VERSION ""

NS_ :

BS_:

BU_: VMM IMR BCS GSM EMS EPB SRS TEL ICM ACU VCU WCM TSCM Tester Test SCMRR SCMRL SCM SBM RCP PSDR PSDL PLGM PAS LCU IHU IBCM IAL HVSPRR HVSPRL HVSMR HVSM HVACF HUD GWM FRDCM FLDCM FCP FAPA ETC Diagnostic Messages AVAS AMP

BO_ 1015 ACU_HVSM_2_B: 8 IHU
 SG_ ACU_RRSeatOperationReq : 63|4@0+ (1,0) [0|15] "-"  SCMRL
 SG_ ACU_RRSeatOperationReqVD : 53|1@0+ (1,0) [0|1] "-"  SCMRL
 SG_ ACU_RLSeatOperationReqVD : 52|1@0+ (1,0) [0|1] "-"  SCMRL
 SG_ ACU_RLSeatOperationReq : 51|4@0+ (1,0) [0|15] "-"  SCMRL
 SG_ ACU_HVSMR_RRSeatHeatVentModeSt : 47|2@0+ (1,0) [0|3] "-"  HVSMR,SCMRL,HVSM
 SG_ ACU_HVSMR_RRSeatVentLevelReq : 45|3@0+ (1,0) [0|7] "-"  HVSMR,SCMRL,HVSM
 SG_ ACU_HVSMR_RRSeatHeatLevelReq : 42|3@0+ (1,0) [0|7] ""  HVSMR,SCMRL,HVSM
 SG_ ACU_HVSMR_RLSeatHeatVentModeSt : 39|2@0+ (1,0) [0|3] "-"  HVSMR,SCMRL,HVSM
 SG_ ACU_HVSMR_RLSeatVentLevelReq : 37|3@0+ (1,0) [0|7] "-"  HVSMR,SCMRL,HVSM
 SG_ ACU_HVSMR_RLSeatHeatLevelReq : 34|3@0+ (1,0) [0|7] ""  HVSMR,SCMRL,HVSM
 SG_ ACU_ORVMOperationReqVD : 31|1@0+ (1,0) [0|1] ""  FLDCM,FRDCM
 SG_ ACU_SeatSteeringWheelOpratReqVD : 30|1@0+ (1,0) [0|1] ""  SCM
 SG_ ACU_SVM_Button : 29|1@0+ (1,0) [0|1] ""  FAPA,GWM
 SG_ ACU_APA_Button : 28|1@0+ (1,0) [0|1] ""  FAPA,GWM
 SG_ ACU_ORVMOperationReq : 23|4@0+ (1,0) [0|15] "-"  FLDCM,FRDCM
 SG_ ACU_SeatSteeringWheelOpratReq : 19|4@0+ (1,0) [0|15] "-"  SCM
 SG_ ACU_HVSM_FRSeatHeatVentModeSt : 15|2@0+ (1,0) [0|3] "-"  SCM,HVSM
 SG_ ACU_HVSM_FRSeatVentLevelReq : 13|3@0+ (1,0) [0|7] "-"  SCM,HVSM
 SG_ ACU_HVSM_FRSeatHeatLevelReq : 10|3@0+ (1,0) [0|7] ""  HVSM
 SG_ ACU_HVSM_FLSeatHeatVentModeSt : 7|2@0+ (1,0) [0|3] "-"  SCM,HVSM
 SG_ ACU_HVSM_FLSeatVentLevelReq : 5|3@0+ (1,0) [0|7] "-"  SCM,HVSM
 SG_ ACU_HVSM_FLSeatHeatLevelReq : 2|3@0+ (1,0) [0|7] ""  SCM,HVSM

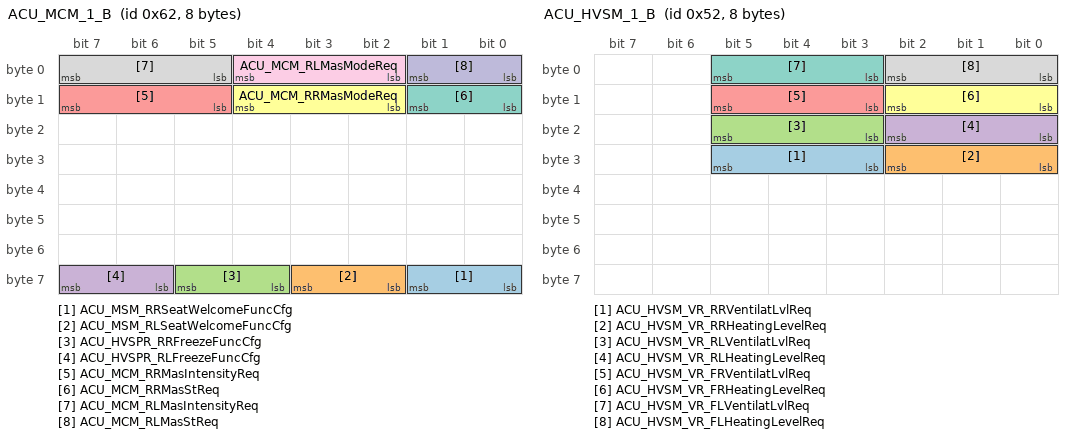
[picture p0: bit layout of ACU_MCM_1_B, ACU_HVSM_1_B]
BO_ 98 ACU_MCM_1_B: 8 IHU
 SG_ ACU_MSM_RRSeatWelcomeFuncCfg : 57|2@0+ (1,0) [0|3] ""  SCMRR
 SG_ ACU_MSM_RLSeatWelcomeFuncCfg : 59|2@0+ (1,0) [0|3] ""  SCMRL
 SG_ ACU_HVSPR_RRFreezeFuncCfg : 61|2@0+ (1,0) [0|3] ""  HVSPRR
 SG_ ACU_HVSPR_RLFreezeFuncCfg : 63|2@0+ (1,0) [0|3] ""  HVSPRL
 SG_ ACU_MCM_RRMasIntensityReq : 15|3@0+ (1,0) [0|7] "" Vector__XXX
 SG_ ACU_MCM_RRMasModeReq : 12|3@0+ (1,0) [0|7] "" Vector__XXX
 SG_ ACU_MCM_RRMasStReq : 9|2@0+ (1,0) [0|3] "" Vector__XXX
 SG_ ACU_MCM_RLMasIntensityReq : 7|3@0+ (1,0) [0|7] "" Vector__XXX
 SG_ ACU_MCM_RLMasModeReq : 4|3@0+ (1,0) [0|7] "" Vector__XXX
 SG_ ACU_MCM_RLMasStReq : 1|2@0+ (1,0) [0|3] "" Vector__XXX

BO_ 82 ACU_HVSM_1_B: 8 IHU
 SG_ ACU_HVSM_VR_RRVentilatLvlReq : 29|3@0+ (1,0) [0|7] "-"  HVSMR,SCMRL
 SG_ ACU_HVSM_VR_RRHeatingLevelReq : 26|3@0+ (1,0) [0|7] "-"  HVSMR,SCMRL
 SG_ ACU_HVSM_VR_RLVentilatLvlReq : 21|3@0+ (1,0) [0|7] "-"  HVSMR,SCMRL
 SG_ ACU_HVSM_VR_RLHeatingLevelReq : 18|3@0+ (1,0) [0|7] "-"  HVSMR,SCMRL
 SG_ ACU_HVSM_VR_FRVentilatLvlReq : 13|3@0+ (1,0) [0|7] "-"  SCM,HVSM
 SG_ ACU_HVSM_VR_FRHeatingLevelReq : 10|3@0+ (1,0) [0|7] "-"  SCM,HVSM
 SG_ ACU_HVSM_VR_FLVentilatLvlReq : 5|3@0+ (1,0) [0|7] "-"  SCM,HVSM
 SG_ ACU_HVSM_VR_FLHeatingLevelReq : 2|3@0+ (1,0) [0|7] "-"  SCM,HVSM

BO_ 836 ACU_PCS_1_B: 8 IHU
 SG_ PCS_MMIAPAFuncSelect : 63|2@0+ (1,0) [0|3] "" Vector__XXX
 SG_ PCS_MMIAPAConfirmButton : 61|2@0+ (1,0) [0|3] "" Vector__XXX
 SG_ PCS_PASButtonPress : 59|1@0+ (1,0) [0|1] ""  PAS
 SG_ PCS_ER_QuitReq : 58|1@0+ (1,0) [0|1] "" Vector__XXX
 SG_ PCS_ER_EnterConfirm : 57|1@0+ (1,0) [0|1] "" Vector__XXX
 SG_ PCS_ACU_DisplayReq : 56|1@0+ (1,0) [0|1] "" Vector__XXX
 SG_ PCS_SoundReminderSt : 55|1@0+ (1,0) [0|1] "" Vector__XXX
 SG_ PCS_BCM_ButtonLamp : 54|1@0+ (1,0) [0|1] ""  IBCM
 SG_ PCS_ReturnSt : 53|1@0+ (1,0) [0|1] "" Vector__XXX
 SG_ PCS_RightBlindSpotViewSt : 52|1@0+ (1,0) [0|1] "" Vector__XXX
 SG_ PCS_LeftBlindSpotViewSt : 51|1@0+ (1,0) [0|1] "" Vector__XXX
 SG_ PCS_RVMButtonGroup : 50|3@0+ (1,0) [0|7] "" Vector__XXX
 SG_ PCS_APASlotActiveSt : 47|3@0+ (1,0) [0|7] "" Vector__XXX
 SG_ PCS_APATurnLampReq : 44|2@0+ (1,0) [0|3] "" Vector__XXX
 SG_ PCS_APA_BackParkButton : 42|1@0+ (1,0) [0|1] "" Vector__XXX
 SG_ PCS_OperationSt : 41|2@0+ (1,0) [0|3] "" Vector__XXX
 SG_ PCS_3DEnalbe : 39|1@0+ (1,0) [0|1] "" Vector__XXX
 SG_ PCS_MODEnalbe : 38|1@0+ (1,0) [0|1] "" Vector__XXX
 SG_ PCS_PGSEnable : 37|1@0+ (1,0) [0|1] "" Vector__XXX
 SG_ PCS_SteerIconInd : 36|3@0+ (1,0) [0|7] "" Vector__XXX
 SG_ PCS_SteerWheelTurnDirInd : 33|2@0+ (1,0) [0|3] "" Vector__XXX
 SG_ PCS_GuidOverlaySt : 31|2@0+ (1,0) [0|3] "" Vector__XXX
 SG_ PCS_DriveDirInd : 29|2@0+ (1,0) [0|3] "" Vector__XXX
 SG_ PCS_VoiceReq : 27|4@0+ (1,0) [0|15] "" Vector__XXX
 SG_ PCS_SingleViewInd : 23|4@0+ (1,0) [0|15] ""  PAS
 SG_ PCS_HMIIndex : 19|4@0+ (1,0) [0|15] ""  PAS
 SG_ PCS_EventRecordSt : 15|1@0+ (1,0) [0|1] "" Vector__XXX
 SG_ PCS_CalibrateSt : 14|3@0+ (1,0) [0|7] "" Vector__XXX
 SG_ PCS_SystemType : 11|2@0+ (1,0) [0|3] "" Vector__XXX
 SG_ PCS_OverlayOpFail : 9|1@0+ (1,0) [0|1] "" Vector__XXX
 SG_ PCS_PGSOpFail : 8|1@0+ (1,0) [0|1] "" Vector__XXX
 SG_ PCS_FrontRightCameraFail : 7|1@0+ (1,0) [0|1] "" Vector__XXX
 SG_ PCS_FrontLeftCameraFail : 6|1@0+ (1,0) [0|1] "" Vector__XXX
 SG_ PCS_RearCameraFail : 5|1@0+ (1,0) [0|1] "" Vector__XXX
 SG_ PCS_RightCameraFail : 4|1@0+ (1,0) [0|1] "" Vector__XXX
 SG_ PCS_LeftCameraFail : 3|1@0+ (1,0) [0|1] "" Vector__XXX
 SG_ PCS_FrontCameraFail : 2|1@0+ (1,0) [0|1] "" Vector__XXX
 SG_ notsued1 : 1|1@0+ (1,0) [0|0] "" Vector__XXX
 SG_ PCS_SystemSt : 0|1@0+ (1,0) [0|1] "" Vector__XXX

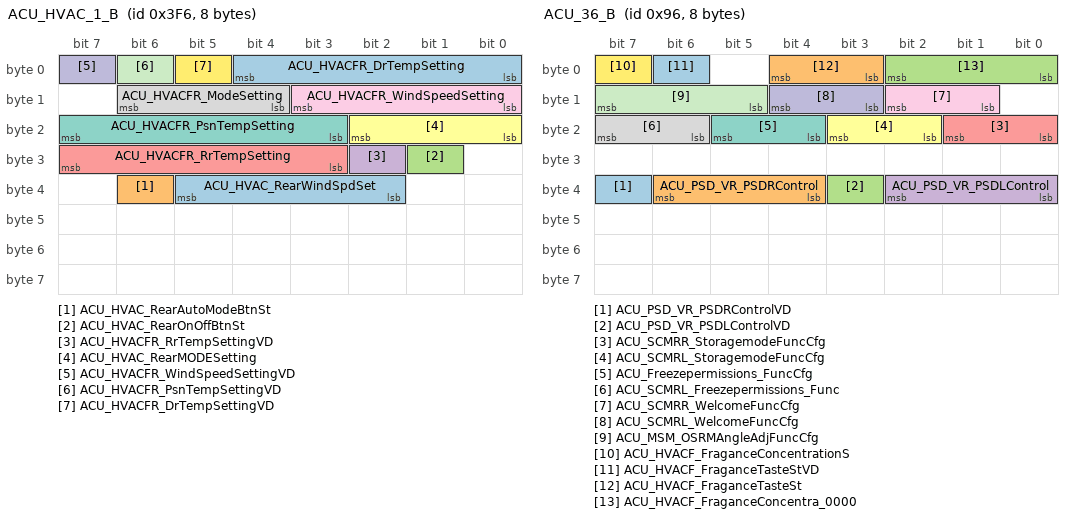
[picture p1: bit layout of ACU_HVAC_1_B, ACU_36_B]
BO_ 1014 ACU_HVAC_1_B: 8 IHU
 SG_ ACU_HVAC_RearWindSpdSet : 37|4@0+ (1,0) [0|15] ""  HVACF,GWM
 SG_ ACU_HVAC_RearAutoModeBtnSt : 38|1@0+ (1,0) [0|1] ""  HVACF,GWM
 SG_ ACU_HVAC_RearOnOffBtnSt : 25|1@0+ (1,0) [0|1] ""  HVACF,GWM
 SG_ ACU_HVACFR_RrTempSettingVD : 26|1@0+ (1,0) [0|1] ""  HVACF
 SG_ ACU_HVACFR_RrTempSetting : 31|5@0+ (0.5,18) [18|32] ""  HVACF,GWM
 SG_ ACU_HVAC_RearMODESetting : 18|3@0+ (1,0) [0|7] ""  HVACF,GWM
 SG_ ACU_HVACFR_PsnTempSetting : 23|5@0+ (0.5,18) [18|32] ""  HVACF,GWM
 SG_ ACU_HVACFR_ModeSetting : 14|3@0+ (1,0) [0|7] ""  HVACF,GWM
 SG_ ACU_HVACFR_WindSpeedSetting : 11|4@0+ (1,0) [0|7] ""  HVACF,GWM
 SG_ ACU_HVACFR_WindSpeedSettingVD : 7|1@0+ (1,0) [0|1] ""  HVACF
 SG_ ACU_HVACFR_PsnTempSettingVD : 6|1@0+ (1,0) [0|1] ""  HVACF
 SG_ ACU_HVACFR_DrTempSettingVD : 5|1@0+ (1,0) [0|1] ""  HVACF
 SG_ ACU_HVACFR_DrTempSetting : 4|5@0+ (0.5,18) [18|32] ""  HVACF,GWM

BO_ 150 ACU_36_B: 8 IHU
 SG_ ACU_PSD_VR_PSDRControlVD : 39|1@0+ (1,0) [0|1] ""  PSDR
 SG_ ACU_PSD_VR_PSDRControl : 38|3@0+ (1,0) [0|7] ""  PSDR
 SG_ ACU_PSD_VR_PSDLControlVD : 35|1@0+ (1,0) [0|1] ""  PSDL
 SG_ ACU_PSD_VR_PSDLControl : 34|3@0+ (1,0) [0|7] ""  PSDL
 SG_ ACU_SCMRR_StoragemodeFuncCfg : 17|2@0+ (1,0) [0|3] ""  SCMRR
 SG_ ACU_SCMRL_StoragemodeFuncCfg : 19|2@0+ (1,0) [0|3] ""  SCMRL
 SG_ ACU_Freezepermissions_FuncCfg : 21|2@0+ (1,0) [0|3] ""  SCMRR
 SG_ ACU_SCMRL_Freezepermissions_Func : 23|2@0+ (1,0) [0|3] ""  SCMRL
 SG_ ACU_SCMRR_WelcomeFuncCfg : 10|2@0+ (1,0) [0|3] ""  SCMRR
 SG_ ACU_SCMRL_WelcomeFuncCfg : 12|2@0+ (1,0) [0|3] ""  SCMRL
 SG_ ACU_MSM_OSRMAngleAdjFuncCfg : 15|3@0+ (1,0) [0|7] ""  FLDCM
 SG_ ACU_HVACF_FraganceConcentrationS : 7|1@0+ (1,0) [0|1] ""  HVACF
 SG_ ACU_HVACF_FraganceTasteStVD : 6|1@0+ (1,0) [0|1] ""  HVACF
 SG_ ACU_HVACF_FraganceTasteSt : 4|2@0+ (1,0) [0|3] ""  HVACF
 SG_ ACU_HVACF_FraganceConcentra_0000 : 2|3@0+ (1,0) [0|7] ""  HVACF

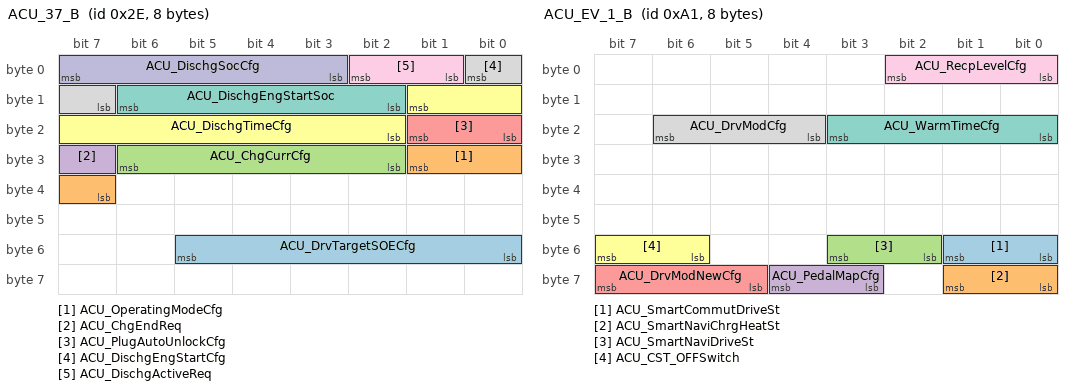
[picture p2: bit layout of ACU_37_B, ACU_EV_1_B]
BO_ 46 ACU_37_B: 8 IHU
 SG_ ACU_DrvTargetSOECfg : 53|6@0+ (1,0) [0|63] "kwh"  GWM
 SG_ ACU_OperatingModeCfg : 25|3@0+ (1,0) [0|7] ""  GWM
 SG_ ACU_ChgCurrCfg : 30|5@0+ (2,0) [0|32] "A"  GWM
 SG_ ACU_ChgEndReq : 31|1@0+ (1,0) [0|1] ""  GWM
 SG_ ACU_PlugAutoUnlockCfg : 17|2@0+ (1,0) [0|3] ""  GWM
 SG_ ACU_DischgTimeCfg : 9|8@0+ (5,0) [0|720] "min"  GWM
 SG_ ACU_DischgEngStartSoc : 14|5@0+ (5,0) [0|100] "%"  GWM
 SG_ ACU_DischgEngStartCfg : 0|2@0+ (1,0) [0|3] ""  GWM
 SG_ ACU_DischgActiveReq : 2|2@0+ (1,0) [0|3] ""  GWM
 SG_ ACU_DischgSocCfg : 7|5@0+ (5,0) [0|100] "%"  GWM

BO_ 161 ACU_EV_1_B: 8 IHU
 SG_ ACU_SmartCommutDriveSt : 49|2@0+ (1,0) [0|3] ""  GWM,VCU
 SG_ ACU_SmartNaviChrgHeatSt : 57|2@0+ (1,0) [0|3] ""  GWM,VCU
 SG_ ACU_SmartNaviDriveSt : 51|2@0+ (1,0) [0|3] ""  GWM
 SG_ ACU_PedalMapCfg : 60|2@0+ (1,0) [0|3] ""  BCS,GWM
 SG_ ACU_DrvModNewCfg : 63|3@0+ (1,0) [0|7] ""  GWM
 SG_ ACU_CST_OFFSwitch : 55|2@0+ (1,0) [0|3] ""  GWM
 SG_ ACU_WarmTimeCfg : 19|4@0+ (1,0) [0|15] ""  GWM
 SG_ ACU_DrvModCfg : 22|3@0+ (1,0) [0|7] ""  GWM
 SG_ ACU_RecpLevelCfg : 2|3@0+ (1,0) [0|7] "-"  GWM

BO_ 141 ACU_35_B: 8 IHU
 SG_ ACU_IMRCtrlReq : 47|2@0+ (1,0) [0|3] "" Vector__XXX
 SG_ ACU_WelLightmodleselect : 43|4@0+ (1,0) [0|15] "" Vector__XXX
 SG_ ACU_AutoHoldLightFunCfg : 45|2@0+ (1,0) [0|3] "" Vector__XXX
 SG_ ACU_HVACF_SmartSet : 31|2@0+ (1,0) [0|3] "" Vector__XXX
 SG_ ACU_ESACfg : 35|2@0+ (1,0) [0|3] ""  GWM
 SG_ ACU_HWAWDSwitchReq : 37|2@0+ (1,0) [0|3] ""  GWM
 SG_ ACU_FVDSwitchReq : 39|2@0+ (1,0) [0|3] ""  GWM
 SG_ ACU_TCH_VR_CuphdrHeatColAutMdSt : 29|2@0+ (1,0) [0|3] ""  IBCM
 SG_ ACU_TCH_VR_CupholderHeatCoolMdSt : 27|2@0+ (1,0) [0|3] ""  IBCM
 SG_ ACU_TCH_CupholdrHeatCoolAutoMdSt : 25|2@0+ (1,0) [0|3] ""  IBCM
 SG_ ACU_TCH_CupholderHeatCoolModeSt : 23|2@0+ (1,0) [0|3] ""  IBCM
 SG_ ACU_TCH_VR_CupholdrHeatCoolMdVD : 21|1@0+ (1,0) [0|1] ""  IBCM
 SG_ ACU_TCH_CupholderHeatCoolModeVD : 20|1@0+ (1,0) [0|1] ""  IBCM
 SG_ ACU_PSD_ModeSt : 19|2@0+ (1,0) [0|3] ""  PSDR,PSDL
 SG_ ACU_PSDR_SpdSet : 17|2@0+ (1,0) [0|3] ""  PSDR
 SG_ ACU_PSDL_SpdSet : 15|2@0+ (1,0) [0|3] ""  PSDL
 SG_ ACU_HVACF_EvapratorSelfCleanCfg : 13|2@0+ (1,0) [0|3] ""  HVACF
 SG_ ACU_HVACFUnlockVentilationCfg : 11|2@0+ (1,0) [0|3] ""  HVACF
 SG_ ACU_CancelMaintenanceCfg : 9|2@0+ (1,0) [0|3] "" Vector__XXX
 SG_ ACU_MaintenanceResetCfg : 6|2@0+ (1,0) [0|3] "" Vector__XXX
 SG_ ACU_MaintenanceCycleCfg : 4|3@0+ (1,0) [0|7] "" Vector__XXX
 SG_ ACU_SteeringHeatingReq : 1|2@0+ (1,0) [0|3] ""  GWM

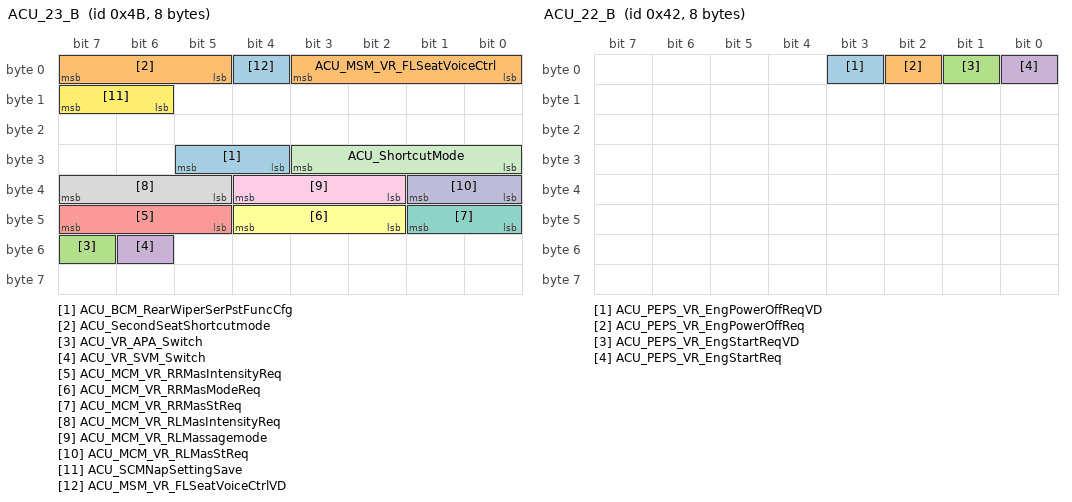
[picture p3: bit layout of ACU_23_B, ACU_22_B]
BO_ 75 ACU_23_B: 8 IHU
 SG_ ACU_BCM_RearWiperSerPstFuncCfg : 29|2@0+ (1,0) [0|3] ""  FLDCM,FRDCM,HVACF,HVSM,HVSPRL,HVSPRR,IAL,IBCM,SCM,SCMRL,SCMRR
 SG_ ACU_SecondSeatShortcutmode : 7|3@0+ (1,0) [0|7] "" Vector__XXX
 SG_ ACU_VR_APA_Switch : 55|1@0+ (1,0) [0|1] ""  FAPA,GWM
 SG_ ACU_VR_SVM_Switch : 54|1@0+ (1,0) [0|1] ""  FAPA,GWM
 SG_ ACU_MCM_VR_RRMasIntensityReq : 47|3@0+ (1,0) [0|7] ""  HVSPRR,IBCM
 SG_ ACU_MCM_VR_RRMasModeReq : 44|3@0+ (1,0) [0|7] ""  SCMRR,SCMRL
 SG_ ACU_MCM_VR_RRMasStReq : 41|2@0+ (1,0) [0|3] ""  IBCM
 SG_ ACU_MCM_VR_RLMasIntensityReq : 39|3@0+ (1,0) [0|7] ""  HVSPRL,IBCM
 SG_ ACU_MCM_VR_RLMassagemode : 36|3@0+ (1,0) [0|7] ""  IBCM
 SG_ ACU_MCM_VR_RLMasStReq : 33|2@0+ (1,0) [0|3] ""  IBCM
 SG_ ACU_ShortcutMode : 27|4@0+ (1,0) [0|15] "-"  HVSPRR,HVSPRL,SCMRR,SCMRL,FLDCM,FRDCM,SCM,IBCM,HVACF,IAL,HVSM
 SG_ ACU_SCMNapSettingSave : 15|2@0+ (1,0) [0|3] ""  FLDCM,FRDCM
 SG_ ACU_MSM_VR_FLSeatVoiceCtrlVD : 4|1@0+ (1,0) [0|1] ""  FLDCM
 SG_ ACU_MSM_VR_FLSeatVoiceCtrl : 3|4@0+ (1,0) [0|15] ""  FLDCM

BO_ 66 ACU_22_B: 8 IHU
 SG_ ACU_PEPS_VR_EngPowerOffReqVD : 3|1@0+ (1,0) [0|1] ""  IBCM
 SG_ ACU_PEPS_VR_EngPowerOffReq : 2|1@0+ (1,0) [0|1] ""  IBCM
 SG_ ACU_PEPS_VR_EngStartReqVD : 1|1@0+ (1,0) [0|1] ""  IBCM
 SG_ ACU_PEPS_VR_EngStartReq : 0|1@0+ (1,0) [0|1] ""  IBCM

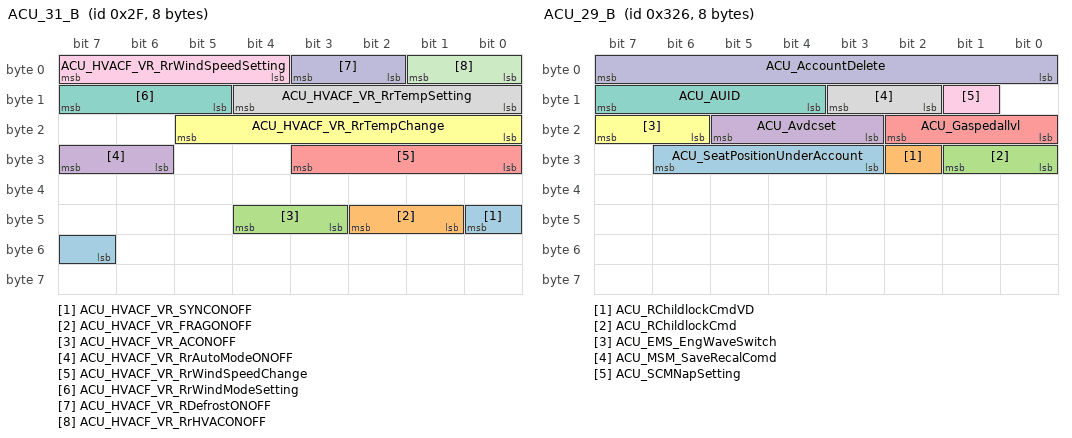
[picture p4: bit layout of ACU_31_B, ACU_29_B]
BO_ 47 ACU_31_B: 8 IHU
 SG_ ACU_HVACF_VR_SYNCONOFF : 40|2@0+ (1,0) [0|3] ""  HVACF,GWM
 SG_ ACU_HVACF_VR_FRAGONOFF : 42|2@0+ (1,0) [0|3] ""  HVACF
 SG_ ACU_HVACF_VR_ACONOFF : 44|2@0+ (1,0) [0|3] ""  HVACF,GWM
 SG_ ACU_HVACF_VR_RrAutoModeONOFF : 31|2@0+ (1,0) [0|3] ""  HVACF,GWM
 SG_ ACU_HVACF_VR_RrWindSpeedChange : 27|4@0+ (1,-6) [-6|6] ""  HVACF,GWM
 SG_ ACU_HVACF_VR_RrTempChange : 21|6@0+ (0.5,-14) [-14|17.5] "°C"  HVACF,GWM
 SG_ ACU_HVACF_VR_RrWindModeSetting : 15|3@0+ (1,0) [0|7] ""  HVACF,GWM
 SG_ ACU_HVACF_VR_RrTempSetting : 12|5@0+ (0.5,18) [18|32] "°C"  HVACF,GWM
 SG_ ACU_HVACF_VR_RrWindSpeedSetting : 7|4@0+ (1,0) [0|15] "-"  HVACF,GWM
 SG_ ACU_HVACF_VR_RDefrostONOFF : 3|2@0+ (1,0) [0|3] "-"  HVACF,GWM
 SG_ ACU_HVACF_VR_RrHVACONOFF : 1|2@0+ (1,0) [0|3] "-"  HVACF,GWM

BO_ 806 ACU_29_B: 8 IHU
 SG_ ACU_SeatPositionUnderAccount : 30|4@0+ (1,0) [0|15] ""  FLDCM,FRDCM,SCM
 SG_ ACU_RChildlockCmdVD : 26|1@0+ (1,0) [0|0] "" Vector__XXX
 SG_ ACU_RChildlockCmd : 25|2@0+ (1,0) [0|0] "" Vector__XXX
 SG_ ACU_Avdcset : 21|3@0+ (1,0) [0|5] ""  GWM
 SG_ ACU_Gaspedallvl : 18|3@0+ (1,0) [0|5] ""  GWM
 SG_ ACU_EMS_EngWaveSwitch : 23|2@0+ (1,0) [0|3] ""  GWM
 SG_ ACU_AUID : 15|4@0+ (1,0) [0|15] ""  FLDCM,FRDCM,GWM
 SG_ ACU_MSM_SaveRecalComd : 11|2@0+ (1,0) [0|3] ""  FLDCM,FRDCM,GWM
 SG_ ACU_SCMNapSetting : 9|1@0+ (1,0) [0|1] ""  FLDCM,FRDCM,GWM
 SG_ ACU_AccountDelete : 7|8@0+ (1,0) [0|255] ""  FLDCM,FRDCM,GWM

BO_ 603 ACU_25_B: 8 IHU
 SG_ ACU_25_B_Checksum : 63|8@0+ (1,0) [0|255] "-" Vector__XXX
 SG_ ACU_25_B_MsgCounter : 51|4@0+ (1,0) [0|15] "-" Vector__XXX
 SG_ ACU_BCM_VR_RightLaneChangeReqVD : 47|1@0+ (1,0) [0|1] "-" Vector__XXX
 SG_ ACU_BCM_VR_LeftLaneChangeReqVD : 46|1@0+ (1,0) [0|1] "-" Vector__XXX
 SG_ ACU_BCM_VR_RightTurnLampReqVD : 45|1@0+ (1,0) [0|1] "-" Vector__XXX
 SG_ ACU_BCM_VR_LeftTurnLampReqVD : 44|1@0+ (1,0) [0|1] "-" Vector__XXX
 SG_ ACU_BCM_VR_RightLaneChangeReq : 43|2@0+ (1,0) [0|3] "-" Vector__XXX
 SG_ ACU_BCM_VR_LeftLaneChangeReq : 41|2@0+ (1,0) [0|3] "-" Vector__XXX
 SG_ ACU_BCM_VR_TankcoverReqVD : 39|1@0+ (1,0) [0|1] "-" Vector__XXX
 SG_ ACU_BCM_VR_RearWasherReqVD : 38|1@0+ (1,0) [0|1] "-" Vector__XXX
 SG_ ACU_BCM_VR_FrontWasherReqVD : 37|1@0+ (1,0) [0|1] "-" Vector__XXX
 SG_ ACU_BCM_VR_RearWiperReqVD : 36|1@0+ (1,0) [0|1] "-" Vector__XXX
 SG_ ACU_BCM_VR_TankcoverReq : 35|2@0+ (1,0) [0|3] "-" Vector__XXX
 SG_ ACU_BCM_VR_RearWasherReq : 33|2@0+ (1,0) [0|3] "-" Vector__XXX
 SG_ ACU_BCM_VR_FrontWasherReq : 31|2@0+ (1,0) [0|3] "-" Vector__XXX
 SG_ ACU_BCM_VR_RearWiperReq : 29|2@0+ (1,0) [0|3] "-" Vector__XXX
 SG_ ACU_BCM_VR_FrontWiperReq : 27|2@0+ (1,0) [0|3] "-" Vector__XXX
 SG_ ACU_BCM_VR_RoomLampReq : 25|2@0+ (1,0) [0|3] "-" Vector__XXX
 SG_ ACU_BCM_VR_FrontWiperReqVD : 23|1@0+ (1,0) [0|1] "-" Vector__XXX
 SG_ ACU_BCM_VR_RoomLampReqVD : 22|1@0+ (1,0) [0|1] "-" Vector__XXX
 SG_ ACU_BCM_VR_RearFogLampReqVD : 21|1@0+ (1,0) [0|1] "-" Vector__XXX
 SG_ ACU_BCM_VR_FrontFogLampReqVD : 20|1@0+ (1,0) [0|1] "-" Vector__XXX
 SG_ ACU_BCM_VR_HighBeamReqVD : 19|1@0+ (1,0) [0|1] "-" Vector__XXX
 SG_ ACU_BCM_VR_LowBeamReqVD : 18|1@0+ (1,0) [0|1] "-" Vector__XXX
 SG_ ACU_BCM_VR_ParkingLampReqVD : 17|1@0+ (1,0) [0|1] "-" Vector__XXX
 SG_ ACU_BCM_VR_AmbientLightReqReqVD : 16|1@0+ (1,0) [0|1] "-" Vector__XXX
 SG_ ACU_BCM_VR_RearFogLampReq : 15|2@0+ (1,0) [0|3] "-" Vector__XXX
 SG_ ACU_BCM_VR_FrontFogLampReq : 13|2@0+ (1,0) [0|3] "-" Vector__XXX
 SG_ ACU_BCM_VR_HighBeamReq : 11|2@0+ (1,0) [0|3] "-" Vector__XXX
 SG_ ACU_BCM_VR_LowBeamReq : 9|2@0+ (1,0) [0|3] "-" Vector__XXX
 SG_ ACU_BCM_VR_RightTurnLampReq : 7|2@0+ (1,0) [0|3] "-" Vector__XXX
 SG_ ACU_BCM_VR_LeftTurnLampReq : 5|2@0+ (1,0) [0|3] "" Vector__XXX
 SG_ ACU_BCM_VR_ParkingLampReq : 3|2@0+ (1,0) [0|3] "" Vector__XXX
 SG_ ACU_BCM_VR_AmbientLightReqReq : 1|2@0+ (1,0) [0|3] "" Vector__XXX

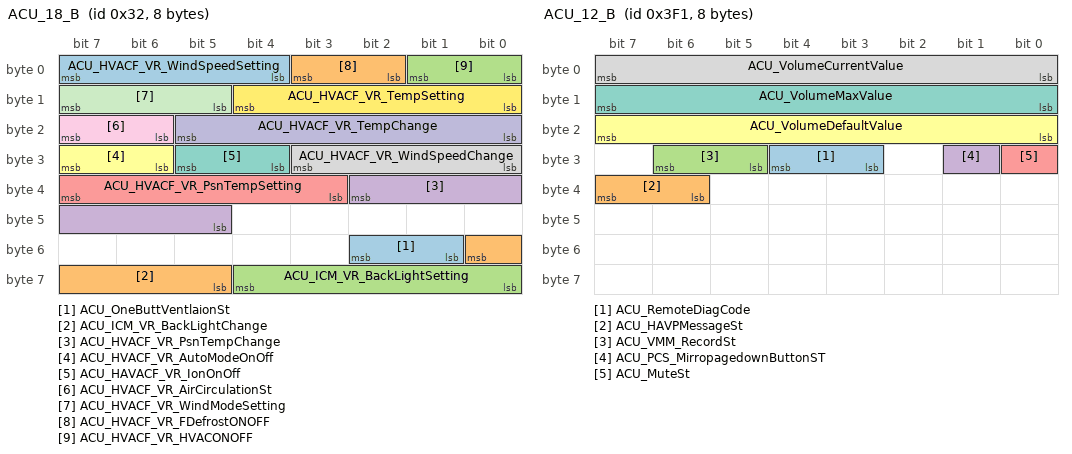
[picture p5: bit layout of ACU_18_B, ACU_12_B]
BO_ 50 ACU_18_B: 8 IHU
 SG_ ACU_OneButtVentlaionSt : 50|2@0+ (1,0) [0|3] "" Vector__XXX
 SG_ ACU_ICM_VR_BackLightChange : 48|4@0+ (1,-7) [-7|7] ""  GWM
 SG_ ACU_ICM_VR_BackLightSetting : 60|5@0+ (1,0) [0|63] ""  GWM
 SG_ ACU_HVACF_VR_PsnTempChange : 34|6@0+ (0.5,-14) [-14|14] "°C"  HVACF,GWM
 SG_ ACU_HVACF_VR_PsnTempSetting : 39|5@0+ (0.5,18) [18|31] "°C"  HVACF,GWM
 SG_ ACU_HVACF_VR_AutoModeOnOff : 31|2@0+ (1,0) [0|3] ""  HVACF,GWM
 SG_ ACU_HAVACF_VR_IonOnOff : 29|2@0+ (1,0) [0|3] ""  HVACF,GWM
 SG_ ACU_HVACF_VR_WindSpeedChange : 27|4@0+ (1,-6) [-6|9] ""  HVACF,GWM
 SG_ ACU_HVACF_VR_AirCirculationSt : 23|2@0+ (1,0) [0|3] ""  HVACF,GWM
 SG_ ACU_HVACF_VR_TempChange : 21|6@0+ (0.5,-14) [-14|17.5] "°C"  HVACF,GWM
 SG_ ACU_HVACF_VR_WindModeSetting : 15|3@0+ (1,0) [0|7] ""  HVACF,GWM
 SG_ ACU_HVACF_VR_TempSetting : 12|5@0+ (0.5,18) [18|33.5] "°C"  HVACF,GWM
 SG_ ACU_HVACF_VR_WindSpeedSetting : 7|4@0+ (1,0) [0|15] "-"  HVACF,GWM
 SG_ ACU_HVACF_VR_FDefrostONOFF : 3|2@0+ (1,0) [0|3] "-"  HVACF,GWM
 SG_ ACU_HVACF_VR_HVACONOFF : 1|2@0+ (1,0) [0|3] "-"  HVACF,GWM

BO_ 55 ACU_17_B: 8 IHU
 SG_ ACU_HeadlightDelayCfgSt : 61|2@0+ (1,0) [0|3] ""  IBCM
 SG_ ACU_IAL_ColorModeCfg : 59|4@0+ (1,0) [0|15] "" Vector__XXX
 SG_ ACU_HVACFUnlockVentilationCfg : 63|2@0+ (1,0) [0|3] ""  HVACF
 SG_ ACU_HVACF_EvapratorSelfCleanCfg : 49|2@0+ (1,0) [0|3] ""  HVACF
 SG_ ACU_ETC_BLEenableCfg : 55|2@0+ (1,0) [0|3] ""  ETC,GWM
 SG_ ACU_ETC_ICMDisplayCfg : 53|2@0+ (1,0) [0|3] ""  ETC,GWM
 SG_ ACU_ETC_SysCfg : 51|2@0+ (1,0) [0|3] ""  ETC,GWM
 SG_ ACU_IAL_HVACSeasonsKeyActive : 30|1@0+ (1,0) [0|1] "-"  GWM
 SG_ ACU_IAL_ColourChooseCfg : 29|2@0+ (1,0) [0|3] "-"  GWM
 SG_ ACU_MSM_OSRMAngleSave : 27|2@0+ (1,0) [0|1] "-"  FLDCM,FRDCM,GWM
 SG_ ACU_MSM_OSRMAngleAdjFuncCfg : 45|3@0+ (1,0) [0|7] "-"  FLDCM,GWM
 SG_ ACU_IAL_MusicModeCfg : 23|2@0+ (1,0) [0|3] "-"  GWM
 SG_ ACU_IAL_DriverModeCfg : 21|2@0+ (1,0) [0|3] "-"  GWM
 SG_ ACU_HVACF_PM25CleanReqFb : 19|2@0+ (1,0) [0|3] "-"  HVACF,GWM
 SG_ ACU_HVACF_PM25CleanReqCfg : 17|2@0+ (1,0) [0|3] "-"  HVACF,GWM
 SG_ ACU_HVACF_FanspeedCfg : 15|2@0+ (1,0) [0|3] "-"  HVACF,GWM
 SG_ ACU_IAL_ColorCfg : 13|6@0+ (1,0) [0|63] "-"  GWM
 SG_ ACU_IAL_BrightnessCfg : 7|6@0+ (1,0) [0|63] "-"  GWM
 SG_ ACU_IAL_FunctionCfg : 1|2@0+ (1,0) [0|3] "-"  GWM

BO_ 978 ACU_16_B: 8 IHU
 SG_ ACU_HVACF_FraganceConcentratStVD : 37|1@0+ (1,0) [0|0] "" Vector__XXX
 SG_ ACU_HVACF_FraganceTasteStVD : 36|1@0+ (1,0) [0|1] "" Vector__XXX
 SG_ ACU_HVACRr_FanDecBtnSt : 35|1@0+ (1,0) [0|0] "" Vector__XXX
 SG_ ACU_HVACRr_FanIncBtnSt : 34|1@0+ (1,0) [0|0] "" Vector__XXX
 SG_ ACU_HVACF_RearBtnStVD : 63|1@0+ (1,0) [0|1] "-"  HVACF
 SG_ ACU_HVACF_RearBtnSt : 62|1@0+ (1,0) [0|1] "-"  HVACF,GWM
 SG_ ACU_HVACF_FrsAirBtnStVD : 61|1@0+ (1,0) [0|1] "-"  HVACF
 SG_ ACU_HVACF_FrsAirBtnSt : 60|1@0+ (1,0) [0|1] "-"  HVACF,GWM
 SG_ ACU_HVACF_InnerCirBtnStVD : 59|1@0+ (1,0) [0|1] "-"  HVACF
 SG_ ACU_HVACF_InnerCirBtnSt : 58|1@0+ (1,0) [0|1] "-"  HVACF,GWM
 SG_ ACU_HVACF_TripleZoneBtnStVD : 57|1@0+ (1,0) [0|1] "-"  HVACF
 SG_ ACU_HVACF_TripleZoneBtnSt : 56|1@0+ (1,0) [0|1] "-"  HVACF,GWM
 SG_ ACU_HVACF_FRTempDecBtnStVD : 55|1@0+ (1,0) [0|1] "-"  HVACF
 SG_ ACU_HVACF_FRTempDecBtnSt : 54|1@0+ (1,0) [0|1] "-"  HVACF,GWM
 SG_ ACU_HVACF_FRTempIncBtnStVD : 53|1@0+ (1,0) [0|1] "-"  HVACF
 SG_ ACU_HVACF_FRTempIncBtnSt : 52|1@0+ (1,0) [0|1] "-"  HVACF,GWM
 SG_ ACU_HVACF_FLTempDecBtnStVD : 51|1@0+ (1,0) [0|1] "-"  HVACF
 SG_ ACU_HVACF_FLTempDecBtnSt : 50|1@0+ (1,0) [0|1] "-"  HVACF,GWM
 SG_ ACU_HVACF_FLTempIncBtnStVD : 49|1@0+ (1,0) [0|1] "-"  HVACF
 SG_ ACU_HVACF_FLTempIncBtnSt : 48|1@0+ (1,0) [0|1] "-"  HVACF,GWM
 SG_ ACU_HVACF_FraganceTasteSt : 33|2@0+ (1,0) [0|1] ""  HVACF,GWM
 SG_ ACU_HVACF_FraganceConcentratSt : 30|3@0+ (1,0) [0|1] ""  HVACF,GWM
 SG_ ACU_HVACR_TempDecBtnStVD : 27|1@0+ (1,0) [0|1] "-"  HVACF
 SG_ ACU_HVACR_TempDecBtnSt : 26|1@0+ (1,0) [0|1] "-"  HVACF,GWM
 SG_ ACU_HVACR_TempIncBtnStVD : 25|1@0+ (1,0) [0|1] "-"  HVACF
 SG_ ACU_HVACR_TempIncBtnSt : 24|1@0+ (1,0) [0|1] "-"  HVACF,GWM
 SG_ ACU_HVACF_ACMaxBtnStVD : 23|1@0+ (1,0) [0|1] "-"  HVACF
 SG_ ACU_HVACF_ACMaxBtnSt : 22|1@0+ (1,0) [0|1] "-"  HVACF,GWM
 SG_ ACU_HVACF_ACBtnStVD : 21|1@0+ (1,0) [0|1] "-"  HVACF
 SG_ ACU_HVACF_ACBtnSt : 20|1@0+ (1,0) [0|1] "-"  HVACF,GWM
 SG_ ACU_HVACF_CirBtnStVD : 19|1@0+ (1,0) [0|1] "-"  HVACF
 SG_ ACU_HVACF_CirBtnSt : 18|1@0+ (1,0) [0|1] "-"  HVACF,GWM
 SG_ ACU_HVACFR_FanDecBtnStVD : 17|1@0+ (1,0) [0|1] "-"  HVACF
 SG_ ACU_HVACFR_FanDecBtnSt : 16|1@0+ (1,0) [0|1] "-"  HVACF,GWM
 SG_ ACU_HVACFR_FanIncBtnStVD : 15|1@0+ (1,0) [0|1] "-"  HVACF
 SG_ ACU_HVACFR_FanIncBtnSt : 14|1@0+ (1,0) [0|1] "-"  HVACF,GWM
 SG_ ACU_HVACF_IonBtnStVD : 13|1@0+ (1,0) [0|1] "-"  HVACF
 SG_ ACU_HVACF_IonBtnSt : 12|1@0+ (1,0) [0|1] "-"  HVACF,GWM
 SG_ ACU_HVACF_DualBtnSyncStVD : 11|1@0+ (1,0) [0|1] "-"  HVACF
 SG_ ACU_HVACF_DualSyncBtnSt : 10|1@0+ (1,0) [0|1] "-"  HVACF,GWM
 SG_ ACU_HVACF_RDefrostBtnStVD : 9|1@0+ (1,0) [0|1] "-"  HVACF
 SG_ ACU_HVACF_RDefrostBtnSt : 8|1@0+ (1,0) [0|1] "-"  HVACF,GWM
 SG_ ACU_HVACF_FDefrostBtnStVD : 7|1@0+ (1,0) [0|1] "-"  HVACF
 SG_ ACU_HVACF_FDefrostBtnSt : 6|1@0+ (1,0) [0|1] "-"  HVACF,GWM
 SG_ ACU_HVACFR_ModeBtnStVD : 5|1@0+ (1,0) [0|1] "-"  HVACF
 SG_ ACU_HVACFR_ModeBtnSt : 4|1@0+ (1,0) [0|1] "-"  HVACF,GWM
 SG_ ACU_HVACFR_AutoModeBtnStVD : 3|1@0+ (1,0) [0|1] "-"  HVACF
 SG_ ACU_HVACFR_AutoModeBtnSt : 2|1@0+ (1,0) [0|1] "-"  HVACF,GWM
 SG_ ACU_HVACFR_OffBtnStVD : 1|1@0+ (1,0) [0|1] ""  HVACF
 SG_ ACU_HVACFR_OffBtnSt : 0|1@0+ (1,0) [0|1] ""  HVACF,GWM

BO_ 1009 ACU_12_B: 8 IHU
 SG_ ACU_RemoteDiagCode : 28|2@0+ (1,0) [0|3] "" Vector__XXX
 SG_ ACU_HAVPMessageSt : 39|2@0+ (1,0) [0|3] "" Vector__XXX
 SG_ ACU_VMM_RecordSt : 30|2@0+ (1,0) [0|3] ""  FAPA
 SG_ ACU_PCS_MirropagedownButtonST : 25|1@0+ (1,0) [0|1] ""  FAPA
 SG_ ACU_MuteSt : 24|1@0+ (1,0) [0|1] ""  GWM
 SG_ ACU_VolumeDefaultValue : 23|8@0+ (1,0) [0|255] ""  GWM
 SG_ ACU_VolumeMaxValue : 15|8@0+ (1,0) [0|255] ""  GWM
 SG_ ACU_VolumeCurrentValue : 7|8@0+ (1,0) [0|255] ""  GWM

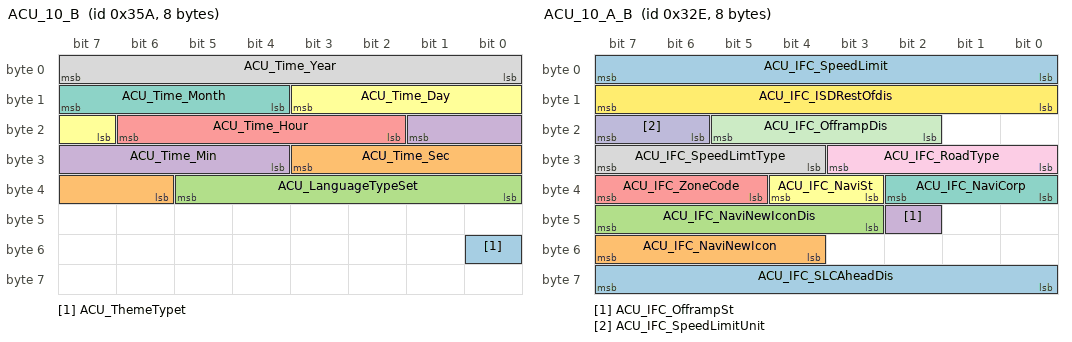
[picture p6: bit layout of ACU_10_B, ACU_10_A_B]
BO_ 858 ACU_10_B: 8 IHU
 SG_ ACU_ThemeTypet : 48|1@0+ (1,0) [0|1] ""  FAPA
 SG_ ACU_Time_Sec : 27|6@0+ (1,0) [0|59] "s"  LCU,FLDCM,FRDCM,IBCM,HVACF,SBM,PAS,FAPA,GWM
 SG_ ACU_LanguageTypeSet : 37|6@0+ (1,0) [0|63] ""  FAPA,GWM
 SG_ ACU_Time_Min : 17|6@0+ (1,0) [0|59] "min"  LCU,FLDCM,FRDCM,IBCM,HVACF,SBM,PAS,FAPA,GWM
 SG_ ACU_Time_Hour : 22|5@0+ (1,0) [0|23] "h"  LCU,FLDCM,FRDCM,IBCM,HVACF,SBM,PAS,FAPA,GWM
 SG_ ACU_Time_Day : 11|5@0+ (1,0) [1|31] "d"  LCU,FLDCM,FRDCM,IBCM,HVACF,SBM,PAS,FAPA,GWM
 SG_ ACU_Time_Month : 15|4@0+ (1,0) [1|12] "m"  LCU,FLDCM,FRDCM,IBCM,HVACF,SBM,PAS,FAPA,GWM
 SG_ ACU_Time_Year : 7|8@0+ (1,2000) [2000|2255] "y"  LCU,FLDCM,FRDCM,IBCM,HVACF,SBM,PAS,FAPA,GWM

BO_ 129 ACU_5_B: 8 IHU
 SG_ ACU_LightShowFunCmd : 33|2@0+ (1,0) [0|3] ""  LCU,GWM
 SG_ ACU_LightShowModeSel : 51|4@0+ (1,0) [0|15] ""  LCU,GWM
 SG_ ACU_LightShowTimeFlag : 63|8@0+ (1,0) [0|255] "s"  LCU,GWM
 SG_ ACU_GSM_DrvmodeMemCfg : 47|2@0+ (1,0) [0|3] ""  GWM
 SG_ ACU_XPowerModCfg : 45|4@0+ (1,0) [0|15] ""  GWM
 SG_ ACU_CDCStyleCfg : 39|3@0+ (1,0) [0|7] ""  GWM
 SG_ ACU_PAS_ButtonPress : 35|1@0+ (1,0) [0|1] ""  PAS,FAPA,GWM
 SG_ ACU_DriveMode : 31|4@0+ (1,0) [0|15] ""  GWM
 SG_ ACU_HDCFuncSwCfg : 27|2@0+ (1,0) [0|3] ""  GWM
 SG_ ACU_ESPFuncSwCfg : 25|2@0+ (1,0) [0|3] ""  GWM
 SG_ ACU_ADB_FunCfg : 23|2@0+ (1,0) [0|3] ""  LCU,GWM
 SG_ ACU_AEBOff : 21|2@0+ (1,0) [0|3] ""  GWM
 SG_ ACU_FCWOff : 19|2@0+ (1,0) [0|3] ""  GWM
 SG_ ACU_FCWWarnDistanceCfg : 17|2@0+ (1,0) [0|3] ""  GWM
 SG_ ACU_FCW_SeatbeltPretensionWarnCf : 15|2@0+ (1,0) [0|3] ""  GWM
 SG_ ACU_FCW_SeatVibrationWarnCfg : 13|2@0+ (1,0) [0|3] ""  GWM
 SG_ ACU_FCW_AcousticWarnCfg : 11|2@0+ (1,0) [0|3] ""  GWM
 SG_ ACU_ACC_StyleCfg : 9|2@0+ (1,0) [0|3] ""  GWM
 SG_ ACU_EPB_AutoModeCfg : 3|2@0+ (1,0) [0|3] ""  GWM
 SG_ ACU_EPS_StyleCfg : 1|2@0+ (1,0) [0|3] ""  GWM

BO_ 62 ACU_4_B: 8 IHU
 SG_ ACU_BCM_RLSAutoSRWinCloseCfgSt : 63|2@0+ (1,0) [0|3] ""  IBCM
 SG_ ACU_BCM_AutoSRWinCloseCfgSt : 61|2@0+ (1,0) [0|3] ""  IBCM
 SG_ ACU_BCM_HeadlightDelayCfgSt : 59|2@0+ (1,0) [0|3] ""  IBCM
 SG_ ACU_AVAS_SwitchCfgReq : 57|2@0+ (1,0) [0|3] "" Vector__XXX
 SG_ ACU_BCM_BCVehUnlockReq : 55|2@0+ (1,0) [0|3] ""  IBCM
 SG_ ACU_BCM_BCVehLockReq : 53|2@0+ (1,0) [0|3] ""  IBCM
 SG_ ACU_BCM_BCAutoDomeLightCtrl : 51|2@0+ (1,0) [0|3] ""  IBCM
 SG_ ACU_ICM_TripReset : 49|1@0+ (1,0) [0|1] "" Vector__XXX
 SG_ ACU_RearSeatBeltWarnCfg : 46|1@0+ (1,0) [0|1] "" Vector__XXX
 SG_ ACU_FuelEcoDistUnitDispSt : 45|2@0+ (1,0) [0|3] "" Vector__XXX
 SG_ ACU_PrUnitDispCfg : 43|2@0+ (1,0) [0|3] "" Vector__XXX
 SG_ ACU_TempUnitDispCfg : 41|2@0+ (1,0) [0|3] "" Vector__XXX
 SG_ ACU_PEPS_IdInVeWarningCfg : 39|2@0+ (1,0) [0|3] ""  IBCM
 SG_ ACU_MultiIDManageReq : 35|4@0+ (1,0) [0|15] "-"  SCM,IBCM,IAL,SBM
 SG_ ACU_BCM_AutoWiperCfg : 27|2@0+ (1,0) [0|3] ""  IBCM
 SG_ ACU_BCM_IALFuncCfg : 25|2@0+ (1,0) [0|3] ""  IBCM
 SG_ ACU_BCMHornCfg : 23|2@0+ (1,0) [0|3] ""  IBCM
 SG_ ACU_BCM_DTRLFuncCfg : 21|2@0+ (1,0) [0|3] ""  IBCM
 SG_ ACU_BCM_RGearEnableRearWipeCfg : 19|2@0+ (1,0) [0|3] ""  IBCM
 SG_ ACU_BCM_FrontWiperSerPstFuncCfg : 17|2@0+ (1,0) [0|3] ""  IBCM
 SG_ ACU_BCM_FrontWiperSerPstReq : 15|1@0+ (1,0) [0|1] ""  IBCM
 SG_ ACU_BCM_AutoLightSnsCfg : 14|3@0+ (1,0) [0|7] ""  IBCM
 SG_ ACU_BCM_FollowMeHomeCfg : 11|2@0+ (1,0) [0|3] ""  IBCM
 SG_ ACU_BCMAutoUnlockCfg : 9|2@0+ (1,0) [0|3] ""  IBCM
 SG_ ACU_BCMSpdAutoLockCfg : 7|2@0+ (1,0) [0|3] ""  IBCM
 SG_ ACU_BCMRemoteUnlockCfg : 5|2@0+ (1,0) [0|3] ""  IBCM
 SG_ ACU_BCM_FogLampTurnCfg : 3|2@0+ (1,0) [0|3] ""  IBCM
 SG_ ACU_BCM_RemoteCtrlFDMRMCfg : 1|2@0+ (1,0) [0|3] ""  IBCM

BO_ 61 ACU_2_B: 8 IHU
 SG_ ACU_PEPS_KickSnsCfg : 63|2@0+ (1,0) [0|3] ""  GWM
 SG_ ACU_PEPS_MaxTeleEngTimerCfg : 61|6@0+ (1,0) [0|30] "min"  GWM
 SG_ ACU_PEPS_OffCfg : 55|2@0+ (1,0) [0|3] ""  GWM
 SG_ ACU_PEPS_MaxTeleIGNOnTimerCfg : 53|6@0+ (1,0) [0|30] "min"  GWM
 SG_ ACU_PEPSAPUCfg : 47|2@0+ (1,0) [0|3] ""  IBCM,SBM,GWM
 SG_ ACU_PEPSWALCfg : 45|2@0+ (1,0) [0|3] ""  IBCM,SBM,GWM
 SG_ ACU_ICM_LanguageCfg : 43|2@0+ (1,0) [0|3] ""  GWM
 SG_ ACU_ICM_TimeModeCfg : 41|2@0+ (1,0) [0|3] ""  GWM
 SG_ ACU_ICM_WarnSoundVolCfg : 38|2@0+ (1,0) [0|3] ""  GWM
 SG_ ACU_ICM_SpdWarnCfg : 36|5@0+ (10,0) [0|200] "km/h"  GWM
 SG_ ACU_HVACF_AutoDefCfg : 30|3@0+ (1,0) [0|7] ""  HVACF,GWM
 SG_ ACU_HVACF_AQSCfg : 27|2@0+ (1,0) [0|3] ""  HVACF,GWM
 SG_ ACU_PEPSSATOCfg : 25|2@0+ (1,0) [0|3] ""  IBCM,SBM,GWM
 SG_ ACU_PEPS_WELCfg : 23|2@0+ (1,0) [0|3] ""  IBCM,SBM,GWM
 SG_ ACU_BCMOSRMAutoFoldCfg : 21|2@0+ (1,0) [0|3] ""  IBCM,GWM
 SG_ ACU_MSM_KeyRecognitionCfg : 19|2@0+ (1,0) [0|3] ""  FLDCM,GWM
 SG_ ACU_MSMWelcomeFuncCfg : 17|2@0+ (1,0) [0|3] ""  SCM,GWM
 SG_ ACU_RRHVSMAutoModeCfg : 15|2@0+ (1,0) [0|3] ""  HVSMR,SCMRL,GWM
 SG_ ACU_RLHVSMAutoModeCfg : 13|2@0+ (1,0) [0|3] ""  HVSMR,SCMRL,GWM
 SG_ ACU_FRHVSMAutoModeCfg : 11|2@0+ (1,0) [0|3] ""  SCM,HVSM,GWM
 SG_ ACU_FLHVSMAutoModeCfg : 9|2@0+ (1,0) [0|3] ""  SCM,HVSM,GWM
 SG_ ACU_HVACF_IonModeCfg : 7|2@0+ (1,0) [0|3] ""  HVACF,GWM
 SG_ ACU_HVACF_ComfortCfg : 5|2@0+ (1,0) [0|3] ""  HVACF,GWM
 SG_ ACU_HVACFAirCirCfg : 3|2@0+ (1,0) [0|3] ""  HVACF,GWM
 SG_ ACU_HVACF_ACCfg : 1|2@0+ (1,0) [0|3] ""  HVACF,GWM

BO_ 821 ACU_1_B: 8 IHU
 SG_ ACU_HUD_OffSt : 63|2@0+ (1,0) [0|3] ""  HUD,GWM
 SG_ ACU_TELBcallReq : 61|2@0+ (1,0) [0|3] "-"  GWM
 SG_ ACU_HUDADASCruiseDisReq : 59|2@0+ (1,0) [0|3] ""  HUD,GWM
 SG_ ACU_HUD_NAV : 57|2@0+ (1,0) [0|2] ""  HUD,GWM
 SG_ ACU_HUDADASTSRDisReq : 49|2@0+ (1,0) [0|3] ""  HUD,GWM
 SG_ ACU_HUD_BrightnessSt : 32|5@0+ (1,0) [0|31] ""  HUD,GWM
 SG_ ACU_SVMViewPosReq : 43|4@0+ (1,0) [0|15] ""  SBM,GWM
 SG_ ACU_ModeChangeInf : 39|1@0+ (1,0) [0|1] ""  GWM
 SG_ ACU_HUD_HeightSt : 37|5@0+ (1,0) [0|31] ""  HUD,GWM
 SG_ ACU_HUD_AngleSt : 30|5@0+ (1,0) [0|31] ""  HUD,SBM,GWM
 SG_ ACU_TeleModeActSt : 25|2@0+ (1,0) [0|3] ""  SBM,GWM
 SG_ ACU_CallMuteModeAct : 23|1@0+ (1,0) [0|1] ""  SBM,GWM
 SG_ ACU_SetupConfig : 22|2@0+ (1,0) [0|3] ""  GWM
 SG_ ACU_MusicSt : 20|1@0+ (1,0) [0|1] ""  IBCM
 SG_ ACU_KeyREWSt : 19|2@0+ (1,0) [0|3] ""  SBM,GWM
 SG_ ACU_KeyFFWSt : 17|2@0+ (1,0) [0|3] ""  SBM,GWM
 SG_ ACU_Key6St : 15|2@0+ (1,0) [0|3] ""  SBM,GWM
 SG_ ACU_Key5St : 13|2@0+ (1,0) [0|3] ""  SBM,GWM
 SG_ ACU_CallAnswerMode : 11|1@0+ (1,0) [0|1] ""  SBM,GWM
 SG_ ACU_PhoneCallReq : 10|3@0+ (1,0) [0|7] ""  SBM,GWM
 SG_ ACU_Key4St : 7|2@0+ (1,0) [0|3] ""  SBM,GWM
 SG_ ACU_Key3St : 5|2@0+ (1,0) [0|3] ""  SBM,GWM
 SG_ ACU_Key2St : 3|2@0+ (1,0) [0|3] ""  SBM,GWM
 SG_ ACU_Key1St : 1|2@0+ (1,0) [0|3] ""  SBM,GWM

BO_ 814 ACU_10_A_B: 8 IHU
 SG_ ACU_IFC_SLCAheadDis : 63|8@0+ (5,0) [0|1250] "m"  GWM
 SG_ ACU_IFC_NaviNewIcon : 55|4@0+ (1,0) [0|15] "-"  GWM
 SG_ ACU_IFC_NaviNewIconDis : 47|5@0+ (0.1,0) [0|2] "km"  GWM
 SG_ ACU_IFC_OfframpSt : 42|1@0+ (1,0) [0|1] "-"  GWM
 SG_ ACU_IFC_ZoneCode : 39|3@0+ (1,0) [0|7] "-"  GWM
 SG_ ACU_IFC_NaviSt : 36|2@0+ (1,0) [0|3] "-"  GWM
 SG_ ACU_IFC_NaviCorp : 34|3@0+ (1,0) [0|7] "-"  GWM
 SG_ ACU_IFC_SpeedLimtType : 31|4@0+ (1,0) [0|15] "-"  GWM
 SG_ ACU_IFC_RoadType : 27|4@0+ (1,0) [0|15] "-"  GWM
 SG_ ACU_IFC_SpeedLimitUnit : 23|2@0+ (1,0) [0|3] "-"  GWM
 SG_ ACU_IFC_OfframpDis : 21|4@0+ (100,0) [0|1400] "m"  GWM
 SG_ ACU_IFC_ISDRestOfdis : 15|8@0+ (1,0) [0|70] "km"  GWM
 SG_ ACU_IFC_SpeedLimit : 7|8@0+ (1,0) [0|255] "km/h"  GWM

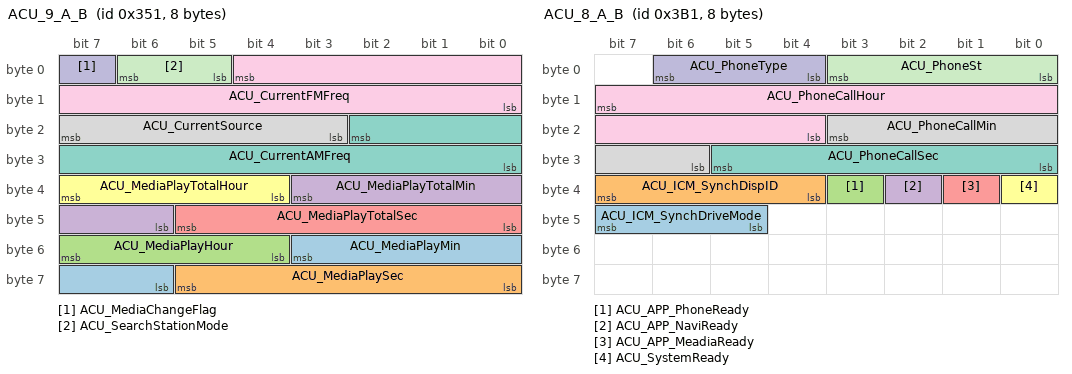
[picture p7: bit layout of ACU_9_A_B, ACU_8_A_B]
BO_ 849 ACU_9_A_B: 8 IHU
 SG_ ACU_MediaPlayMin : 51|6@0+ (1,0) [0|59] "min"  GWM
 SG_ ACU_MediaPlaySec : 61|6@0+ (1,0) [0|59] "s"  GWM
 SG_ ACU_MediaPlayHour : 55|4@0+ (1,0) [0|4095] "h"  GWM
 SG_ ACU_MediaPlayTotalMin : 35|6@0+ (1,0) [0|59] "min"  GWM
 SG_ ACU_MediaPlayTotalSec : 45|6@0+ (1,0) [0|59] "s"  GWM
 SG_ ACU_MediaPlayTotalHour : 39|4@0+ (1,0) [0|4095] "h"  GWM
 SG_ ACU_CurrentAMFreq : 18|11@0+ (1,144) [144|1710] "KHz"  GWM
 SG_ ACU_CurrentSource : 23|5@0+ (1,0) [0|31] ""  GWM
 SG_ ACU_CurrentFMFreq : 4|13@0+ (0.01,65) [65|108] "MHz"  GWM
 SG_ ACU_MediaChangeFlag : 7|1@0+ (1,0) [0|3] ""  GWM
 SG_ ACU_SearchStationMode : 6|2@0+ (1,0) [0|3] ""  GWM

BO_ 945 ACU_8_A_B: 8 IHU
 SG_ ACU_ICM_SynchDriveMode : 47|3@0+ (1,0) [0|7] ""  GWM
 SG_ ACU_ICM_SynchDispID : 39|4@0+ (1,0) [0|15] ""  GWM
 SG_ ACU_APP_PhoneReady : 35|1@0+ (1,0) [0|1] ""  GWM
 SG_ ACU_APP_NaviReady : 34|1@0+ (1,0) [0|1] ""  GWM
 SG_ ACU_APP_MeadiaReady : 33|1@0+ (1,0) [0|1] ""  GWM
 SG_ ACU_SystemReady : 32|1@0+ (1,0) [0|1] ""  GWM
 SG_ ACU_PhoneCallSec : 29|6@0+ (1,0) [0|59] "s"  GWM
 SG_ ACU_PhoneCallMin : 19|6@0+ (1,0) [0|59] "min"  GWM
 SG_ ACU_PhoneCallHour : 15|12@0+ (1,0) [0|4095] "h"  GWM
 SG_ ACU_PhoneType : 6|3@0+ (1,0) [0|7] ""  GWM
 SG_ ACU_PhoneSt : 3|4@0+ (1,0) [0|15] ""  GWM

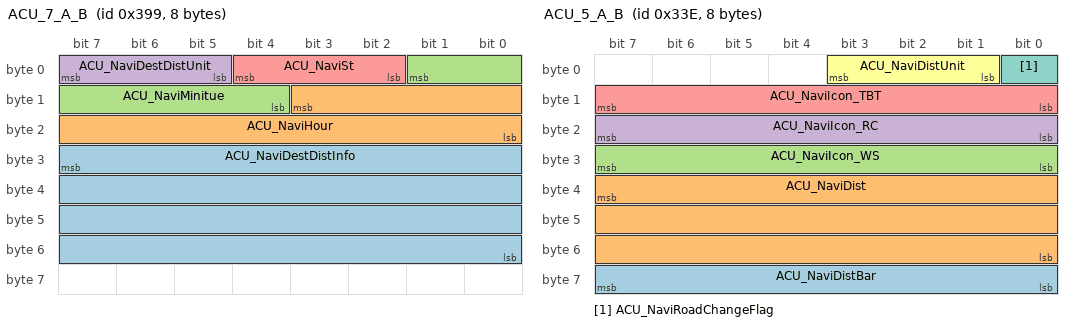
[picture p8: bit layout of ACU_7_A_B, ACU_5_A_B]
BO_ 921 ACU_7_A_B: 8 IHU
 SG_ ACU_NaviDestDistInfo : 31|32@0+ (1,0) [0|4294967295] "m" Vector__XXX
 SG_ ACU_NaviHour : 11|12@0+ (1,0) [0|4095] "h" Vector__XXX
 SG_ ACU_NaviMinitue : 1|6@0+ (1,0) [0|59] "min" Vector__XXX
 SG_ ACU_NaviDestDistUnit : 7|3@0+ (1,0) [0|3] "" Vector__XXX
 SG_ ACU_NaviSt : 4|3@0+ (1,0) [0|7] "" Vector__XXX

BO_ 911 ACU_6_A_B: 8 IHU
 SG_ ACU_CharacterTransData : 23|48@0+ (1,0) [0|281474976710660] "" Vector__XXX
 SG_ ACU_CharacterTransPCI : 7|16@0+ (1,0) [0|255] "" Vector__XXX

BO_ 830 ACU_5_A_B: 8 IHU
 SG_ ACU_NaviDistBar : 63|8@0+ (1,0) [0|100] "%"  GWM
 SG_ ACU_NaviDist : 39|24@0+ (1,0) [0|16777215] "m"  GWM
 SG_ ACU_NaviIcon_WS : 31|8@0+ (1,0) [0|255] ""  GWM
 SG_ ACU_NaviIcon_RC : 23|8@0+ (1,0) [0|255] ""  GWM
 SG_ ACU_NaviIcon_TBT : 15|8@0+ (1,0) [0|255] ""  GWM
 SG_ ACU_NaviDistUnit : 3|3@0+ (1,0) [0|7] ""  GWM
 SG_ ACU_NaviRoadChangeFlag : 0|1@0+ (1,0) [0|1] ""  GWM

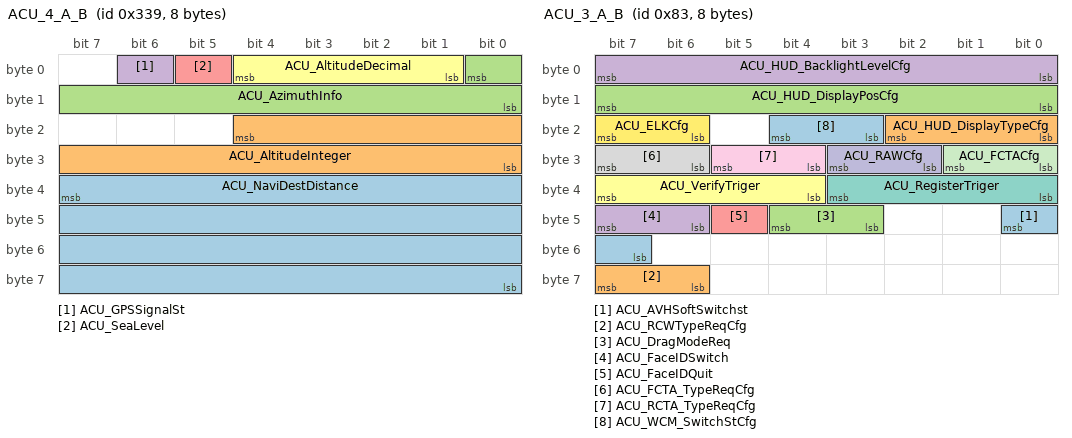
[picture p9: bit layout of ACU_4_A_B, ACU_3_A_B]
BO_ 825 ACU_4_A_B: 8 IHU
 SG_ ACU_NaviDestDistance : 39|32@0+ (1,0) [0|4294967295] ""  GWM
 SG_ ACU_AltitudeInteger : 20|13@0+ (1,0) [0|8000] ""  GWM
 SG_ ACU_AzimuthInfo : 0|9@0+ (1,0) [0|359] "°"  GWM
 SG_ ACU_GPSSignalSt : 6|1@0+ (1,0) [0|1] ""  GWM
 SG_ ACU_SeaLevel : 5|1@0+ (1,0) [0|1] ""  GWM
 SG_ ACU_AltitudeDecimal : 4|4@0+ (1,0) [0|9] ""  GWM

BO_ 131 ACU_3_A_B: 8 IHU
 SG_ ACU_AVHSoftSwitchst : 40|2@0+ (1,0) [0|2] ""  GWM
 SG_ ACU_RCWTypeReqCfg : 63|2@0+ (1,0) [0|3] ""  GWM
 SG_ ACU_DragModeReq : 44|2@0+ (1,0) [0|2] "-" Vector__XXX
 SG_ ACU_FaceIDSwitch : 47|2@0+ (1,0) [0|3] ""  GWM
 SG_ ACU_FaceIDQuit : 45|1@0+ (1,0) [0|1] ""  GWM
 SG_ ACU_VerifyTriger : 39|4@0+ (1,0) [0|15] ""  GWM
 SG_ ACU_RegisterTriger : 35|4@0+ (1,0) [0|15] ""  GWM
 SG_ ACU_FCTA_TypeReqCfg : 31|2@0+ (1,0) [0|3] ""  GWM
 SG_ ACU_RCTA_TypeReqCfg : 29|2@0+ (1,0) [0|3] ""  GWM
 SG_ ACU_RAWCfg : 27|2@0+ (1,0) [0|3] ""  GWM
 SG_ ACU_FCTACfg : 25|2@0+ (1,0) [0|3] ""  GWM
 SG_ ACU_ELKCfg : 23|2@0+ (1,0) [0|3] ""  GWM
 SG_ ACU_WCM_SwitchStCfg : 20|2@0+ (1,0) [0|3] ""  WCM
 SG_ ACU_HUD_DisplayTypeCfg : 18|3@0+ (1,0) [0|7] "" Vector__XXX
 SG_ ACU_HUD_DisplayPosCfg : 15|8@0+ (1,0) [0|255] "" Vector__XXX
 SG_ ACU_HUD_BacklightLevelCfg : 7|8@0+ (1,0) [0|255] "" Vector__XXX

BO_ 130 ACU_2_A_B: 8 IHU
 SG_ ACU_ADASVoicePromptSwitch : 39|1@0+ (1,0) [0|3] ""  GWM
 SG_ ACU_FaceID_Delete : 23|4@0+ (1,0) [0|15] "" Vector__XXX
 SG_ ACU_ADASWarnTypeSwitch : 57|2@0+ (1,0) [0|3] ""  GWM
 SG_ ACU_HWA_SwitchReq : 63|2@0+ (1,0) [0|3] ""  GWM
 SG_ ACU_RAEBcfg : 61|2@0+ (1,0) [0|3] ""  FAPA,GWM
 SG_ ACU_TSR_AudioWarnReq : 50|2@0+ (1,0) [0|3] ""  GWM
 SG_ ACU_DMSMode : 55|3@0+ (1,0) [0|7] ""  GWM
 SG_ ACU_DMSSwitch : 52|2@0+ (1,0) [0|3] ""  GWM
 SG_ ACU_iACC_SwitchReq : 47|2@0+ (1,0) [0|3] ""  GWM
 SG_ ACU_DOWCfg : 45|2@0+ (1,0) [0|3] ""  GWM
 SG_ ACU_RCTACfg : 43|2@0+ (1,0) [0|3] ""  GWM
 SG_ ACU_BSDCfg : 41|2@0+ (1,0) [0|3] ""  GWM
 SG_ ACU_IFC_SpeedLimtValueType : 33|2@0+ (1,0) [0|3] ""  GWM
 SG_ ACU_LKS_TypeReq : 17|2@0+ (1,0) [0|3] ""  GWM
 SG_ ACU_HMA_SwitchReq : 15|2@0+ (1,0) [0|3] ""  GWM
 SG_ ACU_TSR_SwitchReq : 13|2@0+ (1,0) [0|3] ""  GWM
 SG_ ACU_LKS_Sensitivity : 11|2@0+ (1,0) [0|3] ""  GWM
 SG_ ACU_IFC_CruiseModeCfg : 9|2@0+ (1,0) [0|3] ""  GWM
 SG_ ACU_SVM_RightBlindViewReq : 7|2@0+ (1,0) [0|3] ""  FAPA,GWM
 SG_ ACU_SVM_LeftBlindViewReq : 5|2@0+ (1,0) [0|3] ""  FAPA,GWM
 SG_ ACU_LDW_WarmSnsCfg : 3|2@0+ (1,0) [0|3] ""  GWM
 SG_ ACU_LDW_LKACfg : 1|2@0+ (1,0) [0|3] ""  GWM

BO_ 84 ACU_1_A_B: 8 IHU
 SG_ ACU_PCS_LadarTriggerSVMset : 55|2@0+ (1,0) [0|3] ""  FAPA
 SG_ ACU_PCS_TurnFollowSet : 53|2@0+ (1,0) [0|3] ""  FAPA
 SG_ ACU_PCS_ParkGearExitSet : 51|2@0+ (1,0) [0|3] ""  FAPA
 SG_ ACU_PCS_TrajectoryLineSet : 49|2@0+ (1,0) [0|3] ""  FAPA
 SG_ ACU_PCS_ScreenCoordX : 35|12@0+ (1,0) [0|1919] ""  FAPA,GWM
 SG_ ACU_PCS_ScreenCoordY : 31|12@0+ (1,0) [0|1079] ""  FAPA,GWM
 SG_ ACU_PCS_CurrentSceenSt : 22|1@0+ (1,0) [0|1] ""  FAPA
 SG_ ACU_PCS_ScreenTouchSt : 21|2@0+ (1,0) [0|3] ""  FAPA,GWM
 SG_ ACU_PCS_ER_QuitConfirm : 19|1@0+ (1,0) [0|1] ""  FAPA,GWM
 SG_ ACU_PCS_ER_EnterCmd : 18|1@0+ (1,0) [0|1] ""  FAPA,GWM
 SG_ ACU_ER_FuncCfg : 17|2@0+ (1,0) [0|3] ""  FAPA,GWM
 SG_ ACU_PCS_AdjParkPosCmd : 15|3@0+ (1,0) [0|7] ""  FAPA,GWM
 SG_ ACU_PCS_SVM_PGSReturnCmd : 12|1@0+ (1,0) [0|1] ""  FAPA,GWM
 SG_ ACU_PCS_SVM_SoundReminderCmd : 11|1@0+ (1,0) [0|1] ""  FAPA,GWM
 SG_ ACU_PCS_SVM_ViewModeCmd : 10|1@0+ (1,0) [0|1] ""  FAPA,GWM
 SG_ ACU_PCS_SVM_MODCmd : 9|1@0+ (1,0) [0|1] ""  FAPA,GWM
 SG_ ACU_PCS_SVM_PGSCmd : 8|1@0+ (1,0) [0|1] ""  FAPA,GWM
 SG_ ACU_PCS_SVM_SingleViewCmd : 7|4@0+ (1,0) [0|15] ""  FAPA,GWM
 SG_ ACU_PCS_SVM_FunctionCmd : 3|4@0+ (1,0) [0|15] ""  FAPA,GWM

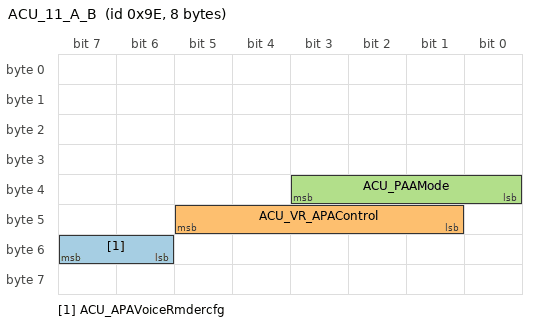
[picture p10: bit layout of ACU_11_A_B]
BO_ 158 ACU_11_A_B: 8 IHU
 SG_ ACU_APAVoiceRmdercfg : 55|2@0+ (1,0) [0|3] "" Vector__XXX
 SG_ ACU_VR_APAControl : 45|5@0+ (1,0) [0|31] "" Vector__XXX
 SG_ ACU_PAAMode : 35|4@0+ (1,0) [0|15] ""  FAPA

CM_ SG_ 1015 ACU_RRSeatOperationReq "Indicates ACU's soft switch for Rear Right seat operation request";
CM_ SG_ 1015 ACU_RRSeatOperationReqVD "Indicates ACU's soft switch for  Rear Right seat operation request valid status";
CM_ SG_ 1015 ACU_RLSeatOperationReqVD "Indicates ACU's soft switch for  Rear Left seat operation request valid status";
CM_ SG_ 1015 ACU_RLSeatOperationReq "Indicates ACU's soft switch for Rear Left seat operation request";
CM_ SG_ 1015 ACU_HVSMR_RRSeatHeatVentModeSt "IndicatesACU's Rear right seat heating/ventilation mode status";
CM_ SG_ 1015 ACU_HVSMR_RRSeatVentLevelReq "IndicatesACU's Rear right seat ventilationlevel request";
CM_ SG_ 1015 ACU_HVSMR_RRSeatHeatLevelReq "IndicatesACU's Rear right seat heatinglevel request";
CM_ SG_ 1015 ACU_HVSMR_RLSeatHeatVentModeSt "IndicatesACU's Rear left seat heating/ventilationmode status";
CM_ SG_ 1015 ACU_HVSMR_RLSeatVentLevelReq "IndicatesACU's Rear left seat ventilationlevel request";
CM_ SG_ 1015 ACU_HVSMR_RLSeatHeatLevelReq "IndicatesACU's Rear left seat heatinglevel request";
CM_ SG_ 1015 ACU_ORVMOperationReqVD "Indicates ACU's soft switch for outer rearview mirror operation request valid status";
CM_ SG_ 1015 ACU_SeatSteeringWheelOpratReqVD "Indicates ACU's soft switch for seat and steering wheel operation request valid status";
CM_ SG_ 1015 ACU_SVM_Button "SVM button press status";
CM_ SG_ 1015 ACU_APA_Button "APA Function activation Press Status";
CM_ SG_ 1015 ACU_ORVMOperationReq "Indicates ACU's soft switch for outer rearview mirror operation request";
CM_ SG_ 1015 ACU_SeatSteeringWheelOpratReq "Indicates ACU's soft switch for seat and steering wheel operation request";
CM_ SG_ 1015 ACU_HVSM_FRSeatHeatVentModeSt "IndicatesACU's front right seat heating/ventilation mode status";
CM_ SG_ 1015 ACU_HVSM_FRSeatVentLevelReq "IndicatesACU's front right seat ventilation
level request";
CM_ SG_ 1015 ACU_HVSM_FRSeatHeatLevelReq "IndicatesACU's front right seat heating 
level request";
CM_ SG_ 1015 ACU_HVSM_FLSeatHeatVentModeSt "IndicatesACU's front left seat heating/ventilation mode status";
CM_ SG_ 1015 ACU_HVSM_FLSeatVentLevelReq "IndicatesACU's front left seat ventilation
level request";
CM_ SG_ 1015 ACU_HVSM_FLSeatHeatLevelReq "IndicatesACU's front left seat heating 
level request";
CM_ SG_ 98 ACU_MSM_RRSeatWelcomeFuncCfg "Configurates Rear Right Seat Welcome function";
CM_ SG_ 98 ACU_MSM_RLSeatWelcomeFuncCfg "Configurates Rear Left Seat Welcome function";
CM_ SG_ 98 ACU_HVSPR_RRFreezeFuncCfg "Function configuration command Freeze";
CM_ SG_ 98 ACU_HVSPR_RLFreezeFuncCfg "Function configuration command Freeze";
CM_ SG_ 98 ACU_MCM_RRMasIntensityReq "ACU Rear right seat Massage intensity request";
CM_ SG_ 98 ACU_MCM_RRMasModeReq "ACU Rear right seat Massage mode request";
CM_ SG_ 98 ACU_MCM_RRMasStReq "ACU Rear right MCMmassage status Request";
CM_ SG_ 98 ACU_MCM_RLMasIntensityReq "ACU Rear left seat Massage intensity request";
CM_ SG_ 98 ACU_MCM_RLMasModeReq "ACU Rear left seat Massage mode request";
CM_ SG_ 98 ACU_MCM_RLMasStReq "ACU Rear left MCMmassage status Request";
CM_ SG_ 82 ACU_HVSM_VR_RRVentilatLvlReq "Rear Right seat ventilating level request";
CM_ SG_ 82 ACU_HVSM_VR_RRHeatingLevelReq "Rear right seat heating level request";
CM_ SG_ 82 ACU_HVSM_VR_RLVentilatLvlReq "Rear Left seat ventilating level request";
CM_ SG_ 82 ACU_HVSM_VR_RLHeatingLevelReq "Rear left seat heating level request";
CM_ SG_ 82 ACU_HVSM_VR_FRVentilatLvlReq "Front right seat ventilating level request";
CM_ SG_ 82 ACU_HVSM_VR_FRHeatingLevelReq "Front right seat heating level request";
CM_ SG_ 82 ACU_HVSM_VR_FLVentilatLvlReq "Front left seat ventilating level request";
CM_ SG_ 82 ACU_HVSM_VR_FLHeatingLevelReq "Front left seat heating level request";
CM_ SG_ 836 PCS_MMIAPAFuncSelect "APA Function select";
CM_ SG_ 836 PCS_MMIAPAConfirmButton "APA Confirm button";
CM_ SG_ 836 PCS_PASButtonPress "PAS button press status";
CM_ SG_ 836 PCS_ER_QuitReq "Event record quit request";
CM_ SG_ 836 PCS_ER_EnterConfirm "Event record enter comfirm";
CM_ SG_ 836 PCS_ACU_DisplayReq "ACU display request";
CM_ SG_ 836 PCS_SoundReminderSt "Sound reminder status";
CM_ SG_ 836 PCS_BCM_ButtonLamp "Help menu status";
CM_ SG_ 836 PCS_ReturnSt "Return status";
CM_ SG_ 836 PCS_RightBlindSpotViewSt "Indication right side blind spot view  turn off/on status";
CM_ SG_ 836 PCS_LeftBlindSpotViewSt "Indication left side blind spot view  turn off/on status";
CM_ SG_ 836 PCS_RVMButtonGroup "RVM button group";
CM_ SG_ 836 PCS_APASlotActiveSt "which slot is active";
CM_ SG_ 836 PCS_APATurnLampReq "PCS Turn Lamp Request";
CM_ SG_ 836 PCS_APA_BackParkButton "PCS  Back Park Button State";
CM_ SG_ 836 PCS_OperationSt "Used to indicate the current status of PCS";
CM_ SG_ 836 PCS_3DEnalbe "Indicate status of 3D SVM function";
CM_ SG_ 836 PCS_MODEnalbe "Indicate status of MOD(Moving Object Detection) function";
CM_ SG_ 836 PCS_PGSEnable "Indicate status of parking guidance function";
CM_ SG_ 836 PCS_SteerIconInd "Steering wheel angle icon indication";
CM_ SG_ 836 PCS_SteerWheelTurnDirInd "indicate the turnning direction of steering wheel";
CM_ SG_ 836 PCS_GuidOverlaySt "show the current status of guidance overlay";
CM_ SG_ 836 PCS_DriveDirInd "Drive direction indication";
CM_ SG_ 836 PCS_VoiceReq "Voice request, used to indicate whiceh voice should be played";
CM_ SG_ 836 PCS_SingleViewInd "Single view indication, used to indicate the current single view";
CM_ SG_ 836 PCS_HMIIndex "HMI index,used to indicate the current HMI index";
CM_ SG_ 836 PCS_EventRecordSt "Indication event record  turn off/on status";
CM_ SG_ 836 PCS_CalibrateSt "Indication the calibration status";
CM_ SG_ 836 PCS_SystemType "System type";
CM_ SG_ 836 PCS_OverlayOpFail "Overlay could not perate normally,the corresponding buttons shall be shown as grey";
CM_ SG_ 836 PCS_PGSOpFail "PGS could not perate normally,the corresponding buttons shall be shown as grey";
CM_ SG_ 836 PCS_FrontRightCameraFail "Front right camera failure";
CM_ SG_ 836 PCS_FrontLeftCameraFail "Front left camera failure";
CM_ SG_ 836 PCS_RearCameraFail "Rear camera failure";
CM_ SG_ 836 PCS_RightCameraFail "Right camera failure";
CM_ SG_ 836 PCS_LeftCameraFail "Left camera failure";
CM_ SG_ 836 PCS_FrontCameraFail "Front camera failure";
CM_ SG_ 836 PCS_SystemSt "System status";
CM_ SG_ 1014 ACU_HVAC_RearWindSpdSet "Set Rear wind speed to HVAC";
CM_ SG_ 1014 ACU_HVAC_RearAutoModeBtnSt "Indicates ACU's rear HVAC Auto button press status";
CM_ SG_ 1014 ACU_HVAC_RearOnOffBtnSt "Indicates ACU's rear HVAC ON/OFF button press status";
CM_ SG_ 1014 ACU_HVACFR_RrTempSettingVD "Indicates signal
ACU_HVACFR_RrTempSetting validity";
CM_ SG_ 1014 ACU_HVACFR_RrTempSetting "Turn to RrTemp xxx ℃ to HVAC";
CM_ SG_ 1014 ACU_HVAC_RearMODESetting "The rear wind exit mode";
CM_ SG_ 1014 ACU_HVACFR_PsnTempSetting "Turn to PaTemp xxx ℃ to HVAC";
CM_ SG_ 1014 ACU_HVACFR_ModeSetting "The wind exit mode";
CM_ SG_ 1014 ACU_HVACFR_WindSpeedSetting "Setting FrWind Speed to HVAC";
CM_ SG_ 1014 ACU_HVACFR_WindSpeedSettingVD "Indicates signal
ACU_HVACFR_WindSpeedSetting validity";
CM_ SG_ 1014 ACU_HVACFR_PsnTempSettingVD "Indicates signal
ACU_HVACFR_PsnTempSetting validity";
CM_ SG_ 1014 ACU_HVACFR_DrTempSettingVD "Indicates signal
ACU_HVACFR_DrTempSetting validity";
CM_ SG_ 1014 ACU_HVACFR_DrTempSetting "Turn to DrTemp xxx ℃ to HVAC";
CM_ SG_ 150 ACU_PSD_VR_PSDRControlVD "Indicates signal ACU_PSD_VR_PSDR Control
 validity";
CM_ SG_ 150 ACU_PSD_VR_PSDRControl "Control the PSDR action by VR.";
CM_ SG_ 150 ACU_PSD_VR_PSDLControlVD "Indicates signal ACU_PSD_VR_PSDL Control
 validity";
CM_ SG_ 150 ACU_PSD_VR_PSDLControl "Control the PSDL action by VR.";
CM_ SG_ 150 ACU_SCMRR_StoragemodeFuncCfg "RR seat storage command";
CM_ SG_ 150 ACU_SCMRL_StoragemodeFuncCfg "RL seat storage command";
CM_ SG_ 150 ACU_Freezepermissions_FuncCfg "Freeze RR seat function";
CM_ SG_ 150 ACU_SCMRL_Freezepermissions_Func "Freeze RL seat function";
CM_ SG_ 150 ACU_SCMRR_WelcomeFuncCfg "Configurates SCMRR welcome function";
CM_ SG_ 150 ACU_SCMRL_WelcomeFuncCfg "Configurates SCMRL welcome function";
CM_ SG_ 150 ACU_MSM_OSRMAngleAdjFuncCfg "Configurate outside rear view mirror angleadjust function";
CM_ SG_ 150 ACU_HVACF_FraganceConcentrationS "Indicates signal
ACU_HVAC_FraganceConcentrationt validity";
CM_ SG_ 150 ACU_HVACF_FraganceTasteStVD "Indicates signal ACU_HVAC_FraganceSwitchSt
validity";
CM_ SG_ 150 ACU_HVACF_FraganceTasteSt "Air Fragance Taste choose";
CM_ SG_ 150 ACU_HVACF_FraganceConcentra_0000 "Air Fragance Concentration";
CM_ BO_ 46 "a8e新增2";
CM_ SG_ 46 ACU_OperatingModeCfg "vehicle operating mode configuration";
CM_ SG_ 46 ACU_DischgTimeCfg "discharge once longest time configuration";
CM_ SG_ 46 ACU_DischgEngStartSoc "Engine start SOC point configuration in discharge";
CM_ SG_ 46 ACU_DischgEngStartCfg "Engine start permission configuration in discharge";
CM_ SG_ 46 ACU_DischgActiveReq "Discharge active request";
CM_ SG_ 46 ACU_DischgSocCfg "discharge ending SOC point configuration";
CM_ SG_ 161 ACU_DrvModCfg "Driving mode function configuration on AVNT screen";
CM_ SG_ 161 ACU_RecpLevelCfg "Recuperation level configuration";
CM_ SG_ 141 ACU_ESACfg "Configurates ESA function";
CM_ SG_ 141 ACU_HWAWDSwitchReq "HWAWD(Wisdom Deviation) switch signal";
CM_ SG_ 141 ACU_FVDSwitchReq "FVD(Front Vehicle Distance) switch
signal";
CM_ SG_ 141 ACU_TCH_VR_CuphdrHeatColAutMdSt "Cupholder heating/cooling AutoMode mode status";
CM_ SG_ 141 ACU_TCH_VR_CupholderHeatCoolMdSt "IndicatesACU's Cupholder heating/cooling mode status";
CM_ SG_ 141 ACU_TCH_CupholdrHeatCoolAutoMdSt "Cupholder heating/cooling AutoMode mode status";
CM_ SG_ 141 ACU_TCH_CupholderHeatCoolModeSt "IndicatesACU's Cupholder heating/cooling mode status";
CM_ SG_ 141 ACU_TCH_VR_CupholdrHeatCoolMdVD "Cupholder heating/cooling mode valid data";
CM_ SG_ 141 ACU_TCH_CupholderHeatCoolModeVD "Cupholder heating/cooling mode valid data";
CM_ SG_ 141 ACU_PSD_ModeSt "Mode state of PSD";
CM_ SG_ 141 ACU_PSDR_SpdSet "Set the speed of PSD";
CM_ SG_ 141 ACU_PSDL_SpdSet "Set the speed of PSD";
CM_ SG_ 141 ACU_HVACF_EvapratorSelfCleanCfg "Drying condition during lock set";
CM_ SG_ 141 ACU_HVACFUnlockVentilationCfg "Unlock Ventilation Set";
CM_ SG_ 141 ACU_CancelMaintenanceCfg "ACU setting the repeat alert status";
CM_ SG_ 141 ACU_MaintenanceResetCfg "ACU setting reset maintenance reminder";
CM_ SG_ 141 ACU_MaintenanceCycleCfg "ACU setting the maintenance alert cycle";
CM_ SG_ 141 ACU_SteeringHeatingReq "Steering wheel heating request";
CM_ SG_ 75 ACU_VR_APA_Switch "Turn on or turn off APA by VR";
CM_ SG_ 75 ACU_VR_SVM_Switch "Turn on or turn off SVM by VR";
CM_ SG_ 75 ACU_MCM_VR_RRMasIntensityReq "ACU Rear right seat Massage intensity request";
CM_ SG_ 75 ACU_MCM_VR_RRMasModeReq "ACU Rear right seat Massage mode request";
CM_ SG_ 75 ACU_MCM_VR_RRMasStReq "ACU Rear right MCMmassage status Request";
CM_ SG_ 75 ACU_MCM_VR_RLMasIntensityReq "ACU Rear left seat Massage intensity request";
CM_ SG_ 75 ACU_MCM_VR_RLMassagemode "ACU Rear left seat Massage mode request";
CM_ SG_ 75 ACU_MCM_VR_RLMasStReq "ACU Rear left MCMmassage status Request";
CM_ SG_ 75 ACU_ShortcutMode "Setting Shortcut Mode";
CM_ SG_ 75 ACU_SCMNapSettingSave "Save or Cancel Nap Mode Setting";
CM_ SG_ 75 ACU_MSM_VR_FLSeatVoiceCtrlVD "Indicates signal ACU_MSM_VR_FLSeatVoiceCtrl validity";
CM_ SG_ 75 ACU_MSM_VR_FLSeatVoiceCtrl "Driver seat voice control";
CM_ SG_ 66 ACU_PEPS_VR_EngPowerOffReqVD "Indicates signal ACU_PEPS_VR_EngPowerOffReq validity";
CM_ SG_ 66 ACU_PEPS_VR_EngPowerOffReq "Turn off Engine by VR";
CM_ SG_ 66 ACU_PEPS_VR_EngStartReqVD "Indicates signal ACU_PEPS_VR_EngStartReq validity";
CM_ SG_ 66 ACU_PEPS_VR_EngStartReq "Start Engine by VR";
CM_ SG_ 47 ACU_HVACF_VR_SYNCONOFF "Turn on SYNC mode By VR";
CM_ SG_ 47 ACU_HVACF_VR_FRAGONOFF "Turn on FRAG By VR";
CM_ SG_ 47 ACU_HVACF_VR_ACONOFF "Turn on AC By VR";
CM_ SG_ 47 ACU_HVACF_VR_RrAutoModeONOFF "Turn on or turn off AutoMode by VR";
CM_ SG_ 47 ACU_HVACF_VR_RrWindSpeedChange "Increase OR decrease wind speed by VR";
CM_ SG_ 47 ACU_HVACF_VR_RrTempChange "Increase OR decrease xxx ℃ by VR";
CM_ SG_ 47 ACU_HVACF_VR_RrWindModeSetting "Setting wind mode by VR";
CM_ SG_ 47 ACU_HVACF_VR_RrTempSetting "Turn to xxx ℃ by VR";
CM_ SG_ 47 ACU_HVACF_VR_RrWindSpeedSetting "Setting wind speed by VR";
CM_ SG_ 47 ACU_HVACF_VR_RDefrostONOFF "Open or close FDefrost by VR";
CM_ SG_ 47 ACU_HVACF_VR_RrHVACONOFF "Turn on or turn off Rear HVAC By VR";
CM_ SG_ 806 ACU_Avdcset "AVDC mode setting";
CM_ SG_ 806 ACU_Gaspedallvl "Gas pedal level setting";
CM_ SG_ 806 ACU_EMS_EngWaveSwitch "EMS Engine wave Switch";
CM_ SG_ 806 ACU_AUID "The current account ID";
CM_ SG_ 806 ACU_MSM_SaveRecalComd "Driver position Save Recall and Command";
CM_ SG_ 806 ACU_SCMNapSetting "Start Setting SCM Nap Mode";
CM_ SG_ 806 ACU_AccountDelete "Account delete information";
CM_ SG_ 603 ACU_25_B_MsgCounter "The message counter is a 0-15 counter, increased of one unit on every message transmission";
CM_ SG_ 603 ACU_BCM_VR_RightLaneChangeReqVD "ACU_BCM_VR_RightLaneChangeReq valid value";
CM_ SG_ 603 ACU_BCM_VR_LeftLaneChangeReqVD "ACU_BCM_VR_LeftLaneChangeReq valid value";
CM_ SG_ 603 ACU_BCM_VR_RightTurnLampReqVD "ACU_BCM_VR_RightTurnLampReq valid value";
CM_ SG_ 603 ACU_BCM_VR_LeftTurnLampReqVD "ACU_BCM_VR_LeftTurnLampReq valid value";
CM_ SG_ 603 ACU_BCM_VR_RightLaneChangeReq "Change right lane by VR";
CM_ SG_ 603 ACU_BCM_VR_LeftLaneChangeReq "Change left lane by VR";
CM_ SG_ 603 ACU_BCM_VR_TankcoverReqVD "Indicates signal ACU_BCM_VR_TankcoverReq validity";
CM_ SG_ 603 ACU_BCM_VR_RearWasherReqVD "Indicates signal
ACU_BCM_VR_RearWasherReq validity";
CM_ SG_ 603 ACU_BCM_VR_FrontWasherReqVD "Indicates signal
ACU_BCM_VR_FrontWasherReq validity";
CM_ SG_ 603 ACU_BCM_VR_RearWiperReqVD "Indicates signal
ACU_BCM_VR_RearWiperReq validity";
CM_ SG_ 603 ACU_BCM_VR_TankcoverReq "Open Tankcover by VR";
CM_ SG_ 603 ACU_BCM_VR_RearWasherReq "Turn on or turn off RearWasher by VR";
CM_ SG_ 603 ACU_BCM_VR_FrontWasherReq "Turn on or turn off FrontWasher by VR";
CM_ SG_ 603 ACU_BCM_VR_RearWiperReq "Turn on or turn off RearWiper by VR";
CM_ SG_ 603 ACU_BCM_VR_FrontWiperReq "Control FrontWiper by VR";
CM_ SG_ 603 ACU_BCM_VR_RoomLampReq "Turn on or turn off DomeLight by VR";
CM_ SG_ 603 ACU_BCM_VR_FrontWiperReqVD "Indicates signal
ACU_BCM_VR_FrontWiperReq validity";
CM_ SG_ 603 ACU_BCM_VR_RoomLampReqVD "Indicates signal  ACU_BCM_VR_RoomLampReq
 validity";
CM_ SG_ 603 ACU_BCM_VR_RearFogLampReqVD "Indicates signal
ACU_BCM_VR_RearFogLampReq validity";
CM_ SG_ 603 ACU_BCM_VR_FrontFogLampReqVD "Indicates signal
ACU_BCM_VR_FrontFogLampReq validity";
CM_ SG_ 603 ACU_BCM_VR_HighBeamReqVD "Indicates signal
ACU_BCM_VR_HighBeamReq validity";
CM_ SG_ 603 ACU_BCM_VR_LowBeamReqVD "Indicates signal
ACU_BCM_VR_LowBeamReq validity";
CM_ SG_ 603 ACU_BCM_VR_ParkingLampReqVD "Indicates signal  ACU_BCM_VR_ParkingLampReq validity";
CM_ SG_ 603 ACU_BCM_VR_AmbientLightReqReqVD "Indicates signal
ACU_BCM_VR_AmbientLightReq validity";
CM_ SG_ 603 ACU_BCM_VR_RearFogLampReq "Turn on or turn off RearFogLamp by VR";
CM_ SG_ 603 ACU_BCM_VR_FrontFogLampReq "Turn on or turn off FrontFogLamp by VR";
CM_ SG_ 603 ACU_BCM_VR_HighBeamReq "Turn on or turn off HighBeam by VR";
CM_ SG_ 603 ACU_BCM_VR_LowBeamReq "Turn on or turn off LowBeam by VR";
CM_ SG_ 603 ACU_BCM_VR_RightTurnLampReq "Turn on Rightturnlamp by VR";
CM_ SG_ 603 ACU_BCM_VR_LeftTurnLampReq "Turn on Leftturnlamp by VR";
CM_ SG_ 603 ACU_BCM_VR_ParkingLampReq "Turn on or turn off ParkingLamp by VR";
CM_ SG_ 603 ACU_BCM_VR_AmbientLightReqReq "Turn on or turn off AmbientLight by VR";
CM_ SG_ 50 ACU_ICM_VR_BackLightChange "Increase or decrease back light level by VR";
CM_ SG_ 50 ACU_ICM_VR_BackLightSetting "Set back light level by VR";
CM_ SG_ 50 ACU_HVACF_VR_PsnTempChange "Increase OR decrease PsnTEMP xxx ℃ by VR";
CM_ SG_ 50 ACU_HVACF_VR_PsnTempSetting "Turn to PsnTEMP xxx ℃ by VR";
CM_ SG_ 50 ACU_HVACF_VR_AutoModeOnOff "Turn on or turn off AutoMode by VR";
CM_ SG_ 50 ACU_HAVACF_VR_IonOnOff "Turn on or turn off Ionclean Funtion by VR";
CM_ SG_ 50 ACU_HVACF_VR_WindSpeedChange "Increase OR decrease wind speed by VR";
CM_ SG_ 50 ACU_HVACF_VR_AirCirculationSt "Airconditionor air circulation state";
CM_ SG_ 50 ACU_HVACF_VR_TempChange "Increase OR decrease xxx ℃ by VR";
CM_ SG_ 50 ACU_HVACF_VR_WindModeSetting "Setting wind mode by VR";
CM_ SG_ 50 ACU_HVACF_VR_TempSetting "Turn to xxx ℃ by VR";
CM_ SG_ 50 ACU_HVACF_VR_WindSpeedSetting "Setting wind speed by VR";
CM_ SG_ 50 ACU_HVACF_VR_FDefrostONOFF "Open or close FDefrost by VR";
CM_ SG_ 50 ACU_HVACF_VR_HVACONOFF "Turn on or turn off HVAC by VR";
CM_ SG_ 55 ACU_HeadlightDelayCfgSt "Confige Headlight Delay Function";
CM_ SG_ 55 ACU_IAL_ColorModeCfg "IAL color mode configuration";
CM_ SG_ 55 ACU_HVACFUnlockVentilationCfg "Configurates Unlock Ventilation function";
CM_ SG_ 55 ACU_HVACF_EvapratorSelfCleanCfg "Configurates Evaprator Self Clean function";
CM_ SG_ 55 ACU_ETC_BLEenableCfg "configurates ETC Bluetooth function Enable & Disable";
CM_ SG_ 55 ACU_ETC_ICMDisplayCfg "configurates ETC infomation display on ICM function Enable & Disable";
CM_ SG_ 55 ACU_ETC_SysCfg "configurates ETC System Enable & Disable";
CM_ SG_ 55 ACU_IAL_HVACSeasonsKeyActive "HVAC seasons key active";
CM_ SG_ 55 ACU_IAL_ColourChooseCfg "Colour choose configuration";
CM_ SG_ 55 ACU_MSM_OSRMAngleSave "Configurate outside rear view mirror angle save command";
CM_ SG_ 55 ACU_MSM_OSRMAngleAdjFuncCfg "Configurate outside rear view mirror angle adjust function";
CM_ SG_ 55 ACU_IAL_MusicModeCfg "Music mode  configuration";
CM_ SG_ 55 ACU_IAL_DriverModeCfg "Drive mode for display configuration";
CM_ SG_ 55 ACU_HVACF_PM25CleanReqFb "PM2.5 Clean Req Feedback from the ACU";
CM_ SG_ 55 ACU_HVACF_PM25CleanReqCfg "Configurates PM25CleanReq Set";
CM_ SG_ 55 ACU_HVACF_FanspeedCfg "Configurates HVAC Fan speed of AUTO  mode";
CM_ SG_ 55 ACU_IAL_ColorCfg "IAL(Interior Ambient Light)  color configuration";
CM_ SG_ 55 ACU_IAL_BrightnessCfg "IAL(Interior Ambient Light) brightness configuration";
CM_ SG_ 55 ACU_IAL_FunctionCfg "IAL(Interior Ambient Light) function activated";
CM_ SG_ 978 ACU_HVACF_RearBtnStVD "Indicates signal
ACU_HVACF_RearBtnSt validity";
CM_ SG_ 978 ACU_HVACF_RearBtnSt "HVACF REAR button status";
CM_ SG_ 978 ACU_HVACF_FrsAirBtnStVD "Indicates signal
ACU_HVACF_FrsAirBtnSt validity";
CM_ SG_ 978 ACU_HVACF_FrsAirBtnSt "Indicates ACU's HVACF outer circulation button press status";
CM_ SG_ 978 ACU_HVACF_InnerCirBtnStVD "Indicates signal
ACU_HVACF_InnerCirBtnSt validity";
CM_ SG_ 978 ACU_HVACF_InnerCirBtnSt "Indicates ACU's HVACF inner circulation button press status";
CM_ SG_ 978 ACU_HVACF_TripleZoneBtnStVD "Indicates signal ACU_HVACF_TripleZoneBtnSt validity";
CM_ SG_ 978 ACU_HVACF_TripleZoneBtnSt "Indicates ACU's HVACF triple zone  button press status";
CM_ SG_ 978 ACU_HVACF_FRTempDecBtnStVD "Indicates signal ACU_HVACF_FRTempDecBtnSt validity";
CM_ SG_ 978 ACU_HVACF_FRTempDecBtnSt "indicates ACU's HVACF right side temperature decrease button pressed";
CM_ SG_ 978 ACU_HVACF_FRTempIncBtnStVD "Indicates signal ACU_HVACF_FRTempIncBtnSt validity";
CM_ SG_ 978 ACU_HVACF_FRTempIncBtnSt "indicates ACU's HVACF front right side temperature increase button pressed";
CM_ SG_ 978 ACU_HVACF_FLTempDecBtnStVD "Indicates signal ACU_HVACF_FTempDecBtnSt validity";
CM_ SG_ 978 ACU_HVACF_FLTempDecBtnSt "indicates ACU's HVACF front left side temperature decrease button pressed";
CM_ SG_ 978 ACU_HVACF_FLTempIncBtnStVD "Indicates signal ACU_HVACF__FTempIncBtnSt validity";
CM_ SG_ 978 ACU_HVACF_FLTempIncBtnSt "indicates ACU's HVACF front left side temperature increase button pressed";
CM_ SG_ 978 ACU_HVACF_FraganceTasteSt "Indicates ACU's HVACF Rear  FAN decrease button press status";
CM_ SG_ 978 ACU_HVACF_FraganceConcentratSt "Indicates ACU's HVACF Rear FAN increase button press status";
CM_ SG_ 978 ACU_HVACR_TempDecBtnStVD "Indicates signal ACU_HVACR_TempDecBtnSt validity";
CM_ SG_ 978 ACU_HVACR_TempDecBtnSt "indicates ACU's HVACR temperature decrease button pressed";
CM_ SG_ 978 ACU_HVACR_TempIncBtnStVD "Indicates signal ACU_HVACR_TempIncBtnSt validity";
CM_ SG_ 978 ACU_HVACR_TempIncBtnSt "indicates ACU's HVACR temperature increase button pressed";
CM_ SG_ 978 ACU_HVACF_ACMaxBtnStVD "Indicates signal ACU_HVACF_ACMaxBtnSt validity";
CM_ SG_ 978 ACU_HVACF_ACMaxBtnSt "Indicates ACU's HVACF A/C max button status";
CM_ SG_ 978 ACU_HVACF_ACBtnStVD "Indicates signal ACU_HVACF_ACBtnSt validity";
CM_ SG_ 978 ACU_HVACF_ACBtnSt "Indicates ACU's HVACF A/C button status";
CM_ SG_ 978 ACU_HVACF_CirBtnStVD "Indicates signal ACU_HVACF_CirBtnSt validity";
CM_ SG_ 978 ACU_HVACF_CirBtnSt "Indicates ACU's HVACF circulation button press status";
CM_ SG_ 978 ACU_HVACFR_FanDecBtnStVD "Indicates signal ACU_HVACF_FanDecBtnSt validity";
CM_ SG_ 978 ACU_HVACFR_FanDecBtnSt "Indicates ACU's HVACF FAN decrease button press status";
CM_ SG_ 978 ACU_HVACFR_FanIncBtnStVD "Indicates signal ACU_HVACF_FanIncBtnSt validity";
CM_ SG_ 978 ACU_HVACFR_FanIncBtnSt "Indicates ACU's HVACF FAN increase button press status";
CM_ SG_ 978 ACU_HVACF_IonBtnStVD "Indicates signal ACU_HVACF_IonBtnSt validity";
CM_ SG_ 978 ACU_HVACF_IonBtnSt "Indicates  ACU's HVACF ION button press status";
CM_ SG_ 978 ACU_HVACF_DualBtnSyncStVD "Indicates signal ACU_HVACF_DualSyncBtnSt validity";
CM_ SG_ 978 ACU_HVACF_DualSyncBtnSt "Indicates ACU's HVACF DUAL/Sync button press status";
CM_ SG_ 978 ACU_HVACF_RDefrostBtnStVD "Indicates signal ACU_HVACF_RDefrostBtnSt validity";
CM_ SG_ 978 ACU_HVACF_RDefrostBtnSt "Indicates ACU's HVACF rear defrost  button press status";
CM_ SG_ 978 ACU_HVACF_FDefrostBtnStVD "Indicates signal ACU_HVACF_FDefrostBtnSt validity";
CM_ SG_ 978 ACU_HVACF_FDefrostBtnSt "Indicates ACU's HVACF front defrost  button press status";
CM_ SG_ 978 ACU_HVACFR_ModeBtnStVD "Indicates signal ACU_HVAC_ModeBtnSt validity";
CM_ SG_ 978 ACU_HVACFR_ModeBtnSt "Indicates ACU's HVAC MODE button press status";
CM_ SG_ 978 ACU_HVACFR_AutoModeBtnStVD "Indicates signal ACU_HVAC_AutoModeBtnSt validity";
CM_ SG_ 978 ACU_HVACFR_AutoModeBtnSt "Indicates ACU's HVAC  AUTO mode button press status";
CM_ SG_ 978 ACU_HVACFR_OffBtnStVD "Indicates signal ACU_HVAC_OffBtnSt validity";
CM_ SG_ 978 ACU_HVACFR_OffBtnSt "Indicates ACU's HVAC  OFF button press status";
CM_ SG_ 1009 ACU_VMM_RecordSt "ACU SVM Screen mode";
CM_ SG_ 1009 ACU_PCS_MirropagedownButtonST "Mirropagedown button status";
CM_ SG_ 1009 ACU_MuteSt "Mute status";
CM_ SG_ 1009 ACU_VolumeDefaultValue "Default volume value";
CM_ SG_ 1009 ACU_VolumeMaxValue "Max volume value";
CM_ SG_ 1009 ACU_VolumeCurrentValue "Current volume value";
CM_ SG_ 858 ACU_ThemeTypet "AVNT theme type";
CM_ SG_ 858 ACU_Time_Sec "Second number";
CM_ SG_ 858 ACU_LanguageTypeSet "language type set";
CM_ SG_ 858 ACU_Time_Min "Minute number";
CM_ SG_ 858 ACU_Time_Hour "Hour number";
CM_ SG_ 858 ACU_Time_Day "Day number";
CM_ SG_ 858 ACU_Time_Month "Month number";
CM_ SG_ 858 ACU_Time_Year "Year number";
CM_ SG_ 129 ACU_LightShowFunCmd "Light show function command";
CM_ SG_ 129 ACU_LightShowModeSel "Light show mode selection";
CM_ SG_ 129 ACU_LightShowTimeFlag "Light show synchronizing signal";
CM_ SG_ 129 ACU_GSM_DrvmodeMemCfg "GSM drive mode Memory configure status";
CM_ SG_ 129 ACU_CDCStyleCfg "Configurates the style of CDC";
CM_ SG_ 129 ACU_PAS_ButtonPress "PAS button press state";
CM_ SG_ 129 ACU_DriveMode "ACU Drive mode";
CM_ SG_ 129 ACU_HDCFuncSwCfg "HDC function switch configuration";
CM_ SG_ 129 ACU_ESPFuncSwCfg "ESP function switch  configuration";
CM_ SG_ 129 ACU_ADB_FunCfg "Configurate ADB function";
CM_ SG_ 129 ACU_AEBOff "AEB is turned off";
CM_ SG_ 129 ACU_FCWOff "FCW is turned off";
CM_ SG_ 129 ACU_FCWWarnDistanceCfg "Configurates FCW(Front Collision Warning) warning distance";
CM_ SG_ 129 ACU_FCW_SeatbeltPretensionWarnCf "Configurates FCW(Front Collision Warning) seatbelt pretension warning";
CM_ SG_ 129 ACU_FCW_SeatVibrationWarnCfg "Configurates FCW(Front Collision Warning) seat vibration warning";
CM_ SG_ 129 ACU_FCW_AcousticWarnCfg "Configurates FCW(Front Collision Warning) acoustic warning";
CM_ SG_ 129 ACU_ACC_StyleCfg "Configurates ACC(Adapt Crusie Control) style";
CM_ SG_ 129 ACU_EPB_AutoModeCfg "Configurates EPB auto mode";
CM_ SG_ 129 ACU_EPS_StyleCfg "Configurates the style of EPS";
CM_ SG_ 62 ACU_BCM_RLSAutoSRWinCloseCfgSt "ACU Automactic Sunroof/Window Close configuration status in rain";
CM_ SG_ 62 ACU_BCM_AutoSRWinCloseCfgSt "ACU Automactic Sunroof/Window Close configuration status of locking";
CM_ SG_ 62 ACU_BCM_HeadlightDelayCfgSt "Confige Headlight Delay Function";
CM_ SG_ 62 ACU_AVAS_SwitchCfgReq "AVAS switch configuration require";
CM_ SG_ 62 ACU_BCM_BCVehUnlockReq "ACU control vehicle unlock by bodycontrol";
CM_ SG_ 62 ACU_BCM_BCVehLockReq "ACU control vehicle lock by body control";
CM_ SG_ 62 ACU_BCM_BCAutoDomeLightCtrl "ACU control vehicle Auto Dome Light by body control";
CM_ SG_ 62 ACU_ICM_TripReset "subtotal Mileage reset for ICM";
CM_ SG_ 62 ACU_RearSeatBeltWarnCfg "turn on the rear seat belt warning  in ACU";
CM_ SG_ 62 ACU_FuelEcoDistUnitDispSt "Set ICM Unit of fuel economy and distance display";
CM_ SG_ 62 ACU_PrUnitDispCfg "Set tire pressure units from  ACU";
CM_ SG_ 62 ACU_TempUnitDispCfg "Unit of distance from ACU";
CM_ SG_ 62 ACU_PEPS_IdInVeWarningCfg "ACU to PEPS ID in Vehicle warning  configutarion";
CM_ SG_ 62 ACU_MultiIDManageReq "Multi_ID management request";
CM_ SG_ 62 ACU_BCM_AutoWiperCfg "Configuration Auto Wiper";
CM_ SG_ 62 ACU_BCM_IALFuncCfg "Configurates IAL activated";
CM_ SG_ 62 ACU_BCMHornCfg "Configurates BCM horn active on lock and unlock";
CM_ SG_ 62 ACU_BCM_DTRLFuncCfg "Configurates BCM day time running lamp function";
CM_ SG_ 62 ACU_BCM_RGearEnableRearWipeCfg "Configurates reverse gear enable rear wiping";
CM_ SG_ 62 ACU_BCM_FrontWiperSerPstFuncCfg "Configurates front wiper service position function";
CM_ SG_ 62 ACU_BCM_FrontWiperSerPstReq "Front wiper service position Request";
CM_ SG_ 62 ACU_BCM_AutoLightSnsCfg "Configurates sensibility of auto light";
CM_ SG_ 62 ACU_BCM_FollowMeHomeCfg "Configurates follow me home function";
CM_ SG_ 62 ACU_BCMAutoUnlockCfg "Configurates auto unlock doors";
CM_ SG_ 62 ACU_BCMSpdAutoLockCfg "Configurates high speed auto lock doors";
CM_ SG_ 62 ACU_BCMRemoteUnlockCfg "Configurates remote unlock doors";
CM_ SG_ 62 ACU_BCM_FogLampTurnCfg "Configurates fog lamp auxiliary lighting when turning";
CM_ SG_ 62 ACU_BCM_RemoteCtrlFDMRMCfg "Configurates remote control driver door window and sun roof";
CM_ SG_ 61 ACU_PEPS_KickSnsCfg "Configurates kick sensor (sensor to open trunk)";
CM_ SG_ 61 ACU_PEPS_MaxTeleEngTimerCfg "Configurates max telematics engine running time";
CM_ SG_ 61 ACU_PEPS_OffCfg "Configurates PEPS Off function";
CM_ SG_ 61 ACU_PEPS_MaxTeleIGNOnTimerCfg "Configurates max telematics IGN ON time";
CM_ SG_ 61 ACU_PEPSAPUCfg "Configurates PEPS APU(APU(approach unlock)function";
CM_ SG_ 61 ACU_PEPSWALCfg "Configurates PEPS WAL((Walk Away Lock) function";
CM_ SG_ 61 ACU_ICM_LanguageCfg "Configurates ICM language";
CM_ SG_ 61 ACU_ICM_TimeModeCfg "Configurates ICM time mode";
CM_ SG_ 61 ACU_ICM_WarnSoundVolCfg "Configurates warning sound volume";
CM_ SG_ 61 ACU_ICM_SpdWarnCfg "Configurates speed warning";
CM_ SG_ 61 ACU_HVACF_AutoDefCfg "Configurates auto deforst status";
CM_ SG_ 61 ACU_HVACF_AQSCfg "Configurates AQS(Air Quality Sensor)
sensitivity";
CM_ SG_ 61 ACU_PEPSSATOCfg "Configurates PEPS SATO(Sensorless Automatic Trunk Open) function";
CM_ SG_ 61 ACU_PEPS_WELCfg "Configurates PEPS WEL(Welcome light) Automatic Trunk Open) function";
CM_ SG_ 61 ACU_BCMOSRMAutoFoldCfg "Configurates BCM outside rear view mirror auto folding function";
CM_ SG_ 61 ACU_MSM_KeyRecognitionCfg "Configurates MSM key recognition";
CM_ SG_ 61 ACU_MSMWelcomeFuncCfg "Configurates MSM welcome function";
CM_ SG_ 61 ACU_RRHVSMAutoModeCfg "Configurates rear left seat heating/ventilating auto mode";
CM_ SG_ 61 ACU_RLHVSMAutoModeCfg "Configurates rear left seat heating/ventilating auto mode";
CM_ SG_ 61 ACU_FRHVSMAutoModeCfg "Configurates front right seat heating/ventilating auto mode";
CM_ SG_ 61 ACU_FLHVSMAutoModeCfg "Configurates front left seat heating/ventilating auto mode";
CM_ SG_ 61 ACU_HVACF_IonModeCfg "Configurates HVACF Ion mode";
CM_ SG_ 61 ACU_HVACF_ComfortCfg "Configurates HVACF Comfort curve";
CM_ SG_ 61 ACU_HVACFAirCirCfg "Configurates the air circulation control mode when HVACF  in auto mode";
CM_ SG_ 61 ACU_HVACF_ACCfg "Configurates the compressor control mode when HVACF in auto mode";
CM_ SG_ 821 ACU_HUD_OffSt "HUD receiving ACU switch signal";
CM_ SG_ 821 ACU_TELBcallReq "TEL Bcall request";
CM_ SG_ 821 ACU_HUDADASCruiseDisReq "HUD display ADAS Cruise assist swithc signal";
CM_ SG_ 821 ACU_HUD_NAV "HUD display navigation swithc signal";
CM_ SG_ 821 ACU_HUDADASTSRDisReq "HUD display ADAS TSR swithc signal";
CM_ SG_ 821 ACU_HUD_BrightnessSt "HUD receiving ACU brightness adjustment signal";
CM_ SG_ 821 ACU_SVMViewPosReq "SVM(Surround View Module) view position request";
CM_ SG_ 821 ACU_ModeChangeInf "ACU  mode change information";
CM_ SG_ 821 ACU_HUD_HeightSt "HUD receiving ACU height adjustment signal";
CM_ SG_ 821 ACU_HUD_AngleSt "HUD receiving ACU angle adjustment signal";
CM_ SG_ 821 ACU_TeleModeActSt "Telematics mode active state";
CM_ SG_ 821 ACU_CallMuteModeAct "Call mute mode active";
CM_ SG_ 821 ACU_SetupConfig "Setup configuration state";
CM_ SG_ 821 ACU_MusicSt "ACU Music Status";
CM_ SG_ 821 ACU_KeyREWSt "Key REW state";
CM_ SG_ 821 ACU_KeyFFWSt "Key FFW state";
CM_ SG_ 821 ACU_Key6St "Key 6 status value";
CM_ SG_ 821 ACU_Key5St "Key 5 status value";
CM_ SG_ 821 ACU_CallAnswerMode "Call answer mode";
CM_ SG_ 821 ACU_PhoneCallReq "Phone call request";
CM_ SG_ 821 ACU_Key4St "Key 4 status value";
CM_ SG_ 821 ACU_Key3St "Key 3 status value";
CM_ SG_ 821 ACU_Key2St "Key2 status value";
CM_ SG_ 821 ACU_Key1St "Key 1 status value";
CM_ SG_ 814 ACU_IFC_SLCAheadDis "speed limit camera ahead distacne. Once navigation jduge there is a speed limit camera ahead that the vehicle will pass by, this signal begin to send specific value, otherwise keep sending 0x0.";
CM_ SG_ 814 ACU_IFC_NaviNewIcon "indication the navigation newIcon";
CM_ SG_ 814 ACU_IFC_NaviNewIconDis "the remain distances of navigation newIcon";
CM_ SG_ 814 ACU_IFC_OfframpSt "The front is off-ramp or not when navigation";
CM_ SG_ 814 ACU_IFC_ZoneCode "Zone code";
CM_ SG_ 814 ACU_IFC_NaviSt "Navigation state";
CM_ SG_ 814 ACU_IFC_NaviCorp "the working navigation map corporation";
CM_ SG_ 814 ACU_IFC_SpeedLimtType "speed limit type from navigation map data and GPS location.";
CM_ SG_ 814 ACU_IFC_RoadType "Road type from navigation map data and GPS location.";
CM_ SG_ 814 ACU_IFC_SpeedLimitUnit "Speed limit unit";
CM_ SG_ 814 ACU_IFC_OfframpDis "The distance to front off-ramp";
CM_ SG_ 814 ACU_IFC_ISDRestOfdis "Interval speed detection rest of distacne. Once navigation jduge vehicle run in an interval speed detection area of road, this signal begin to send specific value, otherwise keep sending 0x0.";
CM_ SG_ 814 ACU_IFC_SpeedLimit "Speed limit value from navigation map data and GPS location.";
CM_ SG_ 849 ACU_MediaPlayMin "Media play minimute";
CM_ SG_ 849 ACU_MediaPlaySec "Media play second";
CM_ SG_ 849 ACU_MediaPlayHour "Media play hour";
CM_ SG_ 849 ACU_MediaPlayTotalMin "Media play minimute";
CM_ SG_ 849 ACU_MediaPlayTotalSec "Media play second";
CM_ SG_ 849 ACU_MediaPlayTotalHour "Media play hour";
CM_ SG_ 849 ACU_CurrentAMFreq "Current AM/MW/LW frequency";
CM_ SG_ 849 ACU_CurrentSource "ACU Current source";
CM_ SG_ 849 ACU_CurrentFMFreq "Current FM/OIRT frequency";
CM_ SG_ 849 ACU_SearchStationMode "Current tuner search station mode";
CM_ SG_ 945 ACU_ICM_SynchDriveMode "ACU synchronize the ICM driver mode
When ACU receive the ICM_DriverMode change, prepare the LVDS output (0x1..0x8) ready,set the ID";
CM_ SG_ 945 ACU_ICM_SynchDispID "ACU Synchronize the ICM display ID
When ACU receive the ICM_DisplayID change, prepare the LVDS output (0x1..0x8) ready,set the ID";
CM_ SG_ 945 ACU_APP_PhoneReady "ACU phone APP status";
CM_ SG_ 945 ACU_APP_NaviReady "ACU Navi APP status";
CM_ SG_ 945 ACU_APP_MeadiaReady "ACU Media APP status";
CM_ SG_ 945 ACU_SystemReady "ACU System state";
CM_ SG_ 945 ACU_PhoneCallSec "Phone call second";
CM_ SG_ 945 ACU_PhoneCallMin "Phone call minimute";
CM_ SG_ 945 ACU_PhoneCallHour "Phone call hour";
CM_ SG_ 945 ACU_PhoneType "Phone type";
CM_ SG_ 945 ACU_PhoneSt "Phone status";
CM_ SG_ 921 ACU_NaviDestDistInfo "Navigation destination distance information";
CM_ SG_ 921 ACU_NaviHour "Time information for hour";
CM_ SG_ 921 ACU_NaviMinitue "Time information for minimute";
CM_ SG_ 921 ACU_NaviDestDistUnit "Navigation destination distance information diplay unit";
CM_ SG_ 921 ACU_NaviSt "Navigation status";
CM_ SG_ 911 ACU_CharacterTransData "Character transmition data";
CM_ SG_ 911 ACU_CharacterTransPCI "Character transmition PCI(Protocol Cotrol Information)";
CM_ SG_ 830 ACU_NaviDist "Navigation distance information";
CM_ SG_ 830 ACU_NaviIcon_WS "Navigation icon information for WS(Warning Signs)";
CM_ SG_ 830 ACU_NaviIcon_RC "Navigation icon information for RC(Road Cameras)";
CM_ SG_ 830 ACU_NaviIcon_TBT "Navigation icon information for TBT(Turn By Turn)";
CM_ SG_ 830 ACU_NaviDistUnit "Navigation distance information diplay unit";
CM_ SG_ 830 ACU_NaviRoadChangeFlag "Navigation road change flag";
CM_ SG_ 825 ACU_NaviDestDistance "Navigation destination distance";
CM_ SG_ 825 ACU_AltitudeInteger "Integer part of altitude";
CM_ SG_ 825 ACU_AzimuthInfo "Azimuth information";
CM_ SG_ 825 ACU_GPSSignalSt "GPS signal status";
CM_ SG_ 825 ACU_SeaLevel "Vehicle below or above sea level";
CM_ SG_ 825 ACU_AltitudeDecimal "Decimal part of altitude";
CM_ SG_ 131 ACU_RCWTypeReqCfg "RCW warnning type request";
CM_ SG_ 131 ACU_DragModeReq "ACU Drag Mode Reqest Status";
CM_ SG_ 131 ACU_FaceIDSwitch "FaceID switch triger";
CM_ SG_ 131 ACU_FaceIDQuit "FaceID quit triger";
CM_ SG_ 131 ACU_VerifyTriger "FaceID verify triger";
CM_ SG_ 131 ACU_RegisterTriger "FaceID register triger";
CM_ SG_ 131 ACU_FCTA_TypeReqCfg "FCTA assist type request";
CM_ SG_ 131 ACU_RCTA_TypeReqCfg "RCTA assist type request";
CM_ SG_ 131 ACU_RAWCfg "Configurates RAW function";
CM_ SG_ 131 ACU_FCTACfg "Configurates FCTA function";
CM_ SG_ 131 ACU_ELKCfg "Configurates ELKA function";
CM_ SG_ 131 ACU_WCM_SwitchStCfg "Configurates WCM switch status";
CM_ SG_ 131 ACU_HUD_DisplayTypeCfg "Configurates HUD display type";
CM_ SG_ 131 ACU_HUD_DisplayPosCfg "Configurates HUD display position";
CM_ SG_ 131 ACU_HUD_BacklightLevelCfg "Configurates HUD back light level";
CM_ SG_ 130 ACU_ADASWarnTypeSwitch "ADAS warning type switch signal";
CM_ SG_ 130 ACU_HWA_SwitchReq "HWA(High Way Assist)  on/off switch";
CM_ SG_ 130 ACU_RAEBcfg "RAEB Set Status";
CM_ SG_ 130 ACU_TSR_AudioWarnReq "TSR(Traffic Sign Recognition) audio warning on off signal";
CM_ SG_ 130 ACU_DMSMode "DMS mode";
CM_ SG_ 130 ACU_DMSSwitch "DMS switch";
CM_ SG_ 130 ACU_iACC_SwitchReq "iACC(TSR information fusion with ACC) switch signal";
CM_ SG_ 130 ACU_DOWCfg "Configurates DOW Switch Signal";
CM_ SG_ 130 ACU_RCTACfg "Configurates RCTA Switch Signal";
CM_ SG_ 130 ACU_BSDCfg "Configurates BSD Switch Signal";
CM_ SG_ 130 ACU_IFC_SpeedLimtValueType "Speed limit value type";
CM_ SG_ 130 ACU_LKS_TypeReq "LKS(Lane Keeping Support) lane aid type request";
CM_ SG_ 130 ACU_HMA_SwitchReq "IHBC(Intelligent High Beam Control) switch signal";
CM_ SG_ 130 ACU_TSR_SwitchReq "TSR(Traffic Sign Recognition) switch signal";
CM_ SG_ 130 ACU_LKS_Sensitivity "Configurates LKS(Lane Keeping Support ) warning sensibility";
CM_ SG_ 130 ACU_IFC_CruiseModeCfg "Configurates Cruise Mode";
CM_ SG_ 130 ACU_SVM_RightBlindViewReq "Request SVM to turn on/off right blind view";
CM_ SG_ 130 ACU_SVM_LeftBlindViewReq "Request SVM to turn on/off left blind view";
CM_ SG_ 130 ACU_LDW_WarmSnsCfg "Configurates LDW warning sensibility";
CM_ SG_ 130 ACU_LDW_LKACfg "Configurates LDW lane keeping assist";
CM_ SG_ 84 ACU_PCS_LadarTriggerSVMset "Ladar trigger SVM setting";
CM_ SG_ 84 ACU_PCS_TurnFollowSet "Turn follow setting";
CM_ SG_ 84 ACU_PCS_ParkGearExitSet "The Park-Gear exit time setting";
CM_ SG_ 84 ACU_PCS_TrajectoryLineSet "The trajectory line setting";
CM_ SG_ 84 ACU_PCS_ScreenCoordX "Screen touched in ER coordinate X";
CM_ SG_ 84 ACU_PCS_ScreenCoordY "Screen touched in ER coordinate Y";
CM_ SG_ 84 ACU_PCS_ScreenTouchSt "ACU screen touch status";
CM_ SG_ 84 ACU_PCS_ER_QuitConfirm "Event record quit confirm";
CM_ SG_ 84 ACU_PCS_ER_EnterCmd "Event record enter command";
CM_ SG_ 84 ACU_ER_FuncCfg "Event record funtion configuration";
CM_ SG_ 84 ACU_PCS_AdjParkPosCmd "Adjust parking position command";
CM_ SG_ 84 ACU_PCS_SVM_PGSReturnCmd "Return command";
CM_ SG_ 84 ACU_PCS_SVM_SoundReminderCmd "Sound reminder enable request";
CM_ SG_ 84 ACU_PCS_SVM_ViewModeCmd "PCS() subsytem SVM 3D control command";
CM_ SG_ 84 ACU_PCS_SVM_MODCmd "MOD(Moving Object Detection) control command";
CM_ SG_ 84 ACU_PCS_SVM_PGSCmd "PGS(Parking Guidance System) control command";
CM_ SG_ 84 ACU_PCS_SVM_SingleViewCmd "PCS(Parking Camera System) signal view command";
CM_ SG_ 84 ACU_PCS_SVM_FunctionCmd "PCS(Parking Camera System) HMI command";
CM_ SG_ 158 ACU_PAAMode "The Mode of PAA  which ACU request for";
BA_DEF_ SG_  "Remark" STRING ;
BA_DEF_ SG_  "EventCommandSignal" ENUM  "No","Yes";
BA_DEF_ SG_  "GatewayedSignals" ENUM  "No","Yes";
BA_DEF_ SG_  "GenSigTimeoutValue" INT 0 0;
BA_DEF_ SG_  "GenSigStartValue" INT 0 0;
BA_DEF_ SG_  "GenSigInvalidValue" INT 0 0;
BA_DEF_ SG_  "GenSigInactiveValue" INT 0 0;
BA_DEF_ BO_  "GenMsgCycleTimeFast" INT 0 0;
BA_DEF_ BO_  "GenMsgCycleTime" INT 0 0;
BA_DEF_ SG_  "GenSigSendType" ENUM  "Trigger","Passive";
BA_DEF_ BO_  "GenMsgSendType" ENUM  "Periodic","Event","IfActive","POE","PA";
BA_DEF_ SG_  "SystemSignalLongSymbol" STRING ;
BA_DEF_DEF_  "Remark" "*";
BA_DEF_DEF_  "EventCommandSignal" "No";
BA_DEF_DEF_  "GatewayedSignals" "No";
BA_DEF_DEF_  "GenSigTimeoutValue" 0;
BA_DEF_DEF_  "GenSigStartValue" 0;
BA_DEF_DEF_  "GenSigInvalidValue" 0;
BA_DEF_DEF_  "GenSigInactiveValue" 0;
BA_DEF_DEF_  "GenMsgCycleTimeFast" 0;
BA_DEF_DEF_  "GenMsgCycleTime" 0;
BA_DEF_DEF_  "GenSigSendType" "Trigger";
BA_DEF_DEF_  "GenMsgSendType" "Periodic";
BA_DEF_DEF_  "SystemSignalLongSymbol" "";
BA_ "GenMsgSendType" BO_ 1015 4;
BA_ "GenMsgCycleTimeFast" BO_ 1015 40;
BA_ "GenMsgCycleTime" BO_ 1015 1000;
BA_ "GenMsgSendType" BO_ 98 1;
BA_ "GenMsgSendType" BO_ 82 1;
BA_ "GenMsgCycleTime" BO_ 836 100;
BA_ "GenMsgSendType" BO_ 1014 4;
BA_ "GenMsgCycleTimeFast" BO_ 1014 40;
BA_ "GenMsgCycleTime" BO_ 1014 1000;
BA_ "GenMsgSendType" BO_ 150 1;
BA_ "GenMsgSendType" BO_ 46 1;
BA_ "GenMsgSendType" BO_ 161 1;
BA_ "GenMsgSendType" BO_ 141 1;
BA_ "GenMsgSendType" BO_ 75 1;
BA_ "GenMsgSendType" BO_ 66 1;
BA_ "GenMsgSendType" BO_ 47 1;
BA_ "GenMsgSendType" BO_ 806 3;
BA_ "GenMsgCycleTimeFast" BO_ 806 40;
BA_ "GenMsgCycleTime" BO_ 806 1000;
BA_ "GenMsgSendType" BO_ 603 4;
BA_ "GenMsgCycleTimeFast" BO_ 603 40;
BA_ "GenMsgCycleTime" BO_ 603 500;
BA_ "GenMsgSendType" BO_ 50 1;
BA_ "GenMsgSendType" BO_ 55 1;
BA_ "GenMsgSendType" BO_ 978 4;
BA_ "GenMsgCycleTimeFast" BO_ 978 40;
BA_ "GenMsgCycleTime" BO_ 978 1000;
BA_ "GenMsgCycleTime" BO_ 1009 200;
BA_ "GenMsgCycleTime" BO_ 858 500;
BA_ "GenMsgSendType" BO_ 129 1;
BA_ "GenMsgSendType" BO_ 62 1;
BA_ "GenMsgSendType" BO_ 61 1;
BA_ "GenMsgCycleTime" BO_ 821 100;
BA_ "GenMsgCycleTime" BO_ 814 500;
BA_ "GenMsgCycleTime" BO_ 849 200;
BA_ "GenMsgCycleTime" BO_ 945 100;
BA_ "GenMsgCycleTime" BO_ 921 200;
BA_ "GenMsgCycleTime" BO_ 911 20;
BA_ "GenMsgCycleTime" BO_ 830 200;
BA_ "GenMsgCycleTime" BO_ 825 500;
BA_ "GenMsgSendType" BO_ 131 1;
BA_ "GenMsgSendType" BO_ 130 1;
BA_ "GenMsgSendType" BO_ 84 1;
BA_ "GenMsgSendType" BO_ 158 1;
BA_ "Remark" SG_ 1015 ACU_RRSeatOperationReq "";
BA_ "EventCommandSignal" SG_ 1015 ACU_RRSeatOperationReq 1;
BA_ "Remark" SG_ 1015 ACU_RRSeatOperationReqVD "";
BA_ "EventCommandSignal" SG_ 1015 ACU_RRSeatOperationReqVD 1;
BA_ "GenSigSendType" SG_ 1015 ACU_RRSeatOperationReqVD 1;
BA_ "GenSigStartValue" SG_ 1015 ACU_RRSeatOperationReqVD 1;
BA_ "Remark" SG_ 1015 ACU_RLSeatOperationReqVD "";
BA_ "EventCommandSignal" SG_ 1015 ACU_RLSeatOperationReqVD 1;
BA_ "GenSigSendType" SG_ 1015 ACU_RLSeatOperationReqVD 1;
BA_ "GenSigStartValue" SG_ 1015 ACU_RLSeatOperationReqVD 1;
BA_ "Remark" SG_ 1015 ACU_RLSeatOperationReq "";
BA_ "EventCommandSignal" SG_ 1015 ACU_RLSeatOperationReq 1;
BA_ "Remark" SG_ 1015 ACU_HVSMR_RRSeatHeatVentModeSt "";
BA_ "EventCommandSignal" SG_ 1015 ACU_HVSMR_RRSeatHeatVentModeSt 1;
BA_ "GenSigInactiveValue" SG_ 1015 ACU_HVSMR_RRSeatHeatVentModeSt 3;
BA_ "GenSigStartValue" SG_ 1015 ACU_HVSMR_RRSeatHeatVentModeSt 3;
BA_ "Remark" SG_ 1015 ACU_HVSMR_RRSeatVentLevelReq "";
BA_ "EventCommandSignal" SG_ 1015 ACU_HVSMR_RRSeatVentLevelReq 1;
BA_ "GenSigInactiveValue" SG_ 1015 ACU_HVSMR_RRSeatVentLevelReq 4;
BA_ "GenSigStartValue" SG_ 1015 ACU_HVSMR_RRSeatVentLevelReq 4;
BA_ "Remark" SG_ 1015 ACU_HVSMR_RRSeatHeatLevelReq "";
BA_ "EventCommandSignal" SG_ 1015 ACU_HVSMR_RRSeatHeatLevelReq 1;
BA_ "GenSigInactiveValue" SG_ 1015 ACU_HVSMR_RRSeatHeatLevelReq 4;
BA_ "GenSigStartValue" SG_ 1015 ACU_HVSMR_RRSeatHeatLevelReq 4;
BA_ "Remark" SG_ 1015 ACU_HVSMR_RLSeatHeatVentModeSt "";
BA_ "EventCommandSignal" SG_ 1015 ACU_HVSMR_RLSeatHeatVentModeSt 1;
BA_ "GenSigInactiveValue" SG_ 1015 ACU_HVSMR_RLSeatHeatVentModeSt 3;
BA_ "GenSigStartValue" SG_ 1015 ACU_HVSMR_RLSeatHeatVentModeSt 3;
BA_ "Remark" SG_ 1015 ACU_HVSMR_RLSeatVentLevelReq "";
BA_ "EventCommandSignal" SG_ 1015 ACU_HVSMR_RLSeatVentLevelReq 1;
BA_ "GenSigInactiveValue" SG_ 1015 ACU_HVSMR_RLSeatVentLevelReq 4;
BA_ "GenSigStartValue" SG_ 1015 ACU_HVSMR_RLSeatVentLevelReq 4;
BA_ "Remark" SG_ 1015 ACU_HVSMR_RLSeatHeatLevelReq "";
BA_ "EventCommandSignal" SG_ 1015 ACU_HVSMR_RLSeatHeatLevelReq 1;
BA_ "GenSigInactiveValue" SG_ 1015 ACU_HVSMR_RLSeatHeatLevelReq 4;
BA_ "GenSigStartValue" SG_ 1015 ACU_HVSMR_RLSeatHeatLevelReq 4;
BA_ "Remark" SG_ 1015 ACU_ORVMOperationReqVD "";
BA_ "EventCommandSignal" SG_ 1015 ACU_ORVMOperationReqVD 1;
BA_ "GenSigSendType" SG_ 1015 ACU_ORVMOperationReqVD 1;
BA_ "Remark" SG_ 1015 ACU_SeatSteeringWheelOpratReqVD "";
BA_ "EventCommandSignal" SG_ 1015 ACU_SeatSteeringWheelOpratReqVD 1;
BA_ "GenSigSendType" SG_ 1015 ACU_SeatSteeringWheelOpratReqVD 1;
BA_ "Remark" SG_ 1015 ACU_SVM_Button "";
BA_ "EventCommandSignal" SG_ 1015 ACU_SVM_Button 1;
BA_ "GatewayedSignals" SG_ 1015 ACU_SVM_Button 1;
BA_ "Remark" SG_ 1015 ACU_APA_Button "";
BA_ "EventCommandSignal" SG_ 1015 ACU_APA_Button 1;
BA_ "GatewayedSignals" SG_ 1015 ACU_APA_Button 1;
BA_ "Remark" SG_ 1015 ACU_ORVMOperationReq "";
BA_ "EventCommandSignal" SG_ 1015 ACU_ORVMOperationReq 1;
BA_ "Remark" SG_ 1015 ACU_SeatSteeringWheelOpratReq "";
BA_ "EventCommandSignal" SG_ 1015 ACU_SeatSteeringWheelOpratReq 1;
BA_ "Remark" SG_ 1015 ACU_HVSM_FRSeatHeatVentModeSt "";
BA_ "EventCommandSignal" SG_ 1015 ACU_HVSM_FRSeatHeatVentModeSt 1;
BA_ "GenSigInactiveValue" SG_ 1015 ACU_HVSM_FRSeatHeatVentModeSt 3;
BA_ "GenSigStartValue" SG_ 1015 ACU_HVSM_FRSeatHeatVentModeSt 3;
BA_ "Remark" SG_ 1015 ACU_HVSM_FRSeatVentLevelReq "";
BA_ "EventCommandSignal" SG_ 1015 ACU_HVSM_FRSeatVentLevelReq 1;
BA_ "GenSigInactiveValue" SG_ 1015 ACU_HVSM_FRSeatVentLevelReq 4;
BA_ "GenSigStartValue" SG_ 1015 ACU_HVSM_FRSeatVentLevelReq 4;
BA_ "Remark" SG_ 1015 ACU_HVSM_FRSeatHeatLevelReq "";
BA_ "EventCommandSignal" SG_ 1015 ACU_HVSM_FRSeatHeatLevelReq 1;
BA_ "GenSigInactiveValue" SG_ 1015 ACU_HVSM_FRSeatHeatLevelReq 4;
BA_ "GenSigStartValue" SG_ 1015 ACU_HVSM_FRSeatHeatLevelReq 4;
BA_ "Remark" SG_ 1015 ACU_HVSM_FLSeatHeatVentModeSt "";
BA_ "EventCommandSignal" SG_ 1015 ACU_HVSM_FLSeatHeatVentModeSt 1;
BA_ "GenSigInactiveValue" SG_ 1015 ACU_HVSM_FLSeatHeatVentModeSt 3;
BA_ "GenSigStartValue" SG_ 1015 ACU_HVSM_FLSeatHeatVentModeSt 3;
BA_ "Remark" SG_ 1015 ACU_HVSM_FLSeatVentLevelReq "";
BA_ "EventCommandSignal" SG_ 1015 ACU_HVSM_FLSeatVentLevelReq 1;
BA_ "GenSigInactiveValue" SG_ 1015 ACU_HVSM_FLSeatVentLevelReq 4;
BA_ "GenSigStartValue" SG_ 1015 ACU_HVSM_FLSeatVentLevelReq 4;
BA_ "Remark" SG_ 1015 ACU_HVSM_FLSeatHeatLevelReq "";
BA_ "EventCommandSignal" SG_ 1015 ACU_HVSM_FLSeatHeatLevelReq 1;
BA_ "GenSigInactiveValue" SG_ 1015 ACU_HVSM_FLSeatHeatLevelReq 4;
BA_ "GenSigStartValue" SG_ 1015 ACU_HVSM_FLSeatHeatLevelReq 4;
BA_ "Remark" SG_ 98 ACU_MSM_RRSeatWelcomeFuncCfg "";
BA_ "EventCommandSignal" SG_ 98 ACU_MSM_RRSeatWelcomeFuncCfg 1;
BA_ "Remark" SG_ 98 ACU_MSM_RLSeatWelcomeFuncCfg "";
BA_ "EventCommandSignal" SG_ 98 ACU_MSM_RLSeatWelcomeFuncCfg 1;
BA_ "Remark" SG_ 98 ACU_HVSPR_RRFreezeFuncCfg "";
BA_ "EventCommandSignal" SG_ 98 ACU_HVSPR_RRFreezeFuncCfg 1;
BA_ "Remark" SG_ 98 ACU_HVSPR_RLFreezeFuncCfg "";
BA_ "EventCommandSignal" SG_ 98 ACU_HVSPR_RLFreezeFuncCfg 1;
BA_ "Remark" SG_ 98 ACU_MCM_RRMasIntensityReq "";
BA_ "EventCommandSignal" SG_ 98 ACU_MCM_RRMasIntensityReq 1;
BA_ "GenSigStartValue" SG_ 98 ACU_MCM_RRMasIntensityReq 7;
BA_ "Remark" SG_ 98 ACU_MCM_RRMasModeReq "";
BA_ "EventCommandSignal" SG_ 98 ACU_MCM_RRMasModeReq 1;
BA_ "GenSigStartValue" SG_ 98 ACU_MCM_RRMasModeReq 7;
BA_ "Remark" SG_ 98 ACU_MCM_RRMasStReq "";
BA_ "EventCommandSignal" SG_ 98 ACU_MCM_RRMasStReq 1;
BA_ "Remark" SG_ 98 ACU_MCM_RLMasIntensityReq "";
BA_ "EventCommandSignal" SG_ 98 ACU_MCM_RLMasIntensityReq 1;
BA_ "GenSigStartValue" SG_ 98 ACU_MCM_RLMasIntensityReq 7;
BA_ "Remark" SG_ 98 ACU_MCM_RLMasModeReq "";
BA_ "EventCommandSignal" SG_ 98 ACU_MCM_RLMasModeReq 1;
BA_ "GenSigStartValue" SG_ 98 ACU_MCM_RLMasModeReq 7;
BA_ "Remark" SG_ 98 ACU_MCM_RLMasStReq "";
BA_ "EventCommandSignal" SG_ 98 ACU_MCM_RLMasStReq 1;
BA_ "Remark" SG_ 82 ACU_HVSM_VR_RRVentilatLvlReq "";
BA_ "EventCommandSignal" SG_ 82 ACU_HVSM_VR_RRVentilatLvlReq 1;
BA_ "GenSigStartValue" SG_ 82 ACU_HVSM_VR_RRVentilatLvlReq 4;
BA_ "Remark" SG_ 82 ACU_HVSM_VR_RRHeatingLevelReq "";
BA_ "EventCommandSignal" SG_ 82 ACU_HVSM_VR_RRHeatingLevelReq 1;
BA_ "GenSigStartValue" SG_ 82 ACU_HVSM_VR_RRHeatingLevelReq 4;
BA_ "Remark" SG_ 82 ACU_HVSM_VR_RLVentilatLvlReq "";
BA_ "EventCommandSignal" SG_ 82 ACU_HVSM_VR_RLVentilatLvlReq 1;
BA_ "GenSigStartValue" SG_ 82 ACU_HVSM_VR_RLVentilatLvlReq 4;
BA_ "Remark" SG_ 82 ACU_HVSM_VR_RLHeatingLevelReq "";
BA_ "EventCommandSignal" SG_ 82 ACU_HVSM_VR_RLHeatingLevelReq 1;
BA_ "GenSigStartValue" SG_ 82 ACU_HVSM_VR_RLHeatingLevelReq 4;
BA_ "Remark" SG_ 82 ACU_HVSM_VR_FRVentilatLvlReq "";
BA_ "EventCommandSignal" SG_ 82 ACU_HVSM_VR_FRVentilatLvlReq 1;
BA_ "GenSigStartValue" SG_ 82 ACU_HVSM_VR_FRVentilatLvlReq 4;
BA_ "Remark" SG_ 82 ACU_HVSM_VR_FRHeatingLevelReq "";
BA_ "EventCommandSignal" SG_ 82 ACU_HVSM_VR_FRHeatingLevelReq 1;
BA_ "GenSigStartValue" SG_ 82 ACU_HVSM_VR_FRHeatingLevelReq 4;
BA_ "Remark" SG_ 82 ACU_HVSM_VR_FLVentilatLvlReq "";
BA_ "EventCommandSignal" SG_ 82 ACU_HVSM_VR_FLVentilatLvlReq 1;
BA_ "GenSigStartValue" SG_ 82 ACU_HVSM_VR_FLVentilatLvlReq 4;
BA_ "Remark" SG_ 82 ACU_HVSM_VR_FLHeatingLevelReq "";
BA_ "EventCommandSignal" SG_ 82 ACU_HVSM_VR_FLHeatingLevelReq 1;
BA_ "GenSigStartValue" SG_ 82 ACU_HVSM_VR_FLHeatingLevelReq 4;
BA_ "Remark" SG_ 836 PCS_MMIAPAFuncSelect "";
BA_ "GenSigSendType" SG_ 836 PCS_MMIAPAFuncSelect 1;
BA_ "Remark" SG_ 836 PCS_MMIAPAConfirmButton "";
BA_ "GenSigSendType" SG_ 836 PCS_MMIAPAConfirmButton 1;
BA_ "Remark" SG_ 836 PCS_PASButtonPress "";
BA_ "GenSigSendType" SG_ 836 PCS_PASButtonPress 1;
BA_ "Remark" SG_ 836 PCS_ER_QuitReq "";
BA_ "GenSigSendType" SG_ 836 PCS_ER_QuitReq 1;
BA_ "Remark" SG_ 836 PCS_ER_EnterConfirm "";
BA_ "GenSigSendType" SG_ 836 PCS_ER_EnterConfirm 1;
BA_ "Remark" SG_ 836 PCS_ACU_DisplayReq "";
BA_ "GenSigSendType" SG_ 836 PCS_ACU_DisplayReq 1;
BA_ "Remark" SG_ 836 PCS_SoundReminderSt "";
BA_ "GenSigSendType" SG_ 836 PCS_SoundReminderSt 1;
BA_ "Remark" SG_ 836 PCS_BCM_ButtonLamp "";
BA_ "GenSigSendType" SG_ 836 PCS_BCM_ButtonLamp 1;
BA_ "Remark" SG_ 836 PCS_ReturnSt "";
BA_ "GenSigSendType" SG_ 836 PCS_ReturnSt 1;
BA_ "Remark" SG_ 836 PCS_RightBlindSpotViewSt "";
BA_ "GenSigSendType" SG_ 836 PCS_RightBlindSpotViewSt 1;
BA_ "Remark" SG_ 836 PCS_LeftBlindSpotViewSt "";
BA_ "GenSigSendType" SG_ 836 PCS_LeftBlindSpotViewSt 1;
BA_ "Remark" SG_ 836 PCS_RVMButtonGroup "";
BA_ "GenSigSendType" SG_ 836 PCS_RVMButtonGroup 1;
BA_ "Remark" SG_ 836 PCS_APASlotActiveSt "";
BA_ "GenSigSendType" SG_ 836 PCS_APASlotActiveSt 1;
BA_ "Remark" SG_ 836 PCS_APATurnLampReq "";
BA_ "GenSigSendType" SG_ 836 PCS_APATurnLampReq 1;
BA_ "Remark" SG_ 836 PCS_APA_BackParkButton "";
BA_ "GenSigSendType" SG_ 836 PCS_APA_BackParkButton 1;
BA_ "Remark" SG_ 836 PCS_OperationSt "";
BA_ "GenSigSendType" SG_ 836 PCS_OperationSt 1;
BA_ "Remark" SG_ 836 PCS_3DEnalbe "";
BA_ "GenSigSendType" SG_ 836 PCS_3DEnalbe 1;
BA_ "Remark" SG_ 836 PCS_MODEnalbe "";
BA_ "GenSigSendType" SG_ 836 PCS_MODEnalbe 1;
BA_ "Remark" SG_ 836 PCS_PGSEnable "";
BA_ "GenSigSendType" SG_ 836 PCS_PGSEnable 1;
BA_ "Remark" SG_ 836 PCS_SteerIconInd "";
BA_ "GenSigSendType" SG_ 836 PCS_SteerIconInd 1;
BA_ "Remark" SG_ 836 PCS_SteerWheelTurnDirInd "";
BA_ "GenSigSendType" SG_ 836 PCS_SteerWheelTurnDirInd 1;
BA_ "Remark" SG_ 836 PCS_GuidOverlaySt "";
BA_ "GenSigSendType" SG_ 836 PCS_GuidOverlaySt 1;
BA_ "Remark" SG_ 836 PCS_DriveDirInd "";
BA_ "GenSigSendType" SG_ 836 PCS_DriveDirInd 1;
BA_ "Remark" SG_ 836 PCS_VoiceReq "";
BA_ "GenSigSendType" SG_ 836 PCS_VoiceReq 1;
BA_ "Remark" SG_ 836 PCS_SingleViewInd "";
BA_ "GenSigSendType" SG_ 836 PCS_SingleViewInd 1;
BA_ "Remark" SG_ 836 PCS_HMIIndex "";
BA_ "GenSigSendType" SG_ 836 PCS_HMIIndex 1;
BA_ "Remark" SG_ 836 PCS_EventRecordSt "";
BA_ "GenSigSendType" SG_ 836 PCS_EventRecordSt 1;
BA_ "Remark" SG_ 836 PCS_CalibrateSt "";
BA_ "GenSigSendType" SG_ 836 PCS_CalibrateSt 1;
BA_ "Remark" SG_ 836 PCS_SystemType "";
BA_ "GenSigSendType" SG_ 836 PCS_SystemType 1;
BA_ "Remark" SG_ 836 PCS_OverlayOpFail "";
BA_ "GenSigSendType" SG_ 836 PCS_OverlayOpFail 1;
BA_ "Remark" SG_ 836 PCS_PGSOpFail "";
BA_ "GenSigSendType" SG_ 836 PCS_PGSOpFail 1;
BA_ "Remark" SG_ 836 PCS_FrontRightCameraFail "";
BA_ "GenSigSendType" SG_ 836 PCS_FrontRightCameraFail 1;
BA_ "Remark" SG_ 836 PCS_FrontLeftCameraFail "";
BA_ "GenSigSendType" SG_ 836 PCS_FrontLeftCameraFail 1;
BA_ "Remark" SG_ 836 PCS_RearCameraFail "";
BA_ "GenSigSendType" SG_ 836 PCS_RearCameraFail 1;
BA_ "Remark" SG_ 836 PCS_RightCameraFail "";
BA_ "GenSigSendType" SG_ 836 PCS_RightCameraFail 1;
BA_ "Remark" SG_ 836 PCS_LeftCameraFail "";
BA_ "GenSigSendType" SG_ 836 PCS_LeftCameraFail 1;
BA_ "Remark" SG_ 836 PCS_FrontCameraFail "";
BA_ "GenSigSendType" SG_ 836 PCS_FrontCameraFail 1;
BA_ "Remark" SG_ 836 notsued1 "";
BA_ "GenSigSendType" SG_ 836 notsued1 1;
BA_ "Remark" SG_ 836 PCS_SystemSt "";
BA_ "GenSigSendType" SG_ 836 PCS_SystemSt 1;
BA_ "Remark" SG_ 1014 ACU_HVAC_RearWindSpdSet "";
BA_ "Remark" SG_ 1014 ACU_HVAC_RearAutoModeBtnSt "";
BA_ "Remark" SG_ 1014 ACU_HVAC_RearOnOffBtnSt "";
BA_ "Remark" SG_ 1014 ACU_HVACFR_RrTempSettingVD "A8E新增2";
BA_ "GenSigSendType" SG_ 1014 ACU_HVACFR_RrTempSettingVD 1;
BA_ "Remark" SG_ 1014 ACU_HVACFR_RrTempSetting "";
BA_ "GenSigInactiveValue" SG_ 1014 ACU_HVACFR_RrTempSetting 29;
BA_ "GenSigStartValue" SG_ 1014 ACU_HVACFR_RrTempSetting 29;
BA_ "Remark" SG_ 1014 ACU_HVAC_RearMODESetting "";
BA_ "Remark" SG_ 1014 ACU_HVACFR_PsnTempSetting "";
BA_ "GenSigInactiveValue" SG_ 1014 ACU_HVACFR_PsnTempSetting 29;
BA_ "GenSigStartValue" SG_ 1014 ACU_HVACFR_PsnTempSetting 29;
BA_ "Remark" SG_ 1014 ACU_HVACFR_ModeSetting "";
BA_ "Remark" SG_ 1014 ACU_HVACFR_WindSpeedSetting "";
BA_ "Remark" SG_ 1014 ACU_HVACFR_WindSpeedSettingVD "A8E新增2";
BA_ "GenSigSendType" SG_ 1014 ACU_HVACFR_WindSpeedSettingVD 1;
BA_ "Remark" SG_ 1014 ACU_HVACFR_PsnTempSettingVD "A8E新增2";
BA_ "GenSigSendType" SG_ 1014 ACU_HVACFR_PsnTempSettingVD 1;
BA_ "Remark" SG_ 1014 ACU_HVACFR_DrTempSettingVD "A8E新增2";
BA_ "GenSigSendType" SG_ 1014 ACU_HVACFR_DrTempSettingVD 1;
BA_ "Remark" SG_ 1014 ACU_HVACFR_DrTempSetting "";
BA_ "GenSigInactiveValue" SG_ 1014 ACU_HVACFR_DrTempSetting 29;
BA_ "GenSigStartValue" SG_ 1014 ACU_HVACFR_DrTempSetting 29;
BA_ "Remark" SG_ 150 ACU_PSD_VR_PSDRControlVD "";
BA_ "EventCommandSignal" SG_ 150 ACU_PSD_VR_PSDRControlVD 1;
BA_ "GenSigStartValue" SG_ 150 ACU_PSD_VR_PSDRControlVD 1;
BA_ "Remark" SG_ 150 ACU_PSD_VR_PSDRControl "";
BA_ "EventCommandSignal" SG_ 150 ACU_PSD_VR_PSDRControl 1;
BA_ "Remark" SG_ 150 ACU_PSD_VR_PSDLControlVD "";
BA_ "EventCommandSignal" SG_ 150 ACU_PSD_VR_PSDLControlVD 1;
BA_ "GenSigStartValue" SG_ 150 ACU_PSD_VR_PSDLControlVD 1;
BA_ "Remark" SG_ 150 ACU_PSD_VR_PSDLControl "";
BA_ "EventCommandSignal" SG_ 150 ACU_PSD_VR_PSDLControl 1;
BA_ "Remark" SG_ 150 ACU_SCMRR_StoragemodeFuncCfg "";
BA_ "EventCommandSignal" SG_ 150 ACU_SCMRR_StoragemodeFuncCfg 1;
BA_ "Remark" SG_ 150 ACU_SCMRL_StoragemodeFuncCfg "";
BA_ "EventCommandSignal" SG_ 150 ACU_SCMRL_StoragemodeFuncCfg 1;
BA_ "Remark" SG_ 150 ACU_Freezepermissions_FuncCfg "";
BA_ "EventCommandSignal" SG_ 150 ACU_Freezepermissions_FuncCfg 1;
BA_ "Remark" SG_ 150 ACU_SCMRL_Freezepermissions_Func "";
BA_ "EventCommandSignal" SG_ 150 ACU_SCMRL_Freezepermissions_Func 1;
BA_ "SystemSignalLongSymbol" SG_ 150 ACU_SCMRL_Freezepermissions_Func "ACU_SCMRL_Freezepermissions_FuncCfg";
BA_ "Remark" SG_ 150 ACU_SCMRR_WelcomeFuncCfg "";
BA_ "EventCommandSignal" SG_ 150 ACU_SCMRR_WelcomeFuncCfg 1;
BA_ "Remark" SG_ 150 ACU_SCMRL_WelcomeFuncCfg "";
BA_ "EventCommandSignal" SG_ 150 ACU_SCMRL_WelcomeFuncCfg 1;
BA_ "Remark" SG_ 150 ACU_MSM_OSRMAngleAdjFuncCfg "";
BA_ "EventCommandSignal" SG_ 150 ACU_MSM_OSRMAngleAdjFuncCfg 1;
BA_ "Remark" SG_ 150 ACU_HVACF_FraganceConcentrationS "";
BA_ "GenSigStartValue" SG_ 150 ACU_HVACF_FraganceConcentrationS 1;
BA_ "SystemSignalLongSymbol" SG_ 150 ACU_HVACF_FraganceConcentrationS "ACU_HVACF_FraganceConcentrationStVD";
BA_ "Remark" SG_ 150 ACU_HVACF_FraganceTasteStVD "";
BA_ "GenSigStartValue" SG_ 150 ACU_HVACF_FraganceTasteStVD 1;
BA_ "Remark" SG_ 150 ACU_HVACF_FraganceTasteSt "";
BA_ "Remark" SG_ 150 ACU_HVACF_FraganceConcentra_0000 "";
BA_ "SystemSignalLongSymbol" SG_ 150 ACU_HVACF_FraganceConcentra_0000 "ACU_HVACF_FraganceConcentrationSt";
BA_ "EventCommandSignal" SG_ 46 ACU_DrvTargetSOECfg 1;
BA_ "GatewayedSignals" SG_ 46 ACU_DrvTargetSOECfg 1;
BA_ "Remark" SG_ 46 ACU_OperatingModeCfg "a8e新增2";
BA_ "EventCommandSignal" SG_ 46 ACU_OperatingModeCfg 1;
BA_ "Remark" SG_ 46 ACU_ChgCurrCfg "a8e新增2";
BA_ "EventCommandSignal" SG_ 46 ACU_ChgCurrCfg 1;
BA_ "GenSigStartValue" SG_ 46 ACU_ChgCurrCfg 16;
BA_ "Remark" SG_ 46 ACU_ChgEndReq "a8e新增2";
BA_ "EventCommandSignal" SG_ 46 ACU_ChgEndReq 1;
BA_ "Remark" SG_ 46 ACU_PlugAutoUnlockCfg "a8e新增2";
BA_ "EventCommandSignal" SG_ 46 ACU_PlugAutoUnlockCfg 1;
BA_ "Remark" SG_ 46 ACU_DischgTimeCfg "a8e新增2";
BA_ "EventCommandSignal" SG_ 46 ACU_DischgTimeCfg 1;
BA_ "Remark" SG_ 46 ACU_DischgEngStartSoc "a8e新增2";
BA_ "EventCommandSignal" SG_ 46 ACU_DischgEngStartSoc 1;
BA_ "Remark" SG_ 46 ACU_DischgEngStartCfg "a8e新增2";
BA_ "EventCommandSignal" SG_ 46 ACU_DischgEngStartCfg 1;
BA_ "Remark" SG_ 46 ACU_DischgActiveReq "a8e新增2";
BA_ "EventCommandSignal" SG_ 46 ACU_DischgActiveReq 1;
BA_ "Remark" SG_ 46 ACU_DischgSocCfg "a8e新增2";
BA_ "EventCommandSignal" SG_ 46 ACU_DischgSocCfg 1;
BA_ "EventCommandSignal" SG_ 161 ACU_DrvModNewCfg 1;
BA_ "EventCommandSignal" SG_ 161 ACU_WarmTimeCfg 1;
BA_ "GatewayedSignals" SG_ 161 ACU_WarmTimeCfg 1;
BA_ "Remark" SG_ 161 ACU_DrvModCfg "";
BA_ "EventCommandSignal" SG_ 161 ACU_DrvModCfg 1;
BA_ "Remark" SG_ 161 ACU_RecpLevelCfg "仅A5E有Level 4";
BA_ "EventCommandSignal" SG_ 161 ACU_RecpLevelCfg 1;
BA_ "EventCommandSignal" SG_ 141 ACU_HVACF_SmartSet 1;
BA_ "Remark" SG_ 141 ACU_ESACfg "";
BA_ "EventCommandSignal" SG_ 141 ACU_ESACfg 1;
BA_ "Remark" SG_ 141 ACU_HWAWDSwitchReq "";
BA_ "EventCommandSignal" SG_ 141 ACU_HWAWDSwitchReq 1;
BA_ "Remark" SG_ 141 ACU_FVDSwitchReq "";
BA_ "EventCommandSignal" SG_ 141 ACU_FVDSwitchReq 1;
BA_ "Remark" SG_ 141 ACU_TCH_VR_CuphdrHeatColAutMdSt "";
BA_ "EventCommandSignal" SG_ 141 ACU_TCH_VR_CuphdrHeatColAutMdSt 1;
BA_ "GenSigStartValue" SG_ 141 ACU_TCH_VR_CuphdrHeatColAutMdSt 2;
BA_ "Remark" SG_ 141 ACU_TCH_VR_CupholderHeatCoolMdSt "";
BA_ "EventCommandSignal" SG_ 141 ACU_TCH_VR_CupholderHeatCoolMdSt 1;
BA_ "GenSigStartValue" SG_ 141 ACU_TCH_VR_CupholderHeatCoolMdSt 3;
BA_ "Remark" SG_ 141 ACU_TCH_CupholdrHeatCoolAutoMdSt "";
BA_ "EventCommandSignal" SG_ 141 ACU_TCH_CupholdrHeatCoolAutoMdSt 1;
BA_ "GenSigStartValue" SG_ 141 ACU_TCH_CupholdrHeatCoolAutoMdSt 2;
BA_ "Remark" SG_ 141 ACU_TCH_CupholderHeatCoolModeSt "";
BA_ "EventCommandSignal" SG_ 141 ACU_TCH_CupholderHeatCoolModeSt 1;
BA_ "GenSigStartValue" SG_ 141 ACU_TCH_CupholderHeatCoolModeSt 3;
BA_ "Remark" SG_ 141 ACU_TCH_VR_CupholdrHeatCoolMdVD "";
BA_ "EventCommandSignal" SG_ 141 ACU_TCH_VR_CupholdrHeatCoolMdVD 1;
BA_ "GenSigStartValue" SG_ 141 ACU_TCH_VR_CupholdrHeatCoolMdVD 1;
BA_ "Remark" SG_ 141 ACU_TCH_CupholderHeatCoolModeVD "";
BA_ "EventCommandSignal" SG_ 141 ACU_TCH_CupholderHeatCoolModeVD 1;
BA_ "GenSigStartValue" SG_ 141 ACU_TCH_CupholderHeatCoolModeVD 1;
BA_ "Remark" SG_ 141 ACU_PSD_ModeSt "";
BA_ "EventCommandSignal" SG_ 141 ACU_PSD_ModeSt 1;
BA_ "Remark" SG_ 141 ACU_PSDR_SpdSet "";
BA_ "EventCommandSignal" SG_ 141 ACU_PSDR_SpdSet 1;
BA_ "Remark" SG_ 141 ACU_PSDL_SpdSet "";
BA_ "EventCommandSignal" SG_ 141 ACU_PSDL_SpdSet 1;
BA_ "Remark" SG_ 141 ACU_HVACF_EvapratorSelfCleanCfg "";
BA_ "EventCommandSignal" SG_ 141 ACU_HVACF_EvapratorSelfCleanCfg 1;
BA_ "Remark" SG_ 141 ACU_HVACFUnlockVentilationCfg "";
BA_ "EventCommandSignal" SG_ 141 ACU_HVACFUnlockVentilationCfg 1;
BA_ "Remark" SG_ 141 ACU_CancelMaintenanceCfg "";
BA_ "EventCommandSignal" SG_ 141 ACU_CancelMaintenanceCfg 1;
BA_ "Remark" SG_ 141 ACU_MaintenanceResetCfg "";
BA_ "EventCommandSignal" SG_ 141 ACU_MaintenanceResetCfg 1;
BA_ "Remark" SG_ 141 ACU_MaintenanceCycleCfg "";
BA_ "EventCommandSignal" SG_ 141 ACU_MaintenanceCycleCfg 1;
BA_ "Remark" SG_ 141 ACU_SteeringHeatingReq "";
BA_ "EventCommandSignal" SG_ 141 ACU_SteeringHeatingReq 1;
BA_ "EventCommandSignal" SG_ 75 ACU_SecondSeatShortcutmode 1;
BA_ "Remark" SG_ 75 ACU_VR_APA_Switch "";
BA_ "EventCommandSignal" SG_ 75 ACU_VR_APA_Switch 1;
BA_ "GatewayedSignals" SG_ 75 ACU_VR_APA_Switch 1;
BA_ "Remark" SG_ 75 ACU_VR_SVM_Switch "";
BA_ "EventCommandSignal" SG_ 75 ACU_VR_SVM_Switch 1;
BA_ "GatewayedSignals" SG_ 75 ACU_VR_SVM_Switch 1;
BA_ "Remark" SG_ 75 ACU_MCM_VR_RRMasIntensityReq "";
BA_ "EventCommandSignal" SG_ 75 ACU_MCM_VR_RRMasIntensityReq 1;
BA_ "GenSigStartValue" SG_ 75 ACU_MCM_VR_RRMasIntensityReq 4;
BA_ "Remark" SG_ 75 ACU_MCM_VR_RRMasModeReq "";
BA_ "EventCommandSignal" SG_ 75 ACU_MCM_VR_RRMasModeReq 1;
BA_ "GenSigStartValue" SG_ 75 ACU_MCM_VR_RRMasModeReq 7;
BA_ "Remark" SG_ 75 ACU_MCM_VR_RRMasStReq "";
BA_ "EventCommandSignal" SG_ 75 ACU_MCM_VR_RRMasStReq 1;
BA_ "GenSigStartValue" SG_ 75 ACU_MCM_VR_RRMasStReq 2;
BA_ "Remark" SG_ 75 ACU_MCM_VR_RLMasIntensityReq "";
BA_ "EventCommandSignal" SG_ 75 ACU_MCM_VR_RLMasIntensityReq 1;
BA_ "GenSigStartValue" SG_ 75 ACU_MCM_VR_RLMasIntensityReq 4;
BA_ "Remark" SG_ 75 ACU_MCM_VR_RLMassagemode "";
BA_ "EventCommandSignal" SG_ 75 ACU_MCM_VR_RLMassagemode 1;
BA_ "GenSigStartValue" SG_ 75 ACU_MCM_VR_RLMassagemode 7;
BA_ "Remark" SG_ 75 ACU_MCM_VR_RLMasStReq "";
BA_ "EventCommandSignal" SG_ 75 ACU_MCM_VR_RLMasStReq 1;
BA_ "GenSigStartValue" SG_ 75 ACU_MCM_VR_RLMasStReq 2;
BA_ "Remark" SG_ 75 ACU_ShortcutMode "";
BA_ "EventCommandSignal" SG_ 75 ACU_ShortcutMode 1;
BA_ "Remark" SG_ 75 ACU_SCMNapSettingSave "";
BA_ "EventCommandSignal" SG_ 75 ACU_SCMNapSettingSave 1;
BA_ "Remark" SG_ 75 ACU_MSM_VR_FLSeatVoiceCtrlVD "";
BA_ "EventCommandSignal" SG_ 75 ACU_MSM_VR_FLSeatVoiceCtrlVD 1;
BA_ "Remark" SG_ 75 ACU_MSM_VR_FLSeatVoiceCtrl "";
BA_ "EventCommandSignal" SG_ 75 ACU_MSM_VR_FLSeatVoiceCtrl 1;
BA_ "Remark" SG_ 66 ACU_PEPS_VR_EngPowerOffReqVD "";
BA_ "EventCommandSignal" SG_ 66 ACU_PEPS_VR_EngPowerOffReqVD 1;
BA_ "Remark" SG_ 66 ACU_PEPS_VR_EngPowerOffReq "";
BA_ "EventCommandSignal" SG_ 66 ACU_PEPS_VR_EngPowerOffReq 1;
BA_ "Remark" SG_ 66 ACU_PEPS_VR_EngStartReqVD "";
BA_ "EventCommandSignal" SG_ 66 ACU_PEPS_VR_EngStartReqVD 1;
BA_ "Remark" SG_ 66 ACU_PEPS_VR_EngStartReq "";
BA_ "EventCommandSignal" SG_ 66 ACU_PEPS_VR_EngStartReq 1;
BA_ "Remark" SG_ 47 ACU_HVACF_VR_SYNCONOFF "";
BA_ "EventCommandSignal" SG_ 47 ACU_HVACF_VR_SYNCONOFF 1;
BA_ "Remark" SG_ 47 ACU_HVACF_VR_FRAGONOFF "";
BA_ "EventCommandSignal" SG_ 47 ACU_HVACF_VR_FRAGONOFF 1;
BA_ "Remark" SG_ 47 ACU_HVACF_VR_ACONOFF "";
BA_ "EventCommandSignal" SG_ 47 ACU_HVACF_VR_ACONOFF 1;
BA_ "Remark" SG_ 47 ACU_HVACF_VR_RrAutoModeONOFF "";
BA_ "EventCommandSignal" SG_ 47 ACU_HVACF_VR_RrAutoModeONOFF 1;
BA_ "Remark" SG_ 47 ACU_HVACF_VR_RrWindSpeedChange "";
BA_ "EventCommandSignal" SG_ 47 ACU_HVACF_VR_RrWindSpeedChange 1;
BA_ "GenSigStartValue" SG_ 47 ACU_HVACF_VR_RrWindSpeedChange 6;
BA_ "Remark" SG_ 47 ACU_HVACF_VR_RrTempChange "";
BA_ "EventCommandSignal" SG_ 47 ACU_HVACF_VR_RrTempChange 1;
BA_ "GenSigStartValue" SG_ 47 ACU_HVACF_VR_RrTempChange 28;
BA_ "Remark" SG_ 47 ACU_HVACF_VR_RrWindModeSetting "";
BA_ "EventCommandSignal" SG_ 47 ACU_HVACF_VR_RrWindModeSetting 1;
BA_ "Remark" SG_ 47 ACU_HVACF_VR_RrTempSetting "";
BA_ "EventCommandSignal" SG_ 47 ACU_HVACF_VR_RrTempSetting 1;
BA_ "GenSigStartValue" SG_ 47 ACU_HVACF_VR_RrTempSetting 31;
BA_ "Remark" SG_ 47 ACU_HVACF_VR_RrWindSpeedSetting "";
BA_ "EventCommandSignal" SG_ 47 ACU_HVACF_VR_RrWindSpeedSetting 1;
BA_ "Remark" SG_ 47 ACU_HVACF_VR_RDefrostONOFF "";
BA_ "EventCommandSignal" SG_ 47 ACU_HVACF_VR_RDefrostONOFF 1;
BA_ "Remark" SG_ 47 ACU_HVACF_VR_RrHVACONOFF "";
BA_ "EventCommandSignal" SG_ 47 ACU_HVACF_VR_RrHVACONOFF 1;
BA_ "GenSigSendType" SG_ 806 ACU_RChildlockCmdVD 1;
BA_ "Remark" SG_ 806 ACU_Avdcset "";
BA_ "EventCommandSignal" SG_ 806 ACU_Avdcset 1;
BA_ "GatewayedSignals" SG_ 806 ACU_Avdcset 1;
BA_ "Remark" SG_ 806 ACU_Gaspedallvl "";
BA_ "EventCommandSignal" SG_ 806 ACU_Gaspedallvl 1;
BA_ "GatewayedSignals" SG_ 806 ACU_Gaspedallvl 1;
BA_ "Remark" SG_ 806 ACU_EMS_EngWaveSwitch "";
BA_ "EventCommandSignal" SG_ 806 ACU_EMS_EngWaveSwitch 1;
BA_ "GatewayedSignals" SG_ 806 ACU_EMS_EngWaveSwitch 1;
BA_ "Remark" SG_ 806 ACU_AUID "";
BA_ "EventCommandSignal" SG_ 806 ACU_AUID 1;
BA_ "GatewayedSignals" SG_ 806 ACU_AUID 1;
BA_ "Remark" SG_ 806 ACU_MSM_SaveRecalComd "";
BA_ "EventCommandSignal" SG_ 806 ACU_MSM_SaveRecalComd 1;
BA_ "GatewayedSignals" SG_ 806 ACU_MSM_SaveRecalComd 1;
BA_ "Remark" SG_ 806 ACU_SCMNapSetting "";
BA_ "EventCommandSignal" SG_ 806 ACU_SCMNapSetting 1;
BA_ "GatewayedSignals" SG_ 806 ACU_SCMNapSetting 1;
BA_ "Remark" SG_ 806 ACU_AccountDelete "";
BA_ "EventCommandSignal" SG_ 806 ACU_AccountDelete 1;
BA_ "GatewayedSignals" SG_ 806 ACU_AccountDelete 1;
BA_ "Remark" SG_ 603 ACU_25_B_Checksum "";
BA_ "GenSigSendType" SG_ 603 ACU_25_B_Checksum 1;
BA_ "GenSigStartValue" SG_ 603 ACU_25_B_Checksum 255;
BA_ "Remark" SG_ 603 ACU_25_B_MsgCounter "";
BA_ "GenSigSendType" SG_ 603 ACU_25_B_MsgCounter 1;
BA_ "Remark" SG_ 603 ACU_BCM_VR_RightLaneChangeReqVD "";
BA_ "GenSigSendType" SG_ 603 ACU_BCM_VR_RightLaneChangeReqVD 1;
BA_ "Remark" SG_ 603 ACU_BCM_VR_LeftLaneChangeReqVD "";
BA_ "GenSigSendType" SG_ 603 ACU_BCM_VR_LeftLaneChangeReqVD 1;
BA_ "Remark" SG_ 603 ACU_BCM_VR_RightTurnLampReqVD "";
BA_ "GenSigSendType" SG_ 603 ACU_BCM_VR_RightTurnLampReqVD 1;
BA_ "Remark" SG_ 603 ACU_BCM_VR_LeftTurnLampReqVD "";
BA_ "GenSigSendType" SG_ 603 ACU_BCM_VR_LeftTurnLampReqVD 1;
BA_ "Remark" SG_ 603 ACU_BCM_VR_RightLaneChangeReq "";
BA_ "Remark" SG_ 603 ACU_BCM_VR_LeftLaneChangeReq "";
BA_ "Remark" SG_ 603 ACU_BCM_VR_TankcoverReqVD "";
BA_ "GenSigSendType" SG_ 603 ACU_BCM_VR_TankcoverReqVD 1;
BA_ "Remark" SG_ 603 ACU_BCM_VR_RearWasherReqVD "";
BA_ "GenSigSendType" SG_ 603 ACU_BCM_VR_RearWasherReqVD 1;
BA_ "Remark" SG_ 603 ACU_BCM_VR_FrontWasherReqVD "";
BA_ "GenSigSendType" SG_ 603 ACU_BCM_VR_FrontWasherReqVD 1;
BA_ "Remark" SG_ 603 ACU_BCM_VR_RearWiperReqVD "";
BA_ "GenSigSendType" SG_ 603 ACU_BCM_VR_RearWiperReqVD 1;
BA_ "Remark" SG_ 603 ACU_BCM_VR_TankcoverReq "";
BA_ "Remark" SG_ 603 ACU_BCM_VR_RearWasherReq "";
BA_ "Remark" SG_ 603 ACU_BCM_VR_FrontWasherReq "";
BA_ "Remark" SG_ 603 ACU_BCM_VR_RearWiperReq "";
BA_ "Remark" SG_ 603 ACU_BCM_VR_FrontWiperReq "";
BA_ "Remark" SG_ 603 ACU_BCM_VR_RoomLampReq "";
BA_ "Remark" SG_ 603 ACU_BCM_VR_FrontWiperReqVD "";
BA_ "GenSigSendType" SG_ 603 ACU_BCM_VR_FrontWiperReqVD 1;
BA_ "Remark" SG_ 603 ACU_BCM_VR_RoomLampReqVD "";
BA_ "GenSigSendType" SG_ 603 ACU_BCM_VR_RoomLampReqVD 1;
BA_ "Remark" SG_ 603 ACU_BCM_VR_RearFogLampReqVD "";
BA_ "GenSigSendType" SG_ 603 ACU_BCM_VR_RearFogLampReqVD 1;
BA_ "Remark" SG_ 603 ACU_BCM_VR_FrontFogLampReqVD "";
BA_ "GenSigSendType" SG_ 603 ACU_BCM_VR_FrontFogLampReqVD 1;
BA_ "Remark" SG_ 603 ACU_BCM_VR_HighBeamReqVD "";
BA_ "GenSigSendType" SG_ 603 ACU_BCM_VR_HighBeamReqVD 1;
BA_ "Remark" SG_ 603 ACU_BCM_VR_LowBeamReqVD "";
BA_ "GenSigSendType" SG_ 603 ACU_BCM_VR_LowBeamReqVD 1;
BA_ "Remark" SG_ 603 ACU_BCM_VR_ParkingLampReqVD "";
BA_ "GenSigSendType" SG_ 603 ACU_BCM_VR_ParkingLampReqVD 1;
BA_ "Remark" SG_ 603 ACU_BCM_VR_AmbientLightReqReqVD "";
BA_ "GenSigSendType" SG_ 603 ACU_BCM_VR_AmbientLightReqReqVD 1;
BA_ "Remark" SG_ 603 ACU_BCM_VR_RearFogLampReq "";
BA_ "Remark" SG_ 603 ACU_BCM_VR_FrontFogLampReq "";
BA_ "Remark" SG_ 603 ACU_BCM_VR_HighBeamReq "";
BA_ "Remark" SG_ 603 ACU_BCM_VR_LowBeamReq "";
BA_ "Remark" SG_ 603 ACU_BCM_VR_RightTurnLampReq "";
BA_ "Remark" SG_ 603 ACU_BCM_VR_LeftTurnLampReq "";
BA_ "Remark" SG_ 603 ACU_BCM_VR_ParkingLampReq "";
BA_ "Remark" SG_ 603 ACU_BCM_VR_AmbientLightReqReq "";
BA_ "EventCommandSignal" SG_ 50 ACU_OneButtVentlaionSt 1;
BA_ "Remark" SG_ 50 ACU_ICM_VR_BackLightChange "";
BA_ "EventCommandSignal" SG_ 50 ACU_ICM_VR_BackLightChange 1;
BA_ "GenSigStartValue" SG_ 50 ACU_ICM_VR_BackLightChange 15;
BA_ "Remark" SG_ 50 ACU_ICM_VR_BackLightSetting "";
BA_ "EventCommandSignal" SG_ 50 ACU_ICM_VR_BackLightSetting 1;
BA_ "Remark" SG_ 50 ACU_HVACF_VR_PsnTempChange "";
BA_ "EventCommandSignal" SG_ 50 ACU_HVACF_VR_PsnTempChange 1;
BA_ "GenSigStartValue" SG_ 50 ACU_HVACF_VR_PsnTempChange 28;
BA_ "Remark" SG_ 50 ACU_HVACF_VR_PsnTempSetting "";
BA_ "EventCommandSignal" SG_ 50 ACU_HVACF_VR_PsnTempSetting 1;
BA_ "GenSigStartValue" SG_ 50 ACU_HVACF_VR_PsnTempSetting 31;
BA_ "Remark" SG_ 50 ACU_HVACF_VR_AutoModeOnOff "";
BA_ "EventCommandSignal" SG_ 50 ACU_HVACF_VR_AutoModeOnOff 1;
BA_ "Remark" SG_ 50 ACU_HAVACF_VR_IonOnOff "";
BA_ "EventCommandSignal" SG_ 50 ACU_HAVACF_VR_IonOnOff 1;
BA_ "Remark" SG_ 50 ACU_HVACF_VR_WindSpeedChange "";
BA_ "EventCommandSignal" SG_ 50 ACU_HVACF_VR_WindSpeedChange 1;
BA_ "GenSigStartValue" SG_ 50 ACU_HVACF_VR_WindSpeedChange 6;
BA_ "Remark" SG_ 50 ACU_HVACF_VR_AirCirculationSt "";
BA_ "EventCommandSignal" SG_ 50 ACU_HVACF_VR_AirCirculationSt 1;
BA_ "Remark" SG_ 50 ACU_HVACF_VR_TempChange "";
BA_ "EventCommandSignal" SG_ 50 ACU_HVACF_VR_TempChange 1;
BA_ "GenSigStartValue" SG_ 50 ACU_HVACF_VR_TempChange 28;
BA_ "Remark" SG_ 50 ACU_HVACF_VR_WindModeSetting "";
BA_ "EventCommandSignal" SG_ 50 ACU_HVACF_VR_WindModeSetting 1;
BA_ "Remark" SG_ 50 ACU_HVACF_VR_TempSetting "";
BA_ "EventCommandSignal" SG_ 50 ACU_HVACF_VR_TempSetting 1;
BA_ "GenSigStartValue" SG_ 50 ACU_HVACF_VR_TempSetting 31;
BA_ "Remark" SG_ 50 ACU_HVACF_VR_WindSpeedSetting "";
BA_ "EventCommandSignal" SG_ 50 ACU_HVACF_VR_WindSpeedSetting 1;
BA_ "Remark" SG_ 50 ACU_HVACF_VR_FDefrostONOFF "";
BA_ "EventCommandSignal" SG_ 50 ACU_HVACF_VR_FDefrostONOFF 1;
BA_ "Remark" SG_ 50 ACU_HVACF_VR_HVACONOFF "";
BA_ "EventCommandSignal" SG_ 50 ACU_HVACF_VR_HVACONOFF 1;
BA_ "Remark" SG_ 55 ACU_HeadlightDelayCfgSt "与A29/A57位置不一致";
BA_ "EventCommandSignal" SG_ 55 ACU_HeadlightDelayCfgSt 1;
BA_ "Remark" SG_ 55 ACU_IAL_ColorModeCfg "";
BA_ "EventCommandSignal" SG_ 55 ACU_IAL_ColorModeCfg 1;
BA_ "Remark" SG_ 55 ACU_HVACFUnlockVentilationCfg "A8E新增2";
BA_ "EventCommandSignal" SG_ 55 ACU_HVACFUnlockVentilationCfg 1;
BA_ "Remark" SG_ 55 ACU_HVACF_EvapratorSelfCleanCfg "A8E新增2";
BA_ "EventCommandSignal" SG_ 55 ACU_HVACF_EvapratorSelfCleanCfg 1;
BA_ "Remark" SG_ 55 ACU_ETC_BLEenableCfg "";
BA_ "EventCommandSignal" SG_ 55 ACU_ETC_BLEenableCfg 1;
BA_ "Remark" SG_ 55 ACU_ETC_ICMDisplayCfg "";
BA_ "EventCommandSignal" SG_ 55 ACU_ETC_ICMDisplayCfg 1;
BA_ "Remark" SG_ 55 ACU_ETC_SysCfg "";
BA_ "EventCommandSignal" SG_ 55 ACU_ETC_SysCfg 1;
BA_ "Remark" SG_ 55 ACU_IAL_HVACSeasonsKeyActive "";
BA_ "EventCommandSignal" SG_ 55 ACU_IAL_HVACSeasonsKeyActive 1;
BA_ "Remark" SG_ 55 ACU_IAL_ColourChooseCfg "";
BA_ "EventCommandSignal" SG_ 55 ACU_IAL_ColourChooseCfg 1;
BA_ "Remark" SG_ 55 ACU_MSM_OSRMAngleSave "";
BA_ "EventCommandSignal" SG_ 55 ACU_MSM_OSRMAngleSave 1;
BA_ "Remark" SG_ 55 ACU_MSM_OSRMAngleAdjFuncCfg "";
BA_ "EventCommandSignal" SG_ 55 ACU_MSM_OSRMAngleAdjFuncCfg 1;
BA_ "Remark" SG_ 55 ACU_IAL_MusicModeCfg "";
BA_ "EventCommandSignal" SG_ 55 ACU_IAL_MusicModeCfg 1;
BA_ "Remark" SG_ 55 ACU_IAL_DriverModeCfg "";
BA_ "EventCommandSignal" SG_ 55 ACU_IAL_DriverModeCfg 1;
BA_ "Remark" SG_ 55 ACU_HVACF_PM25CleanReqFb "";
BA_ "EventCommandSignal" SG_ 55 ACU_HVACF_PM25CleanReqFb 1;
BA_ "Remark" SG_ 55 ACU_HVACF_PM25CleanReqCfg "";
BA_ "EventCommandSignal" SG_ 55 ACU_HVACF_PM25CleanReqCfg 1;
BA_ "Remark" SG_ 55 ACU_HVACF_FanspeedCfg "";
BA_ "EventCommandSignal" SG_ 55 ACU_HVACF_FanspeedCfg 1;
BA_ "Remark" SG_ 55 ACU_IAL_ColorCfg "";
BA_ "EventCommandSignal" SG_ 55 ACU_IAL_ColorCfg 1;
BA_ "Remark" SG_ 55 ACU_IAL_BrightnessCfg "";
BA_ "EventCommandSignal" SG_ 55 ACU_IAL_BrightnessCfg 1;
BA_ "Remark" SG_ 55 ACU_IAL_FunctionCfg "";
BA_ "EventCommandSignal" SG_ 55 ACU_IAL_FunctionCfg 1;
BA_ "GenSigSendType" SG_ 978 ACU_HVACF_FraganceConcentratStVD 1;
BA_ "GenSigSendType" SG_ 978 ACU_HVACF_FraganceTasteStVD 1;
BA_ "Remark" SG_ 978 ACU_HVACF_RearBtnStVD "A8E 新增2";
BA_ "GenSigSendType" SG_ 978 ACU_HVACF_RearBtnStVD 1;
BA_ "Remark" SG_ 978 ACU_HVACF_RearBtnSt "";
BA_ "Remark" SG_ 978 ACU_HVACF_FrsAirBtnStVD "A8E 新增2";
BA_ "GenSigSendType" SG_ 978 ACU_HVACF_FrsAirBtnStVD 1;
BA_ "Remark" SG_ 978 ACU_HVACF_FrsAirBtnSt "";
BA_ "Remark" SG_ 978 ACU_HVACF_InnerCirBtnStVD "A8E 新增2";
BA_ "GenSigSendType" SG_ 978 ACU_HVACF_InnerCirBtnStVD 1;
BA_ "Remark" SG_ 978 ACU_HVACF_InnerCirBtnSt "";
BA_ "Remark" SG_ 978 ACU_HVACF_TripleZoneBtnStVD "A8E 新增2";
BA_ "GenSigSendType" SG_ 978 ACU_HVACF_TripleZoneBtnStVD 1;
BA_ "Remark" SG_ 978 ACU_HVACF_TripleZoneBtnSt "";
BA_ "Remark" SG_ 978 ACU_HVACF_FRTempDecBtnStVD "A8E 新增2";
BA_ "GenSigSendType" SG_ 978 ACU_HVACF_FRTempDecBtnStVD 1;
BA_ "Remark" SG_ 978 ACU_HVACF_FRTempDecBtnSt "";
BA_ "Remark" SG_ 978 ACU_HVACF_FRTempIncBtnStVD "A8E 新增2";
BA_ "GenSigSendType" SG_ 978 ACU_HVACF_FRTempIncBtnStVD 1;
BA_ "Remark" SG_ 978 ACU_HVACF_FRTempIncBtnSt "";
BA_ "Remark" SG_ 978 ACU_HVACF_FLTempDecBtnStVD "A8E 新增2";
BA_ "GenSigSendType" SG_ 978 ACU_HVACF_FLTempDecBtnStVD 1;
BA_ "Remark" SG_ 978 ACU_HVACF_FLTempDecBtnSt "";
BA_ "Remark" SG_ 978 ACU_HVACF_FLTempIncBtnStVD "A8E 新增2";
BA_ "GenSigSendType" SG_ 978 ACU_HVACF_FLTempIncBtnStVD 1;
BA_ "Remark" SG_ 978 ACU_HVACF_FLTempIncBtnSt "";
BA_ "Remark" SG_ 978 ACU_HVACF_FraganceTasteSt "";
BA_ "Remark" SG_ 978 ACU_HVACF_FraganceConcentratSt "";
BA_ "Remark" SG_ 978 ACU_HVACR_TempDecBtnStVD "A8E 新增2";
BA_ "GenSigSendType" SG_ 978 ACU_HVACR_TempDecBtnStVD 1;
BA_ "Remark" SG_ 978 ACU_HVACR_TempDecBtnSt "";
BA_ "Remark" SG_ 978 ACU_HVACR_TempIncBtnStVD "A8E 新增2";
BA_ "GenSigSendType" SG_ 978 ACU_HVACR_TempIncBtnStVD 1;
BA_ "Remark" SG_ 978 ACU_HVACR_TempIncBtnSt "";
BA_ "Remark" SG_ 978 ACU_HVACF_ACMaxBtnStVD "A8E 新增2";
BA_ "GenSigSendType" SG_ 978 ACU_HVACF_ACMaxBtnStVD 1;
BA_ "Remark" SG_ 978 ACU_HVACF_ACMaxBtnSt "";
BA_ "Remark" SG_ 978 ACU_HVACF_ACBtnStVD "A8E 新增2";
BA_ "GenSigSendType" SG_ 978 ACU_HVACF_ACBtnStVD 1;
BA_ "Remark" SG_ 978 ACU_HVACF_ACBtnSt "";
BA_ "Remark" SG_ 978 ACU_HVACF_CirBtnStVD "A8E 新增2";
BA_ "GenSigSendType" SG_ 978 ACU_HVACF_CirBtnStVD 1;
BA_ "Remark" SG_ 978 ACU_HVACF_CirBtnSt "";
BA_ "Remark" SG_ 978 ACU_HVACFR_FanDecBtnStVD "A8E 新增2";
BA_ "GenSigSendType" SG_ 978 ACU_HVACFR_FanDecBtnStVD 1;
BA_ "Remark" SG_ 978 ACU_HVACFR_FanDecBtnSt "";
BA_ "Remark" SG_ 978 ACU_HVACFR_FanIncBtnStVD "A8E 新增2";
BA_ "GenSigSendType" SG_ 978 ACU_HVACFR_FanIncBtnStVD 1;
BA_ "Remark" SG_ 978 ACU_HVACFR_FanIncBtnSt "";
BA_ "Remark" SG_ 978 ACU_HVACF_IonBtnStVD "A8E 新增2";
BA_ "GenSigSendType" SG_ 978 ACU_HVACF_IonBtnStVD 1;
BA_ "Remark" SG_ 978 ACU_HVACF_IonBtnSt "";
BA_ "Remark" SG_ 978 ACU_HVACF_DualBtnSyncStVD "A8E 新增2";
BA_ "GenSigSendType" SG_ 978 ACU_HVACF_DualBtnSyncStVD 1;
BA_ "Remark" SG_ 978 ACU_HVACF_DualSyncBtnSt "";
BA_ "Remark" SG_ 978 ACU_HVACF_RDefrostBtnStVD "A8E 新增2";
BA_ "GenSigSendType" SG_ 978 ACU_HVACF_RDefrostBtnStVD 1;
BA_ "Remark" SG_ 978 ACU_HVACF_RDefrostBtnSt "";
BA_ "Remark" SG_ 978 ACU_HVACF_FDefrostBtnStVD "A8E 新增2";
BA_ "GenSigSendType" SG_ 978 ACU_HVACF_FDefrostBtnStVD 1;
BA_ "Remark" SG_ 978 ACU_HVACF_FDefrostBtnSt "";
BA_ "Remark" SG_ 978 ACU_HVACFR_ModeBtnStVD "A8E 新增2";
BA_ "GenSigSendType" SG_ 978 ACU_HVACFR_ModeBtnStVD 1;
BA_ "Remark" SG_ 978 ACU_HVACFR_ModeBtnSt "";
BA_ "Remark" SG_ 978 ACU_HVACFR_AutoModeBtnStVD "A8E 新增2";
BA_ "GenSigSendType" SG_ 978 ACU_HVACFR_AutoModeBtnStVD 1;
BA_ "Remark" SG_ 978 ACU_HVACFR_AutoModeBtnSt "";
BA_ "Remark" SG_ 978 ACU_HVACFR_OffBtnStVD "";
BA_ "GenSigSendType" SG_ 978 ACU_HVACFR_OffBtnStVD 1;
BA_ "Remark" SG_ 978 ACU_HVACFR_OffBtnSt "";
BA_ "GenSigSendType" SG_ 1009 ACU_HAVPMessageSt 1;
BA_ "Remark" SG_ 1009 ACU_VMM_RecordSt "";
BA_ "GenSigSendType" SG_ 1009 ACU_VMM_RecordSt 1;
BA_ "Remark" SG_ 1009 ACU_PCS_MirropagedownButtonST "暂时放置，后续可能调整";
BA_ "GenSigSendType" SG_ 1009 ACU_PCS_MirropagedownButtonST 1;
BA_ "Remark" SG_ 1009 ACU_MuteSt "";
BA_ "GenSigSendType" SG_ 1009 ACU_MuteSt 1;
BA_ "Remark" SG_ 1009 ACU_VolumeDefaultValue "";
BA_ "GenSigSendType" SG_ 1009 ACU_VolumeDefaultValue 1;
BA_ "Remark" SG_ 1009 ACU_VolumeMaxValue "";
BA_ "GenSigSendType" SG_ 1009 ACU_VolumeMaxValue 1;
BA_ "Remark" SG_ 1009 ACU_VolumeCurrentValue "";
BA_ "GenSigSendType" SG_ 1009 ACU_VolumeCurrentValue 1;
BA_ "Remark" SG_ 858 ACU_ThemeTypet "";
BA_ "GenSigSendType" SG_ 858 ACU_ThemeTypet 1;
BA_ "Remark" SG_ 858 ACU_Time_Sec "";
BA_ "GenSigSendType" SG_ 858 ACU_Time_Sec 1;
BA_ "GenSigStartValue" SG_ 858 ACU_Time_Sec 1;
BA_ "Remark" SG_ 858 ACU_LanguageTypeSet "";
BA_ "GenSigSendType" SG_ 858 ACU_LanguageTypeSet 1;
BA_ "Remark" SG_ 858 ACU_Time_Min "";
BA_ "GenSigSendType" SG_ 858 ACU_Time_Min 1;
BA_ "GenSigStartValue" SG_ 858 ACU_Time_Min 1;
BA_ "Remark" SG_ 858 ACU_Time_Hour "";
BA_ "GenSigSendType" SG_ 858 ACU_Time_Hour 1;
BA_ "GenSigStartValue" SG_ 858 ACU_Time_Hour 1;
BA_ "Remark" SG_ 858 ACU_Time_Day "";
BA_ "GenSigSendType" SG_ 858 ACU_Time_Day 1;
BA_ "GenSigStartValue" SG_ 858 ACU_Time_Day 1;
BA_ "Remark" SG_ 858 ACU_Time_Month "";
BA_ "GenSigSendType" SG_ 858 ACU_Time_Month 1;
BA_ "GenSigStartValue" SG_ 858 ACU_Time_Month 1;
BA_ "Remark" SG_ 858 ACU_Time_Year "";
BA_ "GenSigSendType" SG_ 858 ACU_Time_Year 1;
BA_ "GenSigStartValue" SG_ 858 ACU_Time_Year 13;
BA_ "Remark" SG_ 129 ACU_LightShowFunCmd "";
BA_ "EventCommandSignal" SG_ 129 ACU_LightShowFunCmd 1;
BA_ "GatewayedSignals" SG_ 129 ACU_LightShowFunCmd 1;
BA_ "GenSigInvalidValue" SG_ 129 ACU_LightShowFunCmd 3;
BA_ "Remark" SG_ 129 ACU_LightShowModeSel "";
BA_ "EventCommandSignal" SG_ 129 ACU_LightShowModeSel 1;
BA_ "GatewayedSignals" SG_ 129 ACU_LightShowModeSel 1;
BA_ "Remark" SG_ 129 ACU_LightShowTimeFlag "";
BA_ "EventCommandSignal" SG_ 129 ACU_LightShowTimeFlag 1;
BA_ "GatewayedSignals" SG_ 129 ACU_LightShowTimeFlag 1;
BA_ "Remark" SG_ 129 ACU_GSM_DrvmodeMemCfg "";
BA_ "EventCommandSignal" SG_ 129 ACU_GSM_DrvmodeMemCfg 1;
BA_ "GatewayedSignals" SG_ 129 ACU_GSM_DrvmodeMemCfg 1;
BA_ "Remark" SG_ 129 ACU_XPowerModCfg "";
BA_ "EventCommandSignal" SG_ 129 ACU_XPowerModCfg 1;
BA_ "GatewayedSignals" SG_ 129 ACU_XPowerModCfg 1;
BA_ "Remark" SG_ 129 ACU_CDCStyleCfg "";
BA_ "EventCommandSignal" SG_ 129 ACU_CDCStyleCfg 1;
BA_ "GatewayedSignals" SG_ 129 ACU_CDCStyleCfg 1;
BA_ "GenSigStartValue" SG_ 129 ACU_CDCStyleCfg 2;
BA_ "Remark" SG_ 129 ACU_PAS_ButtonPress "";
BA_ "EventCommandSignal" SG_ 129 ACU_PAS_ButtonPress 1;
BA_ "GatewayedSignals" SG_ 129 ACU_PAS_ButtonPress 1;
BA_ "Remark" SG_ 129 ACU_DriveMode "";
BA_ "EventCommandSignal" SG_ 129 ACU_DriveMode 1;
BA_ "GatewayedSignals" SG_ 129 ACU_DriveMode 1;
BA_ "Remark" SG_ 129 ACU_HDCFuncSwCfg "";
BA_ "EventCommandSignal" SG_ 129 ACU_HDCFuncSwCfg 1;
BA_ "GatewayedSignals" SG_ 129 ACU_HDCFuncSwCfg 1;
BA_ "Remark" SG_ 129 ACU_ESPFuncSwCfg "";
BA_ "EventCommandSignal" SG_ 129 ACU_ESPFuncSwCfg 1;
BA_ "GatewayedSignals" SG_ 129 ACU_ESPFuncSwCfg 1;
BA_ "Remark" SG_ 129 ACU_ADB_FunCfg "";
BA_ "EventCommandSignal" SG_ 129 ACU_ADB_FunCfg 1;
BA_ "GatewayedSignals" SG_ 129 ACU_ADB_FunCfg 1;
BA_ "Remark" SG_ 129 ACU_AEBOff "";
BA_ "EventCommandSignal" SG_ 129 ACU_AEBOff 1;
BA_ "GatewayedSignals" SG_ 129 ACU_AEBOff 1;
BA_ "Remark" SG_ 129 ACU_FCWOff "";
BA_ "EventCommandSignal" SG_ 129 ACU_FCWOff 1;
BA_ "GatewayedSignals" SG_ 129 ACU_FCWOff 1;
BA_ "Remark" SG_ 129 ACU_FCWWarnDistanceCfg "";
BA_ "EventCommandSignal" SG_ 129 ACU_FCWWarnDistanceCfg 1;
BA_ "GatewayedSignals" SG_ 129 ACU_FCWWarnDistanceCfg 1;
BA_ "Remark" SG_ 129 ACU_FCW_SeatbeltPretensionWarnCf "";
BA_ "EventCommandSignal" SG_ 129 ACU_FCW_SeatbeltPretensionWarnCf 1;
BA_ "GatewayedSignals" SG_ 129 ACU_FCW_SeatbeltPretensionWarnCf 1;
BA_ "SystemSignalLongSymbol" SG_ 129 ACU_FCW_SeatbeltPretensionWarnCf "ACU_FCW_SeatbeltPretensionWarnCfg";
BA_ "Remark" SG_ 129 ACU_FCW_SeatVibrationWarnCfg "";
BA_ "EventCommandSignal" SG_ 129 ACU_FCW_SeatVibrationWarnCfg 1;
BA_ "GatewayedSignals" SG_ 129 ACU_FCW_SeatVibrationWarnCfg 1;
BA_ "Remark" SG_ 129 ACU_FCW_AcousticWarnCfg "";
BA_ "EventCommandSignal" SG_ 129 ACU_FCW_AcousticWarnCfg 1;
BA_ "GatewayedSignals" SG_ 129 ACU_FCW_AcousticWarnCfg 1;
BA_ "Remark" SG_ 129 ACU_ACC_StyleCfg "";
BA_ "EventCommandSignal" SG_ 129 ACU_ACC_StyleCfg 1;
BA_ "GatewayedSignals" SG_ 129 ACU_ACC_StyleCfg 1;
BA_ "Remark" SG_ 129 ACU_EPB_AutoModeCfg "";
BA_ "EventCommandSignal" SG_ 129 ACU_EPB_AutoModeCfg 1;
BA_ "GatewayedSignals" SG_ 129 ACU_EPB_AutoModeCfg 1;
BA_ "Remark" SG_ 129 ACU_EPS_StyleCfg "";
BA_ "EventCommandSignal" SG_ 129 ACU_EPS_StyleCfg 1;
BA_ "GatewayedSignals" SG_ 129 ACU_EPS_StyleCfg 1;
BA_ "Remark" SG_ 62 ACU_BCM_RLSAutoSRWinCloseCfgSt "";
BA_ "EventCommandSignal" SG_ 62 ACU_BCM_RLSAutoSRWinCloseCfgSt 1;
BA_ "Remark" SG_ 62 ACU_BCM_AutoSRWinCloseCfgSt "";
BA_ "EventCommandSignal" SG_ 62 ACU_BCM_AutoSRWinCloseCfgSt 1;
BA_ "Remark" SG_ 62 ACU_BCM_HeadlightDelayCfgSt "";
BA_ "EventCommandSignal" SG_ 62 ACU_BCM_HeadlightDelayCfgSt 1;
BA_ "Remark" SG_ 62 ACU_AVAS_SwitchCfgReq "";
BA_ "EventCommandSignal" SG_ 62 ACU_AVAS_SwitchCfgReq 1;
BA_ "Remark" SG_ 62 ACU_BCM_BCVehUnlockReq "";
BA_ "EventCommandSignal" SG_ 62 ACU_BCM_BCVehUnlockReq 1;
BA_ "Remark" SG_ 62 ACU_BCM_BCVehLockReq "";
BA_ "EventCommandSignal" SG_ 62 ACU_BCM_BCVehLockReq 1;
BA_ "Remark" SG_ 62 ACU_BCM_BCAutoDomeLightCtrl "";
BA_ "EventCommandSignal" SG_ 62 ACU_BCM_BCAutoDomeLightCtrl 1;
BA_ "Remark" SG_ 62 ACU_ICM_TripReset "";
BA_ "EventCommandSignal" SG_ 62 ACU_ICM_TripReset 1;
BA_ "Remark" SG_ 62 ACU_RearSeatBeltWarnCfg "";
BA_ "EventCommandSignal" SG_ 62 ACU_RearSeatBeltWarnCfg 1;
BA_ "Remark" SG_ 62 ACU_FuelEcoDistUnitDispSt "";
BA_ "EventCommandSignal" SG_ 62 ACU_FuelEcoDistUnitDispSt 1;
BA_ "Remark" SG_ 62 ACU_PrUnitDispCfg "";
BA_ "EventCommandSignal" SG_ 62 ACU_PrUnitDispCfg 1;
BA_ "Remark" SG_ 62 ACU_TempUnitDispCfg "";
BA_ "EventCommandSignal" SG_ 62 ACU_TempUnitDispCfg 1;
BA_ "Remark" SG_ 62 ACU_PEPS_IdInVeWarningCfg "";
BA_ "EventCommandSignal" SG_ 62 ACU_PEPS_IdInVeWarningCfg 1;
BA_ "Remark" SG_ 62 ACU_MultiIDManageReq "";
BA_ "EventCommandSignal" SG_ 62 ACU_MultiIDManageReq 1;
BA_ "Remark" SG_ 62 ACU_BCM_AutoWiperCfg "";
BA_ "Remark" SG_ 62 ACU_BCM_IALFuncCfg "";
BA_ "EventCommandSignal" SG_ 62 ACU_BCM_IALFuncCfg 1;
BA_ "Remark" SG_ 62 ACU_BCMHornCfg "";
BA_ "EventCommandSignal" SG_ 62 ACU_BCMHornCfg 1;
BA_ "Remark" SG_ 62 ACU_BCM_DTRLFuncCfg "";
BA_ "EventCommandSignal" SG_ 62 ACU_BCM_DTRLFuncCfg 1;
BA_ "Remark" SG_ 62 ACU_BCM_RGearEnableRearWipeCfg "";
BA_ "EventCommandSignal" SG_ 62 ACU_BCM_RGearEnableRearWipeCfg 1;
BA_ "Remark" SG_ 62 ACU_BCM_FrontWiperSerPstFuncCfg "";
BA_ "EventCommandSignal" SG_ 62 ACU_BCM_FrontWiperSerPstFuncCfg 1;
BA_ "Remark" SG_ 62 ACU_BCM_FrontWiperSerPstReq "";
BA_ "EventCommandSignal" SG_ 62 ACU_BCM_FrontWiperSerPstReq 1;
BA_ "Remark" SG_ 62 ACU_BCM_AutoLightSnsCfg "";
BA_ "EventCommandSignal" SG_ 62 ACU_BCM_AutoLightSnsCfg 1;
BA_ "Remark" SG_ 62 ACU_BCM_FollowMeHomeCfg "";
BA_ "EventCommandSignal" SG_ 62 ACU_BCM_FollowMeHomeCfg 1;
BA_ "Remark" SG_ 62 ACU_BCMAutoUnlockCfg "";
BA_ "EventCommandSignal" SG_ 62 ACU_BCMAutoUnlockCfg 1;
BA_ "Remark" SG_ 62 ACU_BCMSpdAutoLockCfg "";
BA_ "EventCommandSignal" SG_ 62 ACU_BCMSpdAutoLockCfg 1;
BA_ "Remark" SG_ 62 ACU_BCMRemoteUnlockCfg "";
BA_ "EventCommandSignal" SG_ 62 ACU_BCMRemoteUnlockCfg 1;
BA_ "Remark" SG_ 62 ACU_BCM_FogLampTurnCfg "";
BA_ "EventCommandSignal" SG_ 62 ACU_BCM_FogLampTurnCfg 1;
BA_ "Remark" SG_ 62 ACU_BCM_RemoteCtrlFDMRMCfg "";
BA_ "EventCommandSignal" SG_ 62 ACU_BCM_RemoteCtrlFDMRMCfg 1;
BA_ "Remark" SG_ 61 ACU_PEPS_KickSnsCfg "";
BA_ "EventCommandSignal" SG_ 61 ACU_PEPS_KickSnsCfg 1;
BA_ "Remark" SG_ 61 ACU_PEPS_MaxTeleEngTimerCfg "";
BA_ "EventCommandSignal" SG_ 61 ACU_PEPS_MaxTeleEngTimerCfg 1;
BA_ "GenSigStartValue" SG_ 61 ACU_PEPS_MaxTeleEngTimerCfg 63;
BA_ "Remark" SG_ 61 ACU_PEPS_OffCfg "";
BA_ "EventCommandSignal" SG_ 61 ACU_PEPS_OffCfg 1;
BA_ "Remark" SG_ 61 ACU_PEPS_MaxTeleIGNOnTimerCfg "";
BA_ "EventCommandSignal" SG_ 61 ACU_PEPS_MaxTeleIGNOnTimerCfg 1;
BA_ "GenSigStartValue" SG_ 61 ACU_PEPS_MaxTeleIGNOnTimerCfg 63;
BA_ "Remark" SG_ 61 ACU_PEPSAPUCfg "";
BA_ "EventCommandSignal" SG_ 61 ACU_PEPSAPUCfg 1;
BA_ "Remark" SG_ 61 ACU_PEPSWALCfg "";
BA_ "EventCommandSignal" SG_ 61 ACU_PEPSWALCfg 1;
BA_ "Remark" SG_ 61 ACU_ICM_LanguageCfg "";
BA_ "EventCommandSignal" SG_ 61 ACU_ICM_LanguageCfg 1;
BA_ "Remark" SG_ 61 ACU_ICM_TimeModeCfg "";
BA_ "EventCommandSignal" SG_ 61 ACU_ICM_TimeModeCfg 1;
BA_ "Remark" SG_ 61 ACU_ICM_WarnSoundVolCfg "";
BA_ "EventCommandSignal" SG_ 61 ACU_ICM_WarnSoundVolCfg 1;
BA_ "Remark" SG_ 61 ACU_ICM_SpdWarnCfg "";
BA_ "EventCommandSignal" SG_ 61 ACU_ICM_SpdWarnCfg 1;
BA_ "GenSigStartValue" SG_ 61 ACU_ICM_SpdWarnCfg 31;
BA_ "Remark" SG_ 61 ACU_HVACF_AutoDefCfg "";
BA_ "EventCommandSignal" SG_ 61 ACU_HVACF_AutoDefCfg 1;
BA_ "Remark" SG_ 61 ACU_HVACF_AQSCfg "";
BA_ "EventCommandSignal" SG_ 61 ACU_HVACF_AQSCfg 1;
BA_ "Remark" SG_ 61 ACU_PEPSSATOCfg "";
BA_ "EventCommandSignal" SG_ 61 ACU_PEPSSATOCfg 1;
BA_ "Remark" SG_ 61 ACU_PEPS_WELCfg "";
BA_ "EventCommandSignal" SG_ 61 ACU_PEPS_WELCfg 1;
BA_ "Remark" SG_ 61 ACU_BCMOSRMAutoFoldCfg "";
BA_ "EventCommandSignal" SG_ 61 ACU_BCMOSRMAutoFoldCfg 1;
BA_ "Remark" SG_ 61 ACU_MSM_KeyRecognitionCfg "";
BA_ "EventCommandSignal" SG_ 61 ACU_MSM_KeyRecognitionCfg 1;
BA_ "Remark" SG_ 61 ACU_MSMWelcomeFuncCfg "";
BA_ "EventCommandSignal" SG_ 61 ACU_MSMWelcomeFuncCfg 1;
BA_ "Remark" SG_ 61 ACU_RRHVSMAutoModeCfg "";
BA_ "EventCommandSignal" SG_ 61 ACU_RRHVSMAutoModeCfg 1;
BA_ "Remark" SG_ 61 ACU_RLHVSMAutoModeCfg "";
BA_ "EventCommandSignal" SG_ 61 ACU_RLHVSMAutoModeCfg 1;
BA_ "Remark" SG_ 61 ACU_FRHVSMAutoModeCfg "";
BA_ "EventCommandSignal" SG_ 61 ACU_FRHVSMAutoModeCfg 1;
BA_ "Remark" SG_ 61 ACU_FLHVSMAutoModeCfg "";
BA_ "EventCommandSignal" SG_ 61 ACU_FLHVSMAutoModeCfg 1;
BA_ "Remark" SG_ 61 ACU_HVACF_IonModeCfg "";
BA_ "EventCommandSignal" SG_ 61 ACU_HVACF_IonModeCfg 1;
BA_ "Remark" SG_ 61 ACU_HVACF_ComfortCfg "";
BA_ "EventCommandSignal" SG_ 61 ACU_HVACF_ComfortCfg 1;
BA_ "Remark" SG_ 61 ACU_HVACFAirCirCfg "";
BA_ "EventCommandSignal" SG_ 61 ACU_HVACFAirCirCfg 1;
BA_ "Remark" SG_ 61 ACU_HVACF_ACCfg "";
BA_ "EventCommandSignal" SG_ 61 ACU_HVACF_ACCfg 1;
BA_ "Remark" SG_ 821 ACU_HUD_OffSt "";
BA_ "GenSigSendType" SG_ 821 ACU_HUD_OffSt 1;
BA_ "GenSigInvalidValue" SG_ 821 ACU_HUD_OffSt 3;
BA_ "Remark" SG_ 821 ACU_TELBcallReq "";
BA_ "GenSigSendType" SG_ 821 ACU_TELBcallReq 1;
BA_ "Remark" SG_ 821 ACU_HUDADASCruiseDisReq "";
BA_ "GenSigSendType" SG_ 821 ACU_HUDADASCruiseDisReq 1;
BA_ "GenSigInvalidValue" SG_ 821 ACU_HUDADASCruiseDisReq 3;
BA_ "Remark" SG_ 821 ACU_HUD_NAV "";
BA_ "GenSigSendType" SG_ 821 ACU_HUD_NAV 1;
BA_ "GenSigInvalidValue" SG_ 821 ACU_HUD_NAV 3;
BA_ "Remark" SG_ 821 ACU_HUDADASTSRDisReq "";
BA_ "GenSigSendType" SG_ 821 ACU_HUDADASTSRDisReq 1;
BA_ "GenSigInvalidValue" SG_ 821 ACU_HUDADASTSRDisReq 3;
BA_ "Remark" SG_ 821 ACU_HUD_BrightnessSt "";
BA_ "GenSigSendType" SG_ 821 ACU_HUD_BrightnessSt 1;
BA_ "GenSigInvalidValue" SG_ 821 ACU_HUD_BrightnessSt 21;
BA_ "Remark" SG_ 821 ACU_SVMViewPosReq "";
BA_ "GenSigSendType" SG_ 821 ACU_SVMViewPosReq 1;
BA_ "Remark" SG_ 821 ACU_ModeChangeInf "";
BA_ "GenSigSendType" SG_ 821 ACU_ModeChangeInf 1;
BA_ "Remark" SG_ 821 ACU_HUD_HeightSt "";
BA_ "GenSigSendType" SG_ 821 ACU_HUD_HeightSt 1;
BA_ "GenSigInvalidValue" SG_ 821 ACU_HUD_HeightSt 21;
BA_ "Remark" SG_ 821 ACU_HUD_AngleSt "";
BA_ "GenSigSendType" SG_ 821 ACU_HUD_AngleSt 1;
BA_ "GenSigInvalidValue" SG_ 821 ACU_HUD_AngleSt 21;
BA_ "Remark" SG_ 821 ACU_TeleModeActSt "";
BA_ "GenSigSendType" SG_ 821 ACU_TeleModeActSt 1;
BA_ "Remark" SG_ 821 ACU_CallMuteModeAct "";
BA_ "GenSigSendType" SG_ 821 ACU_CallMuteModeAct 1;
BA_ "Remark" SG_ 821 ACU_SetupConfig "";
BA_ "GenSigSendType" SG_ 821 ACU_SetupConfig 1;
BA_ "Remark" SG_ 821 ACU_MusicSt "";
BA_ "GenSigSendType" SG_ 821 ACU_MusicSt 1;
BA_ "Remark" SG_ 821 ACU_KeyREWSt "";
BA_ "GenSigSendType" SG_ 821 ACU_KeyREWSt 1;
BA_ "Remark" SG_ 821 ACU_KeyFFWSt "";
BA_ "GenSigSendType" SG_ 821 ACU_KeyFFWSt 1;
BA_ "Remark" SG_ 821 ACU_Key6St "";
BA_ "GenSigSendType" SG_ 821 ACU_Key6St 1;
BA_ "Remark" SG_ 821 ACU_Key5St "";
BA_ "GenSigSendType" SG_ 821 ACU_Key5St 1;
BA_ "Remark" SG_ 821 ACU_CallAnswerMode "";
BA_ "GenSigSendType" SG_ 821 ACU_CallAnswerMode 1;
BA_ "Remark" SG_ 821 ACU_PhoneCallReq "";
BA_ "GenSigSendType" SG_ 821 ACU_PhoneCallReq 1;
BA_ "Remark" SG_ 821 ACU_Key4St "";
BA_ "GenSigSendType" SG_ 821 ACU_Key4St 1;
BA_ "Remark" SG_ 821 ACU_Key3St "";
BA_ "GenSigSendType" SG_ 821 ACU_Key3St 1;
BA_ "Remark" SG_ 821 ACU_Key2St "";
BA_ "GenSigSendType" SG_ 821 ACU_Key2St 1;
BA_ "Remark" SG_ 821 ACU_Key1St "";
BA_ "GenSigSendType" SG_ 821 ACU_Key1St 1;
BA_ "Remark" SG_ 814 ACU_IFC_SLCAheadDis "";
BA_ "GatewayedSignals" SG_ 814 ACU_IFC_SLCAheadDis 1;
BA_ "GenSigSendType" SG_ 814 ACU_IFC_SLCAheadDis 1;
BA_ "Remark" SG_ 814 ACU_IFC_NaviNewIcon "";
BA_ "GatewayedSignals" SG_ 814 ACU_IFC_NaviNewIcon 1;
BA_ "GenSigSendType" SG_ 814 ACU_IFC_NaviNewIcon 1;
BA_ "Remark" SG_ 814 ACU_IFC_NaviNewIconDis "";
BA_ "GatewayedSignals" SG_ 814 ACU_IFC_NaviNewIconDis 1;
BA_ "GenSigSendType" SG_ 814 ACU_IFC_NaviNewIconDis 1;
BA_ "Remark" SG_ 814 ACU_IFC_OfframpSt "";
BA_ "GatewayedSignals" SG_ 814 ACU_IFC_OfframpSt 1;
BA_ "GenSigSendType" SG_ 814 ACU_IFC_OfframpSt 1;
BA_ "GenSigTimeoutValue" SG_ 814 ACU_IFC_ZoneCode 1;
BA_ "Remark" SG_ 814 ACU_IFC_ZoneCode "";
BA_ "GatewayedSignals" SG_ 814 ACU_IFC_ZoneCode 1;
BA_ "GenSigSendType" SG_ 814 ACU_IFC_ZoneCode 1;
BA_ "Remark" SG_ 814 ACU_IFC_NaviSt "";
BA_ "GatewayedSignals" SG_ 814 ACU_IFC_NaviSt 1;
BA_ "GenSigSendType" SG_ 814 ACU_IFC_NaviSt 1;
BA_ "Remark" SG_ 814 ACU_IFC_NaviCorp "";
BA_ "GatewayedSignals" SG_ 814 ACU_IFC_NaviCorp 1;
BA_ "GenSigSendType" SG_ 814 ACU_IFC_NaviCorp 1;
BA_ "Remark" SG_ 814 ACU_IFC_SpeedLimtType "";
BA_ "GatewayedSignals" SG_ 814 ACU_IFC_SpeedLimtType 1;
BA_ "GenSigSendType" SG_ 814 ACU_IFC_SpeedLimtType 1;
BA_ "Remark" SG_ 814 ACU_IFC_RoadType "";
BA_ "GatewayedSignals" SG_ 814 ACU_IFC_RoadType 1;
BA_ "GenSigSendType" SG_ 814 ACU_IFC_RoadType 1;
BA_ "GenSigTimeoutValue" SG_ 814 ACU_IFC_SpeedLimitUnit 1;
BA_ "Remark" SG_ 814 ACU_IFC_SpeedLimitUnit "";
BA_ "GatewayedSignals" SG_ 814 ACU_IFC_SpeedLimitUnit 1;
BA_ "GenSigSendType" SG_ 814 ACU_IFC_SpeedLimitUnit 1;
BA_ "Remark" SG_ 814 ACU_IFC_OfframpDis "";
BA_ "GatewayedSignals" SG_ 814 ACU_IFC_OfframpDis 1;
BA_ "GenSigSendType" SG_ 814 ACU_IFC_OfframpDis 1;
BA_ "Remark" SG_ 814 ACU_IFC_ISDRestOfdis "";
BA_ "GatewayedSignals" SG_ 814 ACU_IFC_ISDRestOfdis 1;
BA_ "GenSigSendType" SG_ 814 ACU_IFC_ISDRestOfdis 1;
BA_ "Remark" SG_ 814 ACU_IFC_SpeedLimit "";
BA_ "GatewayedSignals" SG_ 814 ACU_IFC_SpeedLimit 1;
BA_ "GenSigSendType" SG_ 814 ACU_IFC_SpeedLimit 1;
BA_ "Remark" SG_ 849 ACU_MediaPlayMin "";
BA_ "GenSigSendType" SG_ 849 ACU_MediaPlayMin 1;
BA_ "GenSigStartValue" SG_ 849 ACU_MediaPlayMin 1;
BA_ "Remark" SG_ 849 ACU_MediaPlaySec "";
BA_ "GenSigSendType" SG_ 849 ACU_MediaPlaySec 1;
BA_ "GenSigStartValue" SG_ 849 ACU_MediaPlaySec 1;
BA_ "Remark" SG_ 849 ACU_MediaPlayHour "";
BA_ "GenSigSendType" SG_ 849 ACU_MediaPlayHour 1;
BA_ "GenSigStartValue" SG_ 849 ACU_MediaPlayHour 1;
BA_ "Remark" SG_ 849 ACU_MediaPlayTotalMin "";
BA_ "GenSigSendType" SG_ 849 ACU_MediaPlayTotalMin 1;
BA_ "GenSigStartValue" SG_ 849 ACU_MediaPlayTotalMin 1;
BA_ "Remark" SG_ 849 ACU_MediaPlayTotalSec "";
BA_ "GenSigSendType" SG_ 849 ACU_MediaPlayTotalSec 1;
BA_ "GenSigStartValue" SG_ 849 ACU_MediaPlayTotalSec 1;
BA_ "Remark" SG_ 849 ACU_MediaPlayTotalHour "";
BA_ "GenSigSendType" SG_ 849 ACU_MediaPlayTotalHour 1;
BA_ "GenSigStartValue" SG_ 849 ACU_MediaPlayTotalHour 1;
BA_ "Remark" SG_ 849 ACU_CurrentAMFreq "";
BA_ "GenSigSendType" SG_ 849 ACU_CurrentAMFreq 1;
BA_ "GenSigStartValue" SG_ 849 ACU_CurrentAMFreq 2047;
BA_ "Remark" SG_ 849 ACU_CurrentSource "";
BA_ "GenSigSendType" SG_ 849 ACU_CurrentSource 1;
BA_ "Remark" SG_ 849 ACU_CurrentFMFreq "";
BA_ "GenSigSendType" SG_ 849 ACU_CurrentFMFreq 1;
BA_ "GenSigStartValue" SG_ 849 ACU_CurrentFMFreq 8191;
BA_ "Remark" SG_ 849 ACU_MediaChangeFlag "";
BA_ "GenSigSendType" SG_ 849 ACU_MediaChangeFlag 1;
BA_ "Remark" SG_ 849 ACU_SearchStationMode "";
BA_ "GenSigSendType" SG_ 849 ACU_SearchStationMode 1;
BA_ "Remark" SG_ 945 ACU_ICM_SynchDriveMode "";
BA_ "GenSigSendType" SG_ 945 ACU_ICM_SynchDriveMode 1;
BA_ "Remark" SG_ 945 ACU_ICM_SynchDispID "";
BA_ "GenSigSendType" SG_ 945 ACU_ICM_SynchDispID 1;
BA_ "Remark" SG_ 945 ACU_APP_PhoneReady "";
BA_ "GenSigSendType" SG_ 945 ACU_APP_PhoneReady 1;
BA_ "Remark" SG_ 945 ACU_APP_NaviReady "";
BA_ "GenSigSendType" SG_ 945 ACU_APP_NaviReady 1;
BA_ "Remark" SG_ 945 ACU_APP_MeadiaReady "";
BA_ "GenSigSendType" SG_ 945 ACU_APP_MeadiaReady 1;
BA_ "Remark" SG_ 945 ACU_SystemReady "";
BA_ "GenSigSendType" SG_ 945 ACU_SystemReady 1;
BA_ "Remark" SG_ 945 ACU_PhoneCallSec "";
BA_ "GenSigSendType" SG_ 945 ACU_PhoneCallSec 1;
BA_ "GenSigStartValue" SG_ 945 ACU_PhoneCallSec 1;
BA_ "Remark" SG_ 945 ACU_PhoneCallMin "";
BA_ "GenSigSendType" SG_ 945 ACU_PhoneCallMin 1;
BA_ "GenSigStartValue" SG_ 945 ACU_PhoneCallMin 1;
BA_ "Remark" SG_ 945 ACU_PhoneCallHour "";
BA_ "GenSigSendType" SG_ 945 ACU_PhoneCallHour 1;
BA_ "GenSigStartValue" SG_ 945 ACU_PhoneCallHour 1;
BA_ "Remark" SG_ 945 ACU_PhoneType "";
BA_ "GenSigSendType" SG_ 945 ACU_PhoneType 1;
BA_ "Remark" SG_ 945 ACU_PhoneSt "";
BA_ "GenSigSendType" SG_ 945 ACU_PhoneSt 1;
BA_ "Remark" SG_ 921 ACU_NaviDestDistInfo "";
BA_ "GenSigSendType" SG_ 921 ACU_NaviDestDistInfo 1;
BA_ "Remark" SG_ 921 ACU_NaviHour "";
BA_ "GenSigSendType" SG_ 921 ACU_NaviHour 1;
BA_ "GenSigStartValue" SG_ 921 ACU_NaviHour 1;
BA_ "Remark" SG_ 921 ACU_NaviMinitue "";
BA_ "GenSigSendType" SG_ 921 ACU_NaviMinitue 1;
BA_ "GenSigStartValue" SG_ 921 ACU_NaviMinitue 1;
BA_ "Remark" SG_ 921 ACU_NaviDestDistUnit "";
BA_ "GenSigSendType" SG_ 921 ACU_NaviDestDistUnit 1;
BA_ "Remark" SG_ 921 ACU_NaviSt "";
BA_ "GenSigSendType" SG_ 921 ACU_NaviSt 1;
BA_ "Remark" SG_ 911 ACU_CharacterTransData "";
BA_ "GenSigSendType" SG_ 911 ACU_CharacterTransData 1;
BA_ "Remark" SG_ 911 ACU_CharacterTransPCI "";
BA_ "GenSigSendType" SG_ 911 ACU_CharacterTransPCI 1;
BA_ "Remark" SG_ 830 ACU_NaviDistBar "";
BA_ "GenSigSendType" SG_ 830 ACU_NaviDistBar 1;
BA_ "Remark" SG_ 830 ACU_NaviDist "";
BA_ "GenSigSendType" SG_ 830 ACU_NaviDist 1;
BA_ "Remark" SG_ 830 ACU_NaviIcon_WS "";
BA_ "GenSigSendType" SG_ 830 ACU_NaviIcon_WS 1;
BA_ "Remark" SG_ 830 ACU_NaviIcon_RC "";
BA_ "GenSigSendType" SG_ 830 ACU_NaviIcon_RC 1;
BA_ "Remark" SG_ 830 ACU_NaviIcon_TBT "";
BA_ "GenSigSendType" SG_ 830 ACU_NaviIcon_TBT 1;
BA_ "Remark" SG_ 830 ACU_NaviDistUnit "";
BA_ "GenSigSendType" SG_ 830 ACU_NaviDistUnit 1;
BA_ "Remark" SG_ 830 ACU_NaviRoadChangeFlag "";
BA_ "GenSigSendType" SG_ 830 ACU_NaviRoadChangeFlag 1;
BA_ "Remark" SG_ 825 ACU_NaviDestDistance "";
BA_ "GenSigSendType" SG_ 825 ACU_NaviDestDistance 1;
BA_ "Remark" SG_ 825 ACU_AltitudeInteger "";
BA_ "GenSigSendType" SG_ 825 ACU_AltitudeInteger 1;
BA_ "Remark" SG_ 825 ACU_AzimuthInfo "";
BA_ "GenSigSendType" SG_ 825 ACU_AzimuthInfo 1;
BA_ "Remark" SG_ 825 ACU_GPSSignalSt "";
BA_ "GenSigSendType" SG_ 825 ACU_GPSSignalSt 1;
BA_ "Remark" SG_ 825 ACU_SeaLevel "";
BA_ "GenSigSendType" SG_ 825 ACU_SeaLevel 1;
BA_ "Remark" SG_ 825 ACU_AltitudeDecimal "";
BA_ "GenSigSendType" SG_ 825 ACU_AltitudeDecimal 1;
BA_ "EventCommandSignal" SG_ 131 ACU_AVHSoftSwitchst 1;
BA_ "GatewayedSignals" SG_ 131 ACU_AVHSoftSwitchst 1;
BA_ "Remark" SG_ 131 ACU_RCWTypeReqCfg "";
BA_ "EventCommandSignal" SG_ 131 ACU_RCWTypeReqCfg 1;
BA_ "GatewayedSignals" SG_ 131 ACU_RCWTypeReqCfg 1;
BA_ "Remark" SG_ 131 ACU_DragModeReq "";
BA_ "EventCommandSignal" SG_ 131 ACU_DragModeReq 1;
BA_ "GenSigSendType" SG_ 131 ACU_DragModeReq 1;
BA_ "Remark" SG_ 131 ACU_FaceIDSwitch "";
BA_ "EventCommandSignal" SG_ 131 ACU_FaceIDSwitch 1;
BA_ "GatewayedSignals" SG_ 131 ACU_FaceIDSwitch 1;
BA_ "Remark" SG_ 131 ACU_FaceIDQuit "";
BA_ "EventCommandSignal" SG_ 131 ACU_FaceIDQuit 1;
BA_ "GatewayedSignals" SG_ 131 ACU_FaceIDQuit 1;
BA_ "Remark" SG_ 131 ACU_VerifyTriger "";
BA_ "EventCommandSignal" SG_ 131 ACU_VerifyTriger 1;
BA_ "GatewayedSignals" SG_ 131 ACU_VerifyTriger 1;
BA_ "Remark" SG_ 131 ACU_RegisterTriger "";
BA_ "EventCommandSignal" SG_ 131 ACU_RegisterTriger 1;
BA_ "GatewayedSignals" SG_ 131 ACU_RegisterTriger 1;
BA_ "Remark" SG_ 131 ACU_FCTA_TypeReqCfg "";
BA_ "EventCommandSignal" SG_ 131 ACU_FCTA_TypeReqCfg 1;
BA_ "GatewayedSignals" SG_ 131 ACU_FCTA_TypeReqCfg 1;
BA_ "Remark" SG_ 131 ACU_RCTA_TypeReqCfg "";
BA_ "EventCommandSignal" SG_ 131 ACU_RCTA_TypeReqCfg 1;
BA_ "GatewayedSignals" SG_ 131 ACU_RCTA_TypeReqCfg 1;
BA_ "Remark" SG_ 131 ACU_RAWCfg "";
BA_ "EventCommandSignal" SG_ 131 ACU_RAWCfg 1;
BA_ "GatewayedSignals" SG_ 131 ACU_RAWCfg 1;
BA_ "Remark" SG_ 131 ACU_FCTACfg "";
BA_ "EventCommandSignal" SG_ 131 ACU_FCTACfg 1;
BA_ "GatewayedSignals" SG_ 131 ACU_FCTACfg 1;
BA_ "Remark" SG_ 131 ACU_ELKCfg "";
BA_ "EventCommandSignal" SG_ 131 ACU_ELKCfg 1;
BA_ "GatewayedSignals" SG_ 131 ACU_ELKCfg 1;
BA_ "Remark" SG_ 131 ACU_WCM_SwitchStCfg "";
BA_ "EventCommandSignal" SG_ 131 ACU_WCM_SwitchStCfg 1;
BA_ "Remark" SG_ 131 ACU_HUD_DisplayTypeCfg "";
BA_ "EventCommandSignal" SG_ 131 ACU_HUD_DisplayTypeCfg 1;
BA_ "Remark" SG_ 131 ACU_HUD_DisplayPosCfg "";
BA_ "EventCommandSignal" SG_ 131 ACU_HUD_DisplayPosCfg 1;
BA_ "Remark" SG_ 131 ACU_HUD_BacklightLevelCfg "";
BA_ "EventCommandSignal" SG_ 131 ACU_HUD_BacklightLevelCfg 1;
BA_ "Remark" SG_ 130 ACU_ADASWarnTypeSwitch "";
BA_ "EventCommandSignal" SG_ 130 ACU_ADASWarnTypeSwitch 1;
BA_ "GatewayedSignals" SG_ 130 ACU_ADASWarnTypeSwitch 1;
BA_ "Remark" SG_ 130 ACU_HWA_SwitchReq "";
BA_ "EventCommandSignal" SG_ 130 ACU_HWA_SwitchReq 1;
BA_ "GatewayedSignals" SG_ 130 ACU_HWA_SwitchReq 1;
BA_ "Remark" SG_ 130 ACU_RAEBcfg "";
BA_ "EventCommandSignal" SG_ 130 ACU_RAEBcfg 1;
BA_ "GatewayedSignals" SG_ 130 ACU_RAEBcfg 1;
BA_ "Remark" SG_ 130 ACU_TSR_AudioWarnReq "";
BA_ "EventCommandSignal" SG_ 130 ACU_TSR_AudioWarnReq 1;
BA_ "GatewayedSignals" SG_ 130 ACU_TSR_AudioWarnReq 1;
BA_ "Remark" SG_ 130 ACU_DMSMode "";
BA_ "EventCommandSignal" SG_ 130 ACU_DMSMode 1;
BA_ "GatewayedSignals" SG_ 130 ACU_DMSMode 1;
BA_ "Remark" SG_ 130 ACU_DMSSwitch "";
BA_ "EventCommandSignal" SG_ 130 ACU_DMSSwitch 1;
BA_ "GatewayedSignals" SG_ 130 ACU_DMSSwitch 1;
BA_ "Remark" SG_ 130 ACU_iACC_SwitchReq "";
BA_ "EventCommandSignal" SG_ 130 ACU_iACC_SwitchReq 1;
BA_ "GatewayedSignals" SG_ 130 ACU_iACC_SwitchReq 1;
BA_ "Remark" SG_ 130 ACU_DOWCfg "";
BA_ "EventCommandSignal" SG_ 130 ACU_DOWCfg 1;
BA_ "GatewayedSignals" SG_ 130 ACU_DOWCfg 1;
BA_ "Remark" SG_ 130 ACU_RCTACfg "";
BA_ "EventCommandSignal" SG_ 130 ACU_RCTACfg 1;
BA_ "GatewayedSignals" SG_ 130 ACU_RCTACfg 1;
BA_ "Remark" SG_ 130 ACU_BSDCfg "";
BA_ "EventCommandSignal" SG_ 130 ACU_BSDCfg 1;
BA_ "GatewayedSignals" SG_ 130 ACU_BSDCfg 1;
BA_ "Remark" SG_ 130 ACU_IFC_SpeedLimtValueType "";
BA_ "EventCommandSignal" SG_ 130 ACU_IFC_SpeedLimtValueType 1;
BA_ "GatewayedSignals" SG_ 130 ACU_IFC_SpeedLimtValueType 1;
BA_ "Remark" SG_ 130 ACU_LKS_TypeReq "";
BA_ "EventCommandSignal" SG_ 130 ACU_LKS_TypeReq 1;
BA_ "GatewayedSignals" SG_ 130 ACU_LKS_TypeReq 1;
BA_ "Remark" SG_ 130 ACU_HMA_SwitchReq "";
BA_ "EventCommandSignal" SG_ 130 ACU_HMA_SwitchReq 1;
BA_ "GatewayedSignals" SG_ 130 ACU_HMA_SwitchReq 1;
BA_ "Remark" SG_ 130 ACU_TSR_SwitchReq "";
BA_ "EventCommandSignal" SG_ 130 ACU_TSR_SwitchReq 1;
BA_ "GatewayedSignals" SG_ 130 ACU_TSR_SwitchReq 1;
BA_ "Remark" SG_ 130 ACU_LKS_Sensitivity "";
BA_ "EventCommandSignal" SG_ 130 ACU_LKS_Sensitivity 1;
BA_ "GatewayedSignals" SG_ 130 ACU_LKS_Sensitivity 1;
BA_ "Remark" SG_ 130 ACU_IFC_CruiseModeCfg "";
BA_ "EventCommandSignal" SG_ 130 ACU_IFC_CruiseModeCfg 1;
BA_ "GatewayedSignals" SG_ 130 ACU_IFC_CruiseModeCfg 1;
BA_ "Remark" SG_ 130 ACU_SVM_RightBlindViewReq "";
BA_ "EventCommandSignal" SG_ 130 ACU_SVM_RightBlindViewReq 1;
BA_ "GatewayedSignals" SG_ 130 ACU_SVM_RightBlindViewReq 1;
BA_ "Remark" SG_ 130 ACU_SVM_LeftBlindViewReq "";
BA_ "EventCommandSignal" SG_ 130 ACU_SVM_LeftBlindViewReq 1;
BA_ "GatewayedSignals" SG_ 130 ACU_SVM_LeftBlindViewReq 1;
BA_ "Remark" SG_ 130 ACU_LDW_WarmSnsCfg "";
BA_ "EventCommandSignal" SG_ 130 ACU_LDW_WarmSnsCfg 1;
BA_ "GatewayedSignals" SG_ 130 ACU_LDW_WarmSnsCfg 1;
BA_ "Remark" SG_ 130 ACU_LDW_LKACfg "";
BA_ "EventCommandSignal" SG_ 130 ACU_LDW_LKACfg 1;
BA_ "GatewayedSignals" SG_ 130 ACU_LDW_LKACfg 1;
BA_ "Remark" SG_ 84 ACU_PCS_LadarTriggerSVMset "A8E新增2";
BA_ "Remark" SG_ 84 ACU_PCS_TurnFollowSet "A8E新增2";
BA_ "Remark" SG_ 84 ACU_PCS_ParkGearExitSet "A8E新增2";
BA_ "Remark" SG_ 84 ACU_PCS_TrajectoryLineSet "A8E新增2";
BA_ "Remark" SG_ 84 ACU_PCS_ScreenCoordX "";
BA_ "EventCommandSignal" SG_ 84 ACU_PCS_ScreenCoordX 1;
BA_ "GatewayedSignals" SG_ 84 ACU_PCS_ScreenCoordX 1;
BA_ "Remark" SG_ 84 ACU_PCS_ScreenCoordY "";
BA_ "EventCommandSignal" SG_ 84 ACU_PCS_ScreenCoordY 1;
BA_ "GatewayedSignals" SG_ 84 ACU_PCS_ScreenCoordY 1;
BA_ "Remark" SG_ 84 ACU_PCS_CurrentSceenSt "A8E新增2";
BA_ "GenSigSendType" SG_ 84 ACU_PCS_CurrentSceenSt 1;
BA_ "Remark" SG_ 84 ACU_PCS_ScreenTouchSt "";
BA_ "GatewayedSignals" SG_ 84 ACU_PCS_ScreenTouchSt 1;
BA_ "Remark" SG_ 84 ACU_PCS_ER_QuitConfirm "";
BA_ "GatewayedSignals" SG_ 84 ACU_PCS_ER_QuitConfirm 1;
BA_ "Remark" SG_ 84 ACU_PCS_ER_EnterCmd "";
BA_ "GatewayedSignals" SG_ 84 ACU_PCS_ER_EnterCmd 1;
BA_ "Remark" SG_ 84 ACU_ER_FuncCfg "";
BA_ "GatewayedSignals" SG_ 84 ACU_ER_FuncCfg 1;
BA_ "Remark" SG_ 84 ACU_PCS_AdjParkPosCmd "";
BA_ "GatewayedSignals" SG_ 84 ACU_PCS_AdjParkPosCmd 1;
BA_ "Remark" SG_ 84 ACU_PCS_SVM_PGSReturnCmd "";
BA_ "GatewayedSignals" SG_ 84 ACU_PCS_SVM_PGSReturnCmd 1;
BA_ "Remark" SG_ 84 ACU_PCS_SVM_SoundReminderCmd "";
BA_ "GatewayedSignals" SG_ 84 ACU_PCS_SVM_SoundReminderCmd 1;
BA_ "Remark" SG_ 84 ACU_PCS_SVM_ViewModeCmd "";
BA_ "GatewayedSignals" SG_ 84 ACU_PCS_SVM_ViewModeCmd 1;
BA_ "Remark" SG_ 84 ACU_PCS_SVM_MODCmd "";
BA_ "GatewayedSignals" SG_ 84 ACU_PCS_SVM_MODCmd 1;
BA_ "Remark" SG_ 84 ACU_PCS_SVM_PGSCmd "";
BA_ "GatewayedSignals" SG_ 84 ACU_PCS_SVM_PGSCmd 1;
BA_ "Remark" SG_ 84 ACU_PCS_SVM_SingleViewCmd "";
BA_ "GatewayedSignals" SG_ 84 ACU_PCS_SVM_SingleViewCmd 1;
BA_ "Remark" SG_ 84 ACU_PCS_SVM_FunctionCmd "";
BA_ "GatewayedSignals" SG_ 84 ACU_PCS_SVM_FunctionCmd 1;
BA_ "EventCommandSignal" SG_ 158 ACU_APAVoiceRmdercfg 1;
BA_ "EventCommandSignal" SG_ 158 ACU_VR_APAControl 1;
BA_ "Remark" SG_ 158 ACU_PAAMode "";
BA_ "EventCommandSignal" SG_ 158 ACU_PAAMode 1;
VAL_ 1015 ACU_RRSeatOperationReq 15 "Not used" 14 "Not used" 13 "Not used" 12 "Shoulder backward" 11 "Shoulder forward" 10 "Ottoman2 backward" 9 "Ottoman2 forward" 8 "Ottoman1 backward" 7 "Ottoman1 forward" 6 "Lift down" 5 "Lift up" 4 "Back backward" 3 "Back forward" 2 "Slide backward" 1 "Slide forward" 0 "No command" ;
VAL_ 1015 ACU_RRSeatOperationReqVD 1 "Valid" 0 "Not valid" ;
VAL_ 1015 ACU_RLSeatOperationReqVD 1 "Valid" 0 "Not valid" ;
VAL_ 1015 ACU_RLSeatOperationReq 15 "Not used" 14 "Not used" 13 "Not used" 12 "Shoulder backward" 11 "Shoulder forward" 10 "Ottoman2 backward" 9 "Ottoman2 forward" 8 "Ottoman1 backward" 7 "Ottoman1 forward" 6 "Lift down" 5 "Lift up" 4 "Back backward" 3 "Back forward" 2 "Slide backward" 1 "Slide forward" 0 "No command" ;
VAL_ 1015 ACU_HVSMR_RRSeatHeatVentModeSt 3 " No Command" 2 "Heat mode" 1 "Vent mode" 0 "OFF" ;
VAL_ 1015 ACU_HVSMR_RRSeatVentLevelReq 7 " Not used" 6 "Not used" 5 "Not used" 4 "No Command" 3 "Level 3" 2 "Level 2" 1 "Level 1" 0 " OFF" ;
VAL_ 1015 ACU_HVSMR_RRSeatHeatLevelReq 7 " Not used" 6 "Not used" 5 "Not used" 4 "No Command" 3 "Level 3" 2 "Level 2" 1 "Level 1" 0 " OFF" ;
VAL_ 1015 ACU_HVSMR_RLSeatHeatVentModeSt 3 " No Command" 2 "Heat mode" 1 "Vent mode" 0 "OFF" ;
VAL_ 1015 ACU_HVSMR_RLSeatVentLevelReq 7 " Not used" 6 "Not used" 5 "Not used" 4 "No Command" 3 "Level 3" 2 "Level 2" 1 "Level 1" 0 " OFF" ;
VAL_ 1015 ACU_HVSMR_RLSeatHeatLevelReq 7 " Not used" 6 "Not used" 5 "Not used" 4 "No Command" 3 "Level 3" 2 "Level 2" 1 "Level 1" 0 " OFF" ;
VAL_ 1015 ACU_ORVMOperationReqVD 1 "Valid" 0 "Not valid" ;
VAL_ 1015 ACU_SeatSteeringWheelOpratReqVD 1 "Valid" 0 "Not valid" ;
VAL_ 1015 ACU_SVM_Button 1 "Request" 0 "No request" ;
VAL_ 1015 ACU_APA_Button 1 "Press" 0 "No Press" ;
VAL_ 1015 ACU_ORVMOperationReq 15 "not used" 14 "not used" 13 "not used" 12 "not used" 11 "not used" 10 "Unfold" 9 "Fold" 8 "FR mirror right" 7 "FR mirror left" 6 "FR mirror down" 5 "FR mirror up" 4 "FL mirror right" 3 "FL mirror left" 2 "FL mirror down" 1 "FL mirror up" 0 "No command" ;
VAL_ 1015 ACU_SeatSteeringWheelOpratReq 15 "Not used" 14 "Cushion backward" 13 "Cushion forward" 12 "Steeringwheel in" 11 "Steeringwheel out" 10 "Steeringwheel down" 9 "Steeringwheel up" 8 "Tilt down" 7 "Tilt rise" 6 "Backrest backward" 5 "Backrest forward" 4 "Cushion down" 3 "Cushion rise" 2 "Slide backward" 1 "Slide forward" 0 "No command" ;
VAL_ 1015 ACU_HVSM_FRSeatHeatVentModeSt 3 " No Command" 2 "Heat mode" 1 "Vent mode" 0 "OFF" ;
VAL_ 1015 ACU_HVSM_FRSeatVentLevelReq 7 " Not used" 6 "Not used" 5 "Not used" 4 "No Command" 3 "Level 3" 2 "Level 2" 1 "Level 1" 0 " OFF" ;
VAL_ 1015 ACU_HVSM_FRSeatHeatLevelReq 7 " Not used" 6 "Not used" 5 "Not used" 4 "No Command" 3 "Level 3" 2 "Level 2" 1 "Level 1" 0 " OFF" ;
VAL_ 1015 ACU_HVSM_FLSeatHeatVentModeSt 3 " No Command" 2 "Heat mode" 1 "Vent mode" 0 "OFF" ;
VAL_ 1015 ACU_HVSM_FLSeatVentLevelReq 7 " Not used" 6 "Not used" 5 "Not used" 4 "No Command" 3 "Level 3" 2 "Level 2" 1 "Level 1" 0 " OFF" ;
VAL_ 1015 ACU_HVSM_FLSeatHeatLevelReq 7 " Not used" 6 "Not used" 5 "Not used" 4 "No Command" 3 "Level 3" 2 "Level 2" 1 "Level 1" 0 " OFF" ;
VAL_ 98 ACU_MSM_RRSeatWelcomeFuncCfg 3 "Not used" 2 "Active" 1 "Not active" 0 "No command" ;
VAL_ 98 ACU_MSM_RLSeatWelcomeFuncCfg 3 "Not used" 2 "Active" 1 "Not active" 0 "No command" ;
VAL_ 98 ACU_HVSPR_RRFreezeFuncCfg 3 " not used" 2 "OFF " 1 "ON" 0 "no command" ;
VAL_ 98 ACU_HVSPR_RLFreezeFuncCfg 3 " not used" 2 "OFF " 1 "ON" 0 "no command" ;
VAL_ 98 ACU_MCM_RRMasIntensityReq 7 "No Command" 6 "Not Used" 5 "Not Used" 4 "Not Used" 3 "Level 3" 2 "Level 2" 1 "Level 1" 0 "OFF" ;
VAL_ 98 ACU_MCM_RRMasModeReq 7 "No Command" 6 "Mode6" 5 "Mode5" 4 "Mode4" 3 "Mode3" 2 "Mode2" 1 "Mode1" 0 "OFF" ;
VAL_ 98 ACU_MCM_RRMasStReq 3 "Not Used" 2 "ON" 1 "OFF" 0 "No Command" ;
VAL_ 98 ACU_MCM_RLMasIntensityReq 7 "No Command" 6 "Not Used" 5 "Not Used" 4 "Not Used" 3 "Level 3" 2 "Level 2" 1 "Level 1" 0 "OFF" ;
VAL_ 98 ACU_MCM_RLMasModeReq 7 "No Command" 6 "Mode6" 5 "Mode5" 4 "Mode4" 3 "Mode3" 2 "Mode2" 1 "Mode1" 0 "OFF" ;
VAL_ 98 ACU_MCM_RLMasStReq 3 "Not Used" 2 "ON" 1 "OFF" 0 "No Command" ;
VAL_ 82 ACU_HVSM_VR_RRVentilatLvlReq 7 "Not used" 6 "Not used" 5 "Not used" 4 "No command" 3 "Level 3" 2 "Level 2" 1 "Level 1" 0 "Off" ;
VAL_ 82 ACU_HVSM_VR_RRHeatingLevelReq 7 "Not used" 6 "Not used" 5 "Not used" 4 "No command" 3 "Level 3" 2 "Level 2" 1 "Level 1" 0 "Off" ;
VAL_ 82 ACU_HVSM_VR_RLVentilatLvlReq 7 "Not used" 6 "Not used" 5 "Not used" 4 "No command" 3 "Level 3" 2 "Level 2" 1 "Level 1" 0 "Off" ;
VAL_ 82 ACU_HVSM_VR_RLHeatingLevelReq 7 "Not used" 6 "Not used" 5 "Not used" 4 "No command" 3 "Level 3" 2 "Level 2" 1 "Level 1" 0 "Off" ;
VAL_ 82 ACU_HVSM_VR_FRVentilatLvlReq 7 "Not used" 6 "Not used" 5 "Not used" 4 "No command" 3 "Level 3" 2 "Level 2" 1 "Level 1" 0 "Off" ;
VAL_ 82 ACU_HVSM_VR_FRHeatingLevelReq 7 "Not used" 6 "Not used" 5 "Not used" 4 "No command" 3 "Level 3" 2 "Level 2" 1 "Level 1" 0 "Off" ;
VAL_ 82 ACU_HVSM_VR_FLVentilatLvlReq 7 "Not used" 6 "Not used" 5 "Not used" 4 "No command" 3 "Level 3" 2 "Level 2" 1 "Level 1" 0 "Off" ;
VAL_ 82 ACU_HVSM_VR_FLHeatingLevelReq 7 "Not used" 6 "Not used" 5 "Not used" 4 "No command" 3 "Level 3" 2 "Level 2" 1 "Level 1" 0 "Off" ;
VAL_ 836 PCS_MMIAPAFuncSelect 3 " POC Button Press" 2 " cPSC Button Press(FAPA: reserved)" 1 " pPSC Button Press(FAPA: PSC)" 0 " No Button Press" ;
VAL_ 836 PCS_MMIAPAConfirmButton 3 " Reserved" 2 " Reserved" 1 " Terminated Button Press   " 0 " No Button Press   " ;
VAL_ 836 PCS_PASButtonPress 1 "Press" 0 "Not press" ;
VAL_ 836 PCS_ER_QuitReq 1 "Active" 0 "Not active" ;
VAL_ 836 PCS_ER_EnterConfirm 1 "Active" 0 "Not active" ;
VAL_ 836 PCS_ACU_DisplayReq 1 "Request" 0 "Not request" ;
VAL_ 836 PCS_SoundReminderSt 1 "On" 0 "Off" ;
VAL_ 836 PCS_BCM_ButtonLamp 1 "On" 0 "Off" ;
VAL_ 836 PCS_ReturnSt 1 "On" 0 "Off" ;
VAL_ 836 PCS_RightBlindSpotViewSt 1 "On" 0 "Off" ;
VAL_ 836 PCS_LeftBlindSpotViewSt 1 "On" 0 "Off" ;
VAL_ 836 PCS_RVMButtonGroup 7 "Not used" 6 "Not used" 5 "Not used" 4 "Button group 4(return to the first step of parallel parking and normal parking)" 3 "Button group 3(angle parking and normal parking)" 2 "Button group 2(parallel parking and normal parking)" 1 "Button group 1(parallel parking and angle parking)" 0 "No button" ;
VAL_ 836 PCS_APASlotActiveSt 7 "Reserved" 6 "Reserved" 5 "Reserved" 4 "Right cPSC is active" 3 "Right pPSC is active" 2 "Left cPSC is active" 1 "Left pPSC is active" 0 "Not Actived" ;
VAL_ 836 PCS_APATurnLampReq 3 "Reserved" 2 "Right Turn Lamp" 1 "Left Turn Lamp" 0 "Off" ;
VAL_ 836 PCS_APA_BackParkButton 1 " Press" 0 " No press" ;
VAL_ 836 PCS_OperationSt 3 "Not used" 2 "Normal" 1 "Standby" 0 "Sleep" ;
VAL_ 836 PCS_3DEnalbe 1 "Enalbe" 0 "Disable" ;
VAL_ 836 PCS_MODEnalbe 1 "Enalbe" 0 "Disable" ;
VAL_ 836 PCS_PGSEnable 1 "Enalbe" 0 "Disable" ;
VAL_ 836 PCS_SteerIconInd 7 "Not used" 6 "Not used" 5 "Not used" 4 "Right,on target position" 3 "Right,not on target position" 2 "Left,on target position" 1 "Left,not on target position" 0 "Center" ;
VAL_ 836 PCS_SteerWheelTurnDirInd 3 "Not used" 2 "Turn right" 1 "Turn left" 0 "No command" ;
VAL_ 836 PCS_GuidOverlaySt 3 "Both around view and single view guidance overlay display" 2 "Only single view guidance overlay display" 1 "Only around view guidance overlay display" 0 "No guidance overlay display" ;
VAL_ 836 PCS_DriveDirInd 3 "Not used" 2 "Reverse indication" 1 "Drive indication" 0 "No indication" ;
VAL_ 836 PCS_VoiceReq 15 "Voice request NO.15(RVM)" 14 "Voice request NO.14(RVM)" 13 "Voice request NO.13(RVM)" 12 "Voice request NO.12(RVM)" 11 "Voice request NO.11（RVM||SVM）" 10 "Voice request NO.10(SVM)" 9 "Voice request NO.9(SVM)" 8 "Voice request NO.8(SVM)" 7 "Voice request NO.7(SVM)" 6 "Voice request NO.6(SVM)" 5 "Voice request NO.5(SVM)" 4 "Voice request NO.4(SVM)" 3 "Voice request NO.3(SVM)" 2 "Voice request NO.2(SVM)" 1 "Voice request NO.1(SVM)" 0 "No voice request" ;
VAL_ 836 PCS_SingleViewInd 15 "Not used" 14 "Not used" 13 "Not used" 12 "Not used" 11 "Not used" 10 "Not used" 9 "Overlook view" 8 "Right view" 7 "Left view" 6 "Rear of right view" 5 "Rear of left view" 4 "Front of right view" 3 "Front of left view" 2 "Rear view" 1 "Front view" 0 "No function" ;
VAL_ 836 PCS_HMIIndex 15 "Request to cancel" 14 "Not used" 13 "Not used" 12 "Vertical parking view(RVM)" 11 "Parallel parking view(RVM)" 10 "Rear view(RVM)" 9 "Vertical parking view(SVM)" 8 "Parallel parking view(SVM)" 7 "Parking guidance view(SVM)" 6 "Right blind spot view(SVM)" 5 "Left blind spot view (SVM)" 4 "Enlarge rear view(SVM)" 3 "Surround view and Rear view(SVM)" 2 "Enlarge front view(SVM)" 1 "Surround view and Front view(SVM)" 0 "No function" ;
VAL_ 836 PCS_EventRecordSt 1 "On" 0 "Off" ;
VAL_ 836 PCS_CalibrateSt 7 "Not used" 6 "Not used" 5 "Not used" 4 " Partially calibrated (FAPA)" 3 "Calibrate failure" 2 "Claibrate success" 1 "Claibrating " 0 "Not calibrate" ;
VAL_ 836 PCS_SystemType 3 "Not used" 2 "SVM(Surround View Module)" 1 "RVM(Rear View Module)" 0 "Unknown" ;
VAL_ 836 PCS_OverlayOpFail 1 "Fail" 0 "No Fail" ;
VAL_ 836 PCS_PGSOpFail 1 "Fail" 0 "No Fail" ;
VAL_ 836 PCS_FrontRightCameraFail 1 "Fail" 0 "No Fail" ;
VAL_ 836 PCS_FrontLeftCameraFail 1 "Fail" 0 "No Fail" ;
VAL_ 836 PCS_RearCameraFail 1 "Fail" 0 "No Fail" ;
VAL_ 836 PCS_RightCameraFail 1 "Fail" 0 "No Fail" ;
VAL_ 836 PCS_LeftCameraFail 1 "Fail" 0 "No Fail" ;
VAL_ 836 PCS_FrontCameraFail 1 "Fail" 0 "No Fail" ;
VAL_ 836 PCS_SystemSt 1 "System not OK" 0 "System OK" ;
VAL_ 1014 ACU_HVAC_RearWindSpdSet 15 " Not used" 14 " Not used" 13 " Not used" 12 " Not used" 11 " Not used" 10 " Not used" 9 " Not used" 8 " Not used" 7 " Level 7(Max)" 6 " Level 6" 5 " Level 5" 4 "Level 4" 3 "Level 3" 2 "Level 2" 1 "Level 1(Min)" 0 "No command   " ;
VAL_ 1014 ACU_HVAC_RearAutoModeBtnSt 1 "press" 0 "release" ;
VAL_ 1014 ACU_HVAC_RearOnOffBtnSt 1 "press" 0 "release" ;
VAL_ 1014 ACU_HVACFR_RrTempSettingVD 1 "Valid" 0 "Not valid" ;
VAL_ 1014 ACU_HVAC_RearMODESetting 7 "Not used" 6 "Not used" 5 "Not used" 4 "Not used" 3 "Foot" 2 "Face/Foot" 1 "Face" 0 "No command   " ;
VAL_ 1014 ACU_HVACFR_ModeSetting 7 "Not used" 6 "Not used" 5 "Not used" 4 "Foot/Defrost" 3 "Foot" 2 "Face/Foot" 1 "Face" 0 "No action" ;
VAL_ 1014 ACU_HVACFR_WindSpeedSetting 15 "Not used" 14 "Not used" 13 "Not used" 12 "Not used" 11 "Not used" 10 "Not used" 9 "Not used" 8 "Not used" 7 "Level 7(Max)" 6 "Level 6" 5 "Level 5" 4 "Level 4(Mid)" 3 "Level 3   " 2 "Level 2   " 1 "Level 1(Min)   " 0 "No command   " ;
VAL_ 1014 ACU_HVACFR_WindSpeedSettingVD 1 "Valid" 0 "Not valid" ;
VAL_ 1014 ACU_HVACFR_PsnTempSettingVD 1 "Valid" 0 "Not valid" ;
VAL_ 1014 ACU_HVACFR_DrTempSettingVD 1 "Valid" 0 "Not valid" ;
VAL_ 150 ACU_PSD_VR_PSDRControlVD 1 "Valid" 0 "Not valid" ;
VAL_ 150 ACU_PSD_VR_PSDRControl 7 "not used" 6 "not used" 5 "not used" 4 "not used" 3 "close" 2 "open" 1 "stop" 0 "no command" ;
VAL_ 150 ACU_PSD_VR_PSDLControlVD 1 "Valid" 0 "Not valid" ;
VAL_ 150 ACU_PSD_VR_PSDLControl 7 "not used" 6 "not used" 5 "not used" 4 "not used" 3 "close" 2 "open" 1 "stop" 0 "no command" ;
VAL_ 150 ACU_SCMRR_StoragemodeFuncCfg 3 "Not used" 2 "Active" 1 "Not active" 0 "No command" ;
VAL_ 150 ACU_SCMRL_StoragemodeFuncCfg 3 "Not used" 2 "Active" 1 "Not active" 0 "No command" ;
VAL_ 150 ACU_Freezepermissions_FuncCfg 3 "Not used" 2 "Active" 1 "Not active" 0 "No command" ;
VAL_ 150 ACU_SCMRL_Freezepermissions_Func 3 "Not used" 2 "Active" 1 "Not active" 0 "No command" ;
VAL_ 150 ACU_SCMRR_WelcomeFuncCfg 3 "Not used" 2 "Active" 1 "Not active" 0 "No command" ;
VAL_ 150 ACU_SCMRL_WelcomeFuncCfg 3 "Not used" 2 "Active" 1 "Not active" 0 "No command" ;
VAL_ 150 ACU_HVACF_FraganceConcentrationS 1 "Valid" 0 "Not valid" ;
VAL_ 150 ACU_HVACF_FraganceTasteStVD 1 "Valid" 0 "Not valid" ;
VAL_ 150 ACU_HVACF_FraganceTasteSt 3 "Taste 3" 2 "Taste 2" 1 "Taste 1" 0 "No Action" ;
VAL_ 150 ACU_HVACF_FraganceConcentra_0000 7 "Reserved" 6 "Reserved" 5 "On" 4 "High" 3 "Mid" 2 "Low" 1 "Off" 0 "No Action" ;
VAL_ 46 ACU_OperatingModeCfg 7 "Not used" 6 "Not used" 5 "Not used" 4 "Not used" 3 "fuel first" 2 "electicity first" 1 "Intelligent hybrid mode" 0 "Normal mode" ;
VAL_ 46 ACU_ChgEndReq 1 "end charge" 0 "No Command" ;
VAL_ 46 ACU_PlugAutoUnlockCfg 2 "not auto unlock" 1 "auto unlock" 0 "no command" ;
VAL_ 46 ACU_DischgEngStartCfg 2 " Engine start disable" 1 "Engine start enable" 0 " No request" ;
VAL_ 46 ACU_DischgActiveReq 2 "Discharge inactive request" 1 "Discharge active request" 0 " No request" ;
VAL_ 161 ACU_DrvModCfg 0 " Invalid" 1 " ECO+ Mode" 2 " ECO Mode" 3 " Comfort Mode" 4 " Driving Mode" 5 " Sport Mode" 6 " I-peadl ON" 7 " I-peadl OFF" ;
VAL_ 161 ACU_RecpLevelCfg 0 " No command；" 1 " Level 1;" 2 " Level 2;" 3 " Level 3;" 4 " Level 4;" ;
VAL_ 141 ACU_HVACF_SmartSet 3 "not used" 2 "on" 1 "off" 0 "No command" ;
VAL_ 141 ACU_ESACfg 3 "Not used" 2 "Active" 1 "Not active" 0 "No command" ;
VAL_ 141 ACU_HWAWDSwitchReq 3 "Not used" 2 "On" 1 "Off" 0 "No command" ;
VAL_ 141 ACU_FVDSwitchReq 3 "Not used" 2 "On" 1 "Off" 0 "No command" ;
VAL_ 141 ACU_TCH_VR_CuphdrHeatColAutMdSt 3 "Not used" 2 " No Command" 1 "Auto mode ON" 0 "Auto mode OFF" ;
VAL_ 141 ACU_TCH_VR_CupholderHeatCoolMdSt 3 "No Command" 2 "Cool mode" 1 "Heat mode" 0 "OFF" ;
VAL_ 141 ACU_TCH_CupholdrHeatCoolAutoMdSt 3 "Not used" 2 " No Command" 1 "Auto mode ON" 0 "Auto mode OFF" ;
VAL_ 141 ACU_TCH_CupholderHeatCoolModeSt 3 "No Command" 2 "Cool mode" 1 "Heat mode" 0 "OFF" ;
VAL_ 141 ACU_TCH_VR_CupholdrHeatCoolMdVD 1 "Valid" 0 "Not valid" ;
VAL_ 141 ACU_TCH_CupholderHeatCoolModeVD 1 "Valid" 0 "Not valid" ;
VAL_ 141 ACU_PSD_ModeSt 3 "not used" 2 "power slide door" 1 "manual slide door" 0 "no command" ;
VAL_ 141 ACU_PSDR_SpdSet 3 "not used" 2 "high speed" 1 "slow speed" 0 "no command" ;
VAL_ 141 ACU_PSDL_SpdSet 3 "not used" 2 "high speed" 1 "slow speed" 0 "no command" ;
VAL_ 141 ACU_HVACF_EvapratorSelfCleanCfg 3 "Reserved" 2 "ON" 1 "OFF" 0 "No command" ;
VAL_ 141 ACU_HVACFUnlockVentilationCfg 3 "Reserved" 2 "ON" 1 "OFF" 0 "No command" ;
VAL_ 141 ACU_CancelMaintenanceCfg 3 "Reserved" 2 "On" 1 "off" 0 "No commend" ;
VAL_ 141 ACU_MaintenanceResetCfg 3 "Reserved" 2 "No" 1 "Yes" 0 "No commend" ;
VAL_ 141 ACU_MaintenanceCycleCfg 7 "Reserved" 6 "Reserved" 5 "Reserved" 4 "Reserved" 3 "10000km" 2 "7500km" 1 "5000km" 0 "No commend" ;
VAL_ 75 ACU_BCM_RearWiperSerPstFuncCfg 3 "Not Used" 2 "OFF" 1 "ON" 0 "No command" ;
VAL_ 75 ACU_VR_APA_Switch 1 "On" 0 "Off" ;
VAL_ 75 ACU_VR_SVM_Switch 1 "On" 0 "Off" ;
VAL_ 75 ACU_MCM_VR_RRMasIntensityReq 7 "Not Used" 6 "Not Used" 5 "Not Used" 4 "No Command" 3 "Level 3" 2 "Level 2" 1 "Level 1" 0 "OFF" ;
VAL_ 75 ACU_MCM_VR_RRMasModeReq 7 "No Command" 6 "Mode6" 5 "Mode5" 4 "Mode4" 3 "Mode3" 2 "Mode2" 1 "Mode1" 0 "OFF" ;
VAL_ 75 ACU_MCM_VR_RRMasStReq 3 "Not Used" 2 "No Command" 1 "ON" 0 "OFF" ;
VAL_ 75 ACU_MCM_VR_RLMasIntensityReq 7 "Not Used" 6 "Not Used" 5 "Not Used" 4 "No Command" 3 "Level 3" 2 "Level 2" 1 "Level 1" 0 "OFF" ;
VAL_ 75 ACU_MCM_VR_RLMassagemode 7 "No Command" 6 "Mode6" 5 "Mode5" 4 "Mode4" 3 "Mode3" 2 "Mode2" 1 "Mode1" 0 "OFF" ;
VAL_ 75 ACU_MCM_VR_RLMasStReq 3 "Not Used" 2 "No Command" 1 "ON" 0 "OFF" ;
VAL_ 75 ACU_ShortcutMode 15 " Reserved" 14 " Reserved" 13 " Reserved" 12 " Reserved" 11 " Reserved" 10 " Reserved" 9 " Reserved" 8 "Both SPA mode" 7 "RH SPA mode" 6 "LH SPA mode" 5 "Party mode" 4 "Wake up mode" 3 "Nap mode" 2 "Rainstorm mode" 1 "Quit" 0 "No command" ;
VAL_ 75 ACU_SCMNapSettingSave 3 "Start" 2 "Save" 1 "Cancel" 0 "No Command" ;
VAL_ 75 ACU_MSM_VR_FLSeatVoiceCtrlVD 1 "Valid" 0 "Not valid" ;
VAL_ 75 ACU_MSM_VR_FLSeatVoiceCtrl 15 "not used" 14 "not used" 13 "not used" 12 "Stop" 11 "Title down" 10 "Title rise" 9 "back backward" 8 "back forward" 7 "Cushion down" 6 "Cushion rise" 5 "Slide backward" 4 "Slide forward" 3 "Level 3" 2 "Level 2" 1 "Level 1" 0 "No Request" ;
VAL_ 66 ACU_PEPS_VR_EngPowerOffReqVD 1 "valid" 0 "not valid" ;
VAL_ 66 ACU_PEPS_VR_EngPowerOffReq 1 "Turn off" 0 "no command" ;
VAL_ 66 ACU_PEPS_VR_EngStartReqVD 1 "valid" 0 "not valid" ;
VAL_ 66 ACU_PEPS_VR_EngStartReq 1 "start" 0 "no command" ;
VAL_ 47 ACU_HVACF_VR_SYNCONOFF 3 "Not used" 2 "On" 1 "Off" 0 "No command" ;
VAL_ 47 ACU_HVACF_VR_FRAGONOFF 3 "Not used" 2 "On" 1 "Off" 0 "No command" ;
VAL_ 47 ACU_HVACF_VR_ACONOFF 3 "Not used" 2 "On" 1 "Off" 0 "No command" ;
VAL_ 47 ACU_HVACF_VR_RrAutoModeONOFF 3 "Not used" 2 "On" 1 "Off" 0 "No command" ;
VAL_ 47 ACU_HVACF_VR_RrTempChange 63 "Reserved" 62 "Reserved" 61 "Reserved" 60 "Reserved" 59 "Reserved" 58 "Reserved" 57 "Reserved" ;
VAL_ 47 ACU_HVACF_VR_RrWindModeSetting 7 "Not used" 6 "Not used" 5 "Not used" 4 "Not used" 3 "Foot" 2 "Face/foot" 1 "Face" 0 "No command" ;
VAL_ 47 ACU_HVACF_VR_RrTempSetting 31 "Invalid" 30 "Reserved" 29 "Reserved" ;
VAL_ 47 ACU_HVACF_VR_RrWindSpeedSetting 15 "Not used" 14 "Not used" 13 "Not used" 12 "Not used" 11 "Not used" 10 "Not used" 9 "Not used" 8 "Not used" 7 "Level 7" 6 "Level 6" 5 "Level 5" 4 "Level 4" 3 "Level 3" 2 "Level 2" 1 "Level 1(Min)" 0 "No command" ;
VAL_ 47 ACU_HVACF_VR_RDefrostONOFF 3 "Not used" 2 "On" 1 "Off" 0 "No command" ;
VAL_ 47 ACU_HVACF_VR_RrHVACONOFF 3 "Not used" 2 "On" 1 "Off" 0 "No command" ;
VAL_ 806 ACU_Avdcset 5 " AVDC off" 4 " AVDC adaptive model" 3 " AVDC on low adhesion road " 2 " AVDC radical model" 1 "AVDC modest model" 0 " invalid" ;
VAL_ 806 ACU_Gaspedallvl 5 " Level 5" 4 " Level 4" 3 " Level 3" 2 " Level 2" 1 " Level 1" 0 " invalid" ;
VAL_ 806 ACU_AUID 15 " Not used" 14 " Not used" 13 " Not used" 12 " Not used" 11 " Not used" 10 " Not used" 9 " Not used" 8 " account 8" 7 " account 7" 6 " account 6" 5 " account 5" 4 " account 4" 3 " account 3" 2 " account 2" 1 " account 1" 0 "default" ;
VAL_ 806 ACU_MSM_SaveRecalComd 3 "Not used" 2 "Recall" 1 "Save" 0 "No Command" ;
VAL_ 806 ACU_SCMNapSetting 1 "Active" 0 "Not active" ;
VAL_ 603 ACU_BCM_VR_RightLaneChangeReqVD 1 "Valid" 0 "Not valid" ;
VAL_ 603 ACU_BCM_VR_LeftLaneChangeReqVD 1 "Valid" 0 "Not valid" ;
VAL_ 603 ACU_BCM_VR_RightTurnLampReqVD 1 "Valid" 0 "Not valid" ;
VAL_ 603 ACU_BCM_VR_LeftTurnLampReqVD 1 "Valid" 0 "Not valid" ;
VAL_ 603 ACU_BCM_VR_RightLaneChangeReq 3 "not used" 2 "Active" 1 "Not active" 0 "No command" ;
VAL_ 603 ACU_BCM_VR_LeftLaneChangeReq 3 "not used" 2 "Active" 1 "Not active" 0 "No command" ;
VAL_ 603 ACU_BCM_VR_TankcoverReqVD 1 "Valid" 0 "Not valid" ;
VAL_ 603 ACU_BCM_VR_RearWasherReqVD 1 "Valid" 0 "Not valid" ;
VAL_ 603 ACU_BCM_VR_FrontWasherReqVD 1 "Valid" 0 "Not valid" ;
VAL_ 603 ACU_BCM_VR_RearWiperReqVD 1 "Valid" 0 "Not valid" ;
VAL_ 603 ACU_BCM_VR_TankcoverReq 3 "not used" 2 "On" 1 "Off" 0 "No command" ;
VAL_ 603 ACU_BCM_VR_RearWasherReq 3 "not used" 2 "On" 1 "Off" 0 "No command" ;
VAL_ 603 ACU_BCM_VR_FrontWasherReq 3 "not used" 2 "On" 1 "Off" 0 "No command" ;
VAL_ 603 ACU_BCM_VR_RearWiperReq 3 "not used" 2 "On" 1 "Off" 0 "No command" ;
VAL_ 603 ACU_BCM_VR_FrontWiperReq 3 "Continuous fast" 2 "Continuous slow" 1 "Off" 0 "No command" ;
VAL_ 603 ACU_BCM_VR_RoomLampReq 3 "not used" 2 "On" 1 "Off" 0 "No command" ;
VAL_ 603 ACU_BCM_VR_FrontWiperReqVD 1 "Valid" 0 "Not valid" ;
VAL_ 603 ACU_BCM_VR_RoomLampReqVD 1 "Valid" 0 "Not valid" ;
VAL_ 603 ACU_BCM_VR_RearFogLampReqVD 1 "Valid" 0 "Not valid" ;
VAL_ 603 ACU_BCM_VR_FrontFogLampReqVD 1 "Valid" 0 "Not valid" ;
VAL_ 603 ACU_BCM_VR_HighBeamReqVD 1 "Valid" 0 "Not valid" ;
VAL_ 603 ACU_BCM_VR_LowBeamReqVD 1 "Valid" 0 "Not valid" ;
VAL_ 603 ACU_BCM_VR_ParkingLampReqVD 1 "Valid" 0 "Not valid" ;
VAL_ 603 ACU_BCM_VR_AmbientLightReqReqVD 1 "Valid" 0 "Not valid" ;
VAL_ 603 ACU_BCM_VR_RearFogLampReq 3 "not used" 2 "On" 1 "Off" 0 "No command" ;
VAL_ 603 ACU_BCM_VR_FrontFogLampReq 3 "not used" 2 "On" 1 "Off" 0 "No command" ;
VAL_ 603 ACU_BCM_VR_HighBeamReq 3 "not used" 2 "On" 1 "Off" 0 "No command" ;
VAL_ 603 ACU_BCM_VR_LowBeamReq 3 "not used" 2 "On" 1 "Off" 0 "No command" ;
VAL_ 603 ACU_BCM_VR_RightTurnLampReq 3 "not used" 2 "Active" 1 "Not active" 0 "No command" ;
VAL_ 603 ACU_BCM_VR_LeftTurnLampReq 3 "not used" 2 "Active" 1 "Not active" 0 "No command" ;
VAL_ 603 ACU_BCM_VR_ParkingLampReq 3 "not used" 2 "On" 1 "Off" 0 "No command" ;
VAL_ 603 ACU_BCM_VR_AmbientLightReqReq 3 "not used" 2 "On" 1 "Off" 0 "No command" ;
VAL_ 50 ACU_ICM_VR_BackLightChange 15 "No command" ;
VAL_ 50 ACU_ICM_VR_BackLightSetting 63 "Not used" 62 "Not used" 61 "Not used" 60 "Not used" 59 "Not used" 58 "Not used" 57 "Not used" 56 "Not used" 55 "Not used" 54 "Not used" 53 "Not used" 52 "Not used" 51 "Not used" 50 "Not used" 49 "Not used" 48 "Not used" 47 "Not used" 46 "Not used" 45 "Not used" 44 "Not used" 43 "Not used" 42 "Not used" 41 "Not used" 40 "Not used" 39 "Not used" 38 "Not used" 37 "Not used" 36 "Not used" 35 "Not used" 34 "Not used" 33 "Not used" 32 "Not used" 31 "Not used" 30 "Not used" 29 "Not used" 28 "Not used" 27 "Not used" 26 "Not used" 25 "Not used" 24 "Not used" 23 "Not used" 22 "Not used" 21 "Not used" 20 "Not used" 19 "Not used" 18 "Not used" 17 "Not used" 16 "Not used" 15 "Not used" 14 "Not used" 13 "Not used" 12 "Not used" 11 "Not used" 10 "Not used" 9 "Not used" 8 "Level 8" 7 "Level 7" 6 "Level 6" 5 "Level 5" 4 "Level 4" 3 "Level 3" 2 "Level 2" 1 "Level 1" 0 "No command" ;
VAL_ 50 ACU_HVACF_VR_PsnTempChange 63 "Reserved" 62 "Reserved" 61 "Reserved" 60 "Reserved" 59 "Reserved" 58 "Reserved" 57 "Reserved" ;
VAL_ 50 ACU_HVACF_VR_PsnTempSetting 31 "Invalid" 30 "Reserved" 29 "Reserved" ;
VAL_ 50 ACU_HVACF_VR_AutoModeOnOff 3 "Not used" 2 "On" 1 "Off" 0 "No command" ;
VAL_ 50 ACU_HAVACF_VR_IonOnOff 3 "Not used" 2 "On" 1 "Off" 0 "No command" ;
VAL_ 50 ACU_HVACF_VR_AirCirculationSt 3 "AUTO Inner air circulation" 2 "Outside air circulation" 1 "Inner air circulation" 0 "No command" ;
VAL_ 50 ACU_HVACF_VR_TempChange 63 "Reserved" 62 "Reserved" 61 "Reserved" 60 "Reserved" 59 "Reserved" 58 "Reserved" 57 "Reserved" ;
VAL_ 50 ACU_HVACF_VR_WindModeSetting 7 "Not used" 6 "Not used" 5 "Defrost" 4 "Foot/defrost" 3 "Foot" 2 "Face/foot" 1 "Face" 0 "No command" ;
VAL_ 50 ACU_HVACF_VR_TempSetting 31 "Invalid" 30 "Reserved" 29 "Reserved" ;
VAL_ 50 ACU_HVACF_VR_WindSpeedSetting 15 "Not used" 14 "Not used" 13 "Not used" 12 "Not used" 11 "Not used" 10 "Not used" 9 "Not used" 8 "Not used" 7 "Level 7(Max)" 6 "Level 6" 5 "Level 5" 4 "Level 4(Mid)" 3 "Level 3" 2 "Level 2" 1 "Level 1(Min)" 0 "No command" ;
VAL_ 50 ACU_HVACF_VR_FDefrostONOFF 3 "Not used" 2 "On" 1 "Off" 0 "No command" ;
VAL_ 50 ACU_HVACF_VR_HVACONOFF 3 "Not used" 2 "On" 1 "Off" 0 "No command" ;
VAL_ 55 ACU_HeadlightDelayCfgSt 3 "Not used" 2 "Active" 1 "Not active" 0 "No command" ;
VAL_ 55 ACU_IAL_ColorModeCfg 15 "Reserved" 14 "Reserved" 13 "Reserved" 12 "Reserved" 11 "Reserved" 10 "Reserved" 9 "Reserved" 8 "Reserved" 7 "Reserved" 6 "Reserved" 5 "CombinedcolorMode 3" 4 "CombinedcolorMode 2" 3 "CombinedcolorMode 1" 2 "DriverMode" 1 "ColorChooseMode" 0 "No Command" ;
VAL_ 55 ACU_HVACFUnlockVentilationCfg 3 "Not used" 2 "ON" 1 "OFF" 0 "No command" ;
VAL_ 55 ACU_HVACF_EvapratorSelfCleanCfg 3 "Not used" 2 "ON" 1 "OFF" 0 "No command" ;
VAL_ 55 ACU_ETC_BLEenableCfg 3 "Not used" 2 "Active" 1 "Not Active" 0 "no command" ;
VAL_ 55 ACU_ETC_ICMDisplayCfg 3 "Not used" 2 "Active" 1 "Not Active" 0 "no command" ;
VAL_ 55 ACU_ETC_SysCfg 3 "Not used" 2 "Active" 1 "Not Active" 0 "no command" ;
VAL_ 55 ACU_IAL_HVACSeasonsKeyActive 1 " Key acive" 0 "No command" ;
VAL_ 55 ACU_IAL_ColourChooseCfg 3 "Not used" 2 "no active" 1 "active" 0 "No command" ;
VAL_ 55 ACU_MSM_OSRMAngleSave 3 "Cancel" 2 "Save" 1 "Start" 0 "No command" ;
VAL_ 55 ACU_MSM_OSRMAngleAdjFuncCfg 7 "Not used" 6 "Not used" 5 "Not used" 4 "Both mirror dip
" 3 "Right mirror dip
" 2 "Left mirror dip
" 1 "Off" 0 "No command" ;
VAL_ 55 ACU_IAL_MusicModeCfg 3 "Not used" 2 "no active" 1 "active" 0 "No command" ;
VAL_ 55 ACU_IAL_DriverModeCfg 3 "Not used" 2 "no active" 1 "active" 0 "No command" ;
VAL_ 55 ACU_HVACF_PM25CleanReqFb 3 "invalid" 2 "No Req " 1 "Req" 0 "No command  " ;
VAL_ 55 ACU_HVACF_PM25CleanReqCfg 3 "Set on auto" 2 "Set on manual" 1 "Set off" 0 "No command" ;
VAL_ 55 ACU_HVACF_FanspeedCfg 3 "High" 2 "Nornal" 1 "Low" 0 "No command" ;
VAL_ 55 ACU_IAL_FunctionCfg 3 "Not used" 2 "Off" 1 "On" 0 "No command" ;
VAL_ 978 ACU_HVACF_RearBtnStVD 1 "Valid" 0 "Not valid" ;
VAL_ 978 ACU_HVACF_RearBtnSt 1 "Press" 0 "Release" ;
VAL_ 978 ACU_HVACF_FrsAirBtnStVD 1 "Valid" 0 "Not valid" ;
VAL_ 978 ACU_HVACF_FrsAirBtnSt 1 "Press" 0 "Release" ;
VAL_ 978 ACU_HVACF_InnerCirBtnStVD 1 "Valid" 0 "Not valid" ;
VAL_ 978 ACU_HVACF_InnerCirBtnSt 1 "Press" 0 "Release" ;
VAL_ 978 ACU_HVACF_TripleZoneBtnStVD 1 "Valid" 0 "Not valid" ;
VAL_ 978 ACU_HVACF_TripleZoneBtnSt 1 "Press" 0 "Release" ;
VAL_ 978 ACU_HVACF_FRTempDecBtnStVD 1 "Valid" 0 "Not valid" ;
VAL_ 978 ACU_HVACF_FRTempDecBtnSt 1 "Press" 0 "Release" ;
VAL_ 978 ACU_HVACF_FRTempIncBtnStVD 1 "Valid" 0 "Not valid" ;
VAL_ 978 ACU_HVACF_FRTempIncBtnSt 1 "Press" 0 "Release" ;
VAL_ 978 ACU_HVACF_FLTempDecBtnStVD 1 "Valid" 0 "Not valid" ;
VAL_ 978 ACU_HVACF_FLTempDecBtnSt 1 "Press" 0 "Release" ;
VAL_ 978 ACU_HVACF_FLTempIncBtnStVD 1 "Valid" 0 "Not valid" ;
VAL_ 978 ACU_HVACF_FLTempIncBtnSt 1 "Press" 0 "Release" ;
VAL_ 978 ACU_HVACF_FraganceTasteSt 1 "Press" 0 "Release" ;
VAL_ 978 ACU_HVACF_FraganceConcentratSt 1 "Press" 0 "Release" ;
VAL_ 978 ACU_HVACR_TempDecBtnStVD 1 "Valid" 0 "Not valid" ;
VAL_ 978 ACU_HVACR_TempDecBtnSt 1 "Press" 0 "Release" ;
VAL_ 978 ACU_HVACR_TempIncBtnStVD 1 "Valid" 0 "Not valid" ;
VAL_ 978 ACU_HVACR_TempIncBtnSt 1 "Press" 0 "Release" ;
VAL_ 978 ACU_HVACF_ACMaxBtnStVD 1 "Valid" 0 "Not valid" ;
VAL_ 978 ACU_HVACF_ACMaxBtnSt 1 "Press" 0 "Release" ;
VAL_ 978 ACU_HVACF_ACBtnStVD 1 "Valid" 0 "Not valid" ;
VAL_ 978 ACU_HVACF_ACBtnSt 1 "Press" 0 "Release" ;
VAL_ 978 ACU_HVACF_CirBtnStVD 1 "Valid" 0 "Not valid" ;
VAL_ 978 ACU_HVACF_CirBtnSt 1 "Press" 0 "Release" ;
VAL_ 978 ACU_HVACFR_FanDecBtnStVD 1 "Valid" 0 "Not valid" ;
VAL_ 978 ACU_HVACFR_FanDecBtnSt 1 "Press" 0 "Release" ;
VAL_ 978 ACU_HVACFR_FanIncBtnStVD 1 "Valid" 0 "Not valid" ;
VAL_ 978 ACU_HVACFR_FanIncBtnSt 1 "Press" 0 "Release" ;
VAL_ 978 ACU_HVACF_IonBtnStVD 1 "Valid" 0 "Not valid" ;
VAL_ 978 ACU_HVACF_IonBtnSt 1 "Press" 0 "Release" ;
VAL_ 978 ACU_HVACF_DualBtnSyncStVD 1 "Valid" 0 "Not valid" ;
VAL_ 978 ACU_HVACF_DualSyncBtnSt 1 "Press" 0 "Release" ;
VAL_ 978 ACU_HVACF_RDefrostBtnStVD 1 "Valid" 0 "Not valid" ;
VAL_ 978 ACU_HVACF_RDefrostBtnSt 1 "Press" 0 "Release" ;
VAL_ 978 ACU_HVACF_FDefrostBtnStVD 1 "Valid" 0 "Not valid" ;
VAL_ 978 ACU_HVACF_FDefrostBtnSt 1 "Press" 0 "Release" ;
VAL_ 978 ACU_HVACFR_ModeBtnStVD 1 "Valid" 0 "Not valid" ;
VAL_ 978 ACU_HVACFR_ModeBtnSt 1 "Press" 0 "Release" ;
VAL_ 978 ACU_HVACFR_AutoModeBtnStVD 1 "Valid" 0 "Not valid" ;
VAL_ 978 ACU_HVACFR_AutoModeBtnSt 1 "Press" 0 "Release" ;
VAL_ 978 ACU_HVACFR_OffBtnStVD 1 "Valid" 0 "Not valid" ;
VAL_ 978 ACU_HVACFR_OffBtnSt 1 "Press" 0 "Release" ;
VAL_ 1009 ACU_RemoteDiagCode 3 "C DTC" 2 "B DTC" 1 "A DTC" 0 "No" ;
VAL_ 1009 ACU_VMM_RecordSt 3 "Not used" 2 "Record complete" 1 "Record start" 0 "No command" ;
VAL_ 1009 ACU_PCS_MirropagedownButtonST 1 "ON" 0 "OFF" ;
VAL_ 858 ACU_ThemeTypet 1 "Night mode" 0 "Day mode" ;
VAL_ 858 ACU_LanguageTypeSet 63 "Not used" 62 "Not used" 61 "Not used" 60 "Not used" 59 "Not used" 58 "Not used" 57 "Not used" 56 "Not used" 55 "Not used" 54 "Not used" 53 "Not used" 52 "Not used" 51 "Not used" 50 "Not used" 49 "Not used" 48 "Not used" 47 "Not used" 46 "Not used" 45 "Not used" 44 "Not used" 43 "Not used" 42 "Not used" 41 "Not used" 40 "Not used" 39 "Not used" 38 "Not used" 37 "Not used" 36 "Not used" 35 "Not used" 34 "Not used" 33 "Not used" 32 "Not used" 31 "Not used" 30 "Not used" 29 "Not used" 28 "Not used" 27 "Not used" 26 "Not used" 25 "Not used" 24 "Not used" 23 "Not used" 22 "Not used" 21 "Not used" 20 "Not used" 19 "Not used" 18 "Not used" 17 "Not used" 16 "Not used" 15 "Not used" 14 "Not used" 13 "Not used" 12 "Not used" 11 "Not used" 10 "Not used" 9 "Not used" 8 "Not used" 7 "Not used" 6 "Not used" 5 "Not used" 4 "Arabic" 3 "Russian" 2 "English" 1 "Chinese" 0 "Not used" ;
VAL_ 129 ACU_LightShowFunCmd 3 "Reserved" 2 "End" 1 "Start" 0 "No command" ;
VAL_ 129 ACU_LightShowModeSel 15 "Reserved" 14 "Reserved" 13 "Reserved" 12 "Reserved" 11 "Reserved" 10 "Reserved" 9 "Reserved" 8 "Reserved" 7 "Reserved" 6 "Reserved" 5 "Reserved" 4 "Reserved" 3 "modle3" 2 "model2" 1 "modle1" 0 "No command" ;
VAL_ 129 ACU_GSM_DrvmodeMemCfg 3 "Not used" 2 " Memory" 1 "Not memory" 0 "No command" ;
VAL_ 129 ACU_XPowerModCfg 15 " Reserved" 14 " Reserved" 13 " Reserved" 12 " Reserved" 11 " Reserved" 10 " Reserved" 9 " Reserved" 8 " Reserved" 7 " Reserved" 6 " Reserved" 5 " Reserved" 4 "Sport+ mode" 3 "Sport mode" 2 "ECO mode" 1 "Normal mode" 0 "No command" ;
VAL_ 129 ACU_CDCStyleCfg 7 "Not used" 6 "Not used" 5 "Not used" 4 "Invalid" 3 "Sport" 2 "Normal" 1 "Comfort" 0 "No Command" ;
VAL_ 129 ACU_PAS_ButtonPress 1 "Press" 0 "Not press" ;
VAL_ 129 ACU_DriveMode 15 "Not used" 14 "Not used" 13 "Not used" 12 "Not used" 11 "Not used" 10 " ATS_Snow" 9 " ATS_Mud" 8 " ATS_Sand" 7 " Offroad mode" 6 " AI mode" 5 " Sport+ mode" 4 "Individual mode" 3 " Sport mode" 2 " Comfort mode" 1 " ECO Pro mode" 0 "No command" ;
VAL_ 129 ACU_HDCFuncSwCfg 3 "reserved" 2 "HDC on" 1 "HDC off" 0 " No command" ;
VAL_ 129 ACU_ESPFuncSwCfg 3 " TCS off &VDC off" 2 "TCS off" 1 "ESP on" 0 "No command" ;
VAL_ 129 ACU_ADB_FunCfg 3 "Not used" 2 "Active" 1 "Not active" 0 "No command" ;
VAL_ 129 ACU_AEBOff 2 "Off" 1 "On" 0 "No command" ;
VAL_ 129 ACU_FCWOff 2 "Off" 1 "On" 0 "No command" ;
VAL_ 129 ACU_FCWWarnDistanceCfg 3 "Far" 2 "Close" 1 "Normal" 0 "No command" ;
VAL_ 129 ACU_FCW_SeatbeltPretensionWarnCf 3 "Not used" 2 "Active" 1 "Not active" 0 "No command" ;
VAL_ 129 ACU_FCW_SeatVibrationWarnCfg 3 "Not used" 2 "Active" 1 "Not active" 0 "No command" ;
VAL_ 129 ACU_FCW_AcousticWarnCfg 3 "Not used" 2 "Active" 1 "Not active" 0 "No command" ;
VAL_ 129 ACU_ACC_StyleCfg 3 "Sport" 2 "Comfortable" 1 "Standard" 0 "No command" ;
VAL_ 129 ACU_EPB_AutoModeCfg 3 "Not used" 2 "Auto mode ON" 1 "Auto mode OFF" 0 "No command" ;
VAL_ 129 ACU_EPS_StyleCfg 3 "Sport" 2 "Light" 1 "Comfort" 0 "No command" ;
VAL_ 62 ACU_BCM_RLSAutoSRWinCloseCfgSt 3 "Not used" 2 "Active" 1 "Not active" 0 "No command" ;
VAL_ 62 ACU_BCM_AutoSRWinCloseCfgSt 3 "Not used" 2 "Active" 1 "Not active" 0 "No command" ;
VAL_ 62 ACU_BCM_HeadlightDelayCfgSt 3 "Not used" 2 "Active" 1 "Not active" 0 "No command" ;
VAL_ 62 ACU_AVAS_SwitchCfgReq 3 "Not used" 2 "ON" 1 "OFF" 0 "No command" ;
VAL_ 62 ACU_BCM_BCVehUnlockReq 3 "Not used" 2 "Enable" 1 "Disable" 0 "No command" ;
VAL_ 62 ACU_BCM_BCVehLockReq 3 "Not used" 2 "VehUnlockReq" 1 "VehLockReq" 0 "No command" ;
VAL_ 62 ACU_BCM_BCAutoDomeLightCtrl 3 "Not used" 2 "enable" 1 "disable" 0 "no command" ;
VAL_ 62 ACU_ICM_TripReset 1 "reset" 0 "No reset" ;
VAL_ 62 ACU_RearSeatBeltWarnCfg 1 "on" 0 "off" ;
VAL_ 62 ACU_FuelEcoDistUnitDispSt 3 "Reversed" 2 "mpg(US),m" 1 "mpg(GB),m" 0 "L/100km,km" ;
VAL_ 62 ACU_PrUnitDispCfg 3 "Psi" 2 "Bar" 1 "kPa" 0 "No command" ;
VAL_ 62 ACU_TempUnitDispCfg 3 "Reserved" 2 "℉" 1 "℃" 0 "No command" ;
VAL_ 62 ACU_PEPS_IdInVeWarningCfg 3 "Not used" 2 "Active" 1 "Not active" 0 "No command" ;
VAL_ 62 ACU_MultiIDManageReq 15 "Reserved" 14 "Reserved" 13 "Reserved" 12 "Reserved" 11 "Reserved" 10 "Reserved" 9 "Reserved" 8 "Reserved" 7 "Reserved" 6 "Unbundle Request" 5 "Bundle NFC ID Request" 4 "Bundle BLE ID Request" 3 "Bundle Fob ID Request" 2 "Delete AUID" 1 "New AUID" 0 "No request" ;
VAL_ 62 ACU_BCM_AutoWiperCfg 3 "Not used" 2 "Auto" 1 "Intermittent" 0 "No Command" ;
VAL_ 62 ACU_BCM_IALFuncCfg 3 "Not used" 2 "Active" 1 "Not active" 0 "No command" ;
VAL_ 62 ACU_BCMHornCfg 3 "Not used" 2 "Active" 1 "Not active" 0 "No command" ;
VAL_ 62 ACU_BCM_DTRLFuncCfg 3 "Not used" 2 "Active" 1 "Not active" 0 "No command" ;
VAL_ 62 ACU_BCM_RGearEnableRearWipeCfg 3 "Not used" 2 "Active" 1 "Not active" 0 "No command" ;
VAL_ 62 ACU_BCM_FrontWiperSerPstFuncCfg 3 "Not used" 2 "Active" 1 "Not active" 0 "No command" ;
VAL_ 62 ACU_BCM_FrontWiperSerPstReq 1 "Request" 0 "No command" ;
VAL_ 62 ACU_BCM_AutoLightSnsCfg 7 "Not used" 6 "Not used" 5 "Not used" 4 "Not used" 3 "Low sensitivity" 2 "Medium sensitivity" 1 "High sensitivity" 0 "No command" ;
VAL_ 62 ACU_BCM_FollowMeHomeCfg 3 "Low beam and rear fog lamp" 2 "Only low beam" 1 "Not active" 0 "No command" ;
VAL_ 62 ACU_BCMAutoUnlockCfg 3 "Not used" 2 "Active" 1 "Not active" 0 "No command" ;
VAL_ 62 ACU_BCMSpdAutoLockCfg 3 "Not used" 2 "Active" 1 "Not active" 0 "No command" ;
VAL_ 62 ACU_BCMRemoteUnlockCfg 3 "Not used" 2 "Only driver door" 1 "All doors" 0 "No command" ;
VAL_ 62 ACU_BCM_FogLampTurnCfg 3 "Not used" 2 "Active" 1 "Not active" 0 "No command" ;
VAL_ 62 ACU_BCM_RemoteCtrlFDMRMCfg 3 "Not used" 2 "Active" 1 "Not active" 0 "No command" ;
VAL_ 61 ACU_PEPS_KickSnsCfg 3 "Not used" 2 "Active" 1 "Not active" 0 "No command" ;
VAL_ 61 ACU_PEPS_MaxTeleEngTimerCfg 63 "No command" 62 "Reserved" 61 "Reserved" 60 "Reserved" 59 "Reserved" 58 "Reserved" 57 "Reserved" 56 "Reserved" 55 "Reserved" 54 "Reserved" 53 "Reserved" 52 "Reserved" 51 "Reserved" 50 "Reserved" 49 "Reserved" 48 "Reserved" 47 "Reserved" 46 "Reserved" 45 "Reserved" 44 "Reserved" 43 "Reserved" 42 "Reserved" 41 "Reserved" 40 "Reserved" 39 "Reserved" 38 "Reserved" 37 "Reserved" 36 "Reserved" 35 "Reserved" 34 "Reserved" 33 "Reserved" 32 "Reserved" 31 "Reserved" ;
VAL_ 61 ACU_PEPS_OffCfg 3 "Not used" 2 "Active" 1 "Not active" 0 "No command" ;
VAL_ 61 ACU_PEPS_MaxTeleIGNOnTimerCfg 63 "No command" 62 "Reserved" 61 "Reserved" 60 "Reserved" 59 "Reserved" 58 "Reserved" 57 "Reserved" 56 "Reserved" 55 "Reserved" 54 "Reserved" 53 "Reserved" 52 "Reserved" 51 "Reserved" 50 "Reserved" 49 "Reserved" 48 "Reserved" 47 "Reserved" 46 "Reserved" 45 "Reserved" 44 "Reserved" 43 "Reserved" 42 "Reserved" 41 "Reserved" 40 "Reserved" 39 "Reserved" 38 "Reserved" 37 "Reserved" 36 "Reserved" 35 "Reserved" 34 "Reserved" 33 "Reserved" 32 "Reserved" 31 "Reserved" ;
VAL_ 61 ACU_PEPSAPUCfg 3 "Not used" 2 "Active" 1 "Not active" 0 "No command" ;
VAL_ 61 ACU_PEPSWALCfg 3 "Not used" 2 "Active" 1 "Not active" 0 "No command" ;
VAL_ 61 ACU_ICM_LanguageCfg 3 "Not used" 2 "English" 1 "Chinese" 0 "No command" ;
VAL_ 61 ACU_ICM_TimeModeCfg 3 "Not used" 2 "12h mode" 1 "24h mode" 0 "No command" ;
VAL_ 61 ACU_ICM_WarnSoundVolCfg 3 "High" 2 "Middle" 1 "Low" 0 "No command" ;
VAL_ 61 ACU_ICM_SpdWarnCfg 31 "No command" 30 "Reserved" 29 "Reserved" 28 "Reserved" 27 "Reserved" 26 "Reserved" 25 "Reserved" 24 "Reserved" 23 "Reserved" 22 "Reserved" 21 "Reserved" ;
VAL_ 61 ACU_HVACF_AutoDefCfg 7 "Not used" 6 "Not used" 5 "Not used" 4 "Low sensitivity" 3 "Normal sensitivity" 2 "High sensitivity" 1 "Off" 0 "No command" ;
VAL_ 61 ACU_HVACF_AQSCfg 3 "Low sensitivity" 2 "Normal sensitivity" 1 "High sensitivity" 0 "No command" ;
VAL_ 61 ACU_PEPSSATOCfg 3 "SATO function  and sound reminder active" 2 "SATO function Active" 1 "Not active" 0 "No command" ;
VAL_ 61 ACU_PEPS_WELCfg 3 "Not used" 2 "Active" 1 "Not active" 0 "No command" ;
VAL_ 61 ACU_BCMOSRMAutoFoldCfg 3 "Not used" 2 "Active" 1 "Not active" 0 "No command" ;
VAL_ 61 ACU_MSM_KeyRecognitionCfg 3 "Not used" 2 "Active" 1 "Not active" 0 "No command" ;
VAL_ 61 ACU_MSMWelcomeFuncCfg 3 "Not used" 2 "Active" 1 "Not active" 0 "No command" ;
VAL_ 61 ACU_RRHVSMAutoModeCfg 3 "Not used" 2 "Auto mode ON" 1 "Auto mode OFF" 0 "No command" ;
VAL_ 61 ACU_RLHVSMAutoModeCfg 3 "Not used" 2 "Auto mode ON" 1 "Auto mode OFF" 0 "No command" ;
VAL_ 61 ACU_FRHVSMAutoModeCfg 3 "Not used" 2 "Auto mode ON" 1 "Auto mode OFF" 0 "No command" ;
VAL_ 61 ACU_FLHVSMAutoModeCfg 3 "Not used" 2 "Auto mode ON" 1 "Auto mode OFF" 0 "No command" ;
VAL_ 61 ACU_HVACF_IonModeCfg 3 "Not used" 2 "ON" 1 "OFF" 0 "No command" ;
VAL_ 61 ACU_HVACF_ComfortCfg 3 "Fast" 2 "Normal" 1 "Soft" 0 "No command" ;
VAL_ 61 ACU_HVACFAirCirCfg 3 "Not used" 2 "Manual air circulation" 1 "Auto air circulation" 0 "No command" ;
VAL_ 61 ACU_HVACF_ACCfg 3 "Not used" 2 "A/C auto on turn off" 1 "A/C auto on turn on" 0 "No command" ;
VAL_ 821 ACU_HUD_OffSt 3 "Reserved" 2 "Active" 1 "Not active" 0 "no command" ;
VAL_ 821 ACU_TELBcallReq 3 "Key failure" 2 "Long release" 1 "Short release" 0 "Not active" ;
VAL_ 821 ACU_HUDADASCruiseDisReq 3 "Reserved" 2 "Active" 1 "Not active" 0 "no command" ;
VAL_ 821 ACU_HUD_NAV 3 "Reserved" 2 "Active" 1 "Not active" 0 "no command" ;
VAL_ 821 ACU_HUDADASTSRDisReq 3 "Reserved" 2 "Active" 1 "Not active" 0 "no command" ;
VAL_ 821 ACU_SVMViewPosReq 15 "Request to cancel SVM" 14 "Not used" 13 "Not used" 12 "Not used" 11 "Not used" 10 "Not used" 9 "Not used" 8 "Not used" 7 "Not used" 6 "Vertical parking" 5 "Parallel parking" 4 "Right_front view and front view" 3 "Enlarge rear view" 2 "Around view and rear view" 1 "Around view and front view" 0 "No command" ;
VAL_ 821 ACU_ModeChangeInf 1 "Change" 0 "Not change" ;
VAL_ 821 ACU_TeleModeActSt 3 "Not used" 2 "BT out" 1 "BT in" 0 "Not active" ;
VAL_ 821 ACU_CallMuteModeAct 1 "Active" 0 "Not active" ;
VAL_ 821 ACU_SetupConfig 3 "Not used" 2 "Not used" 1 "Active" 0 "Not active" ;
VAL_ 821 ACU_MusicSt 1 "On" 0 "Off" ;
VAL_ 821 ACU_KeyREWSt 3 "Key failure" 2 "Long release" 1 "Short release" 0 "Not active" ;
VAL_ 821 ACU_KeyFFWSt 3 "Key failure" 2 "Long release" 1 "Short release" 0 "Not active" ;
VAL_ 821 ACU_Key6St 3 "Key failure" 2 "Long release" 1 "Short release" 0 "Not active" ;
VAL_ 821 ACU_Key5St 3 "Key failure" 2 "Long release" 1 "Short release" 0 "Not active" ;
VAL_ 821 ACU_CallAnswerMode 1 "Hands-free" 0 "Private" ;
VAL_ 821 ACU_PhoneCallReq 7 "Not used" 6 "Calls over" 5 "Hang up" 4 "On the phone" 3 "Answer calls" 2 "Connecting" 1 "Incoming telegram" 0 "Not active" ;
VAL_ 821 ACU_Key4St 3 "Key failure" 2 "Long release" 1 "Short release" 0 "Not active" ;
VAL_ 821 ACU_Key3St 3 "Key failure" 2 "Long release" 1 "Short release" 0 "Not active" ;
VAL_ 821 ACU_Key2St 3 "Key failure" 2 "Long release" 1 "Short release" 0 "Not active" ;
VAL_ 821 ACU_Key1St 3 "Key failure" 2 "Long release" 1 "Short release" 0 "Not active" ;
VAL_ 814 ACU_IFC_NaviNewIcon 15 "not used" 14 "tunnel" 13 "toll station" 12 "service area" 11 "roundabout exit" 10 "roundabout entrance" 9 "go straight" 8 "right u-turn" 7 "left u-turn" 6 "right rear" 5 "left rear" 4 "right front" 3 "left front" 2 "right" 1 "left" 0 "unknown" ;
VAL_ 814 ACU_IFC_OfframpSt 1 "Off-ramp" 0 "Not off-ramp" ;
VAL_ 814 ACU_IFC_ZoneCode 7 "Not sued" 6 "Not sued" 5 "Not sued" 4 "Not sued" 3 "Not sued" 2 "Not sued" 1 "China" 0 "Not used" ;
VAL_ 814 ACU_IFC_NaviSt 3 "Failure" 2 "Navigate" 1 "Cruise" 0 "Unknown" ;
VAL_ 814 ACU_IFC_NaviCorp 7 "not used" 6 "not used" 5 "not used" 4 "Ruitu Map" 3 "Baidu Map" 2 "Tescent Map" 1 "Gaode Map" 0 "unknown" ;
VAL_ 814 ACU_IFC_SpeedLimtType 15 "Not used" 14 "Not used" 13 "Not used" 12 "Not used" 11 "Not used" 10 "Not used" 9 "Not used" 8 "Not used" 7 "Not used" 6 "Not used" 5 "Not used" 4 "Not used" 3 "Not used" 2 " Interval speed detectionlimit" 1 " Speed limit camera detection" 0 " Not specific" ;
VAL_ 814 ACU_IFC_RoadType 15 "Not used" 14 "Not used" 13 "Not used" 12 "Not used" 11 "Not used" 10 "Non-Navigation Road" 9 " Normal urban road" 8 " Secondary urban road" 7 " Major urban road" 6 " City express way" 5 " Village road" 4 " County road" 3 " Provincial road" 2 "National road" 1 "High way" 0 "unknown" ;
VAL_ 814 ACU_IFC_SpeedLimitUnit 3 "Not used" 2 "Miles/h" 1 "Km/h" 0 "Not used" ;
VAL_ 849 ACU_CurrentSource 31 "Not used" 30 "Not used" 29 "Not used" 28 "Not used" 27 "Not used" 26 "Not used" 25 "Not used" 24 "Online radio" 23 "Online music" 22 "Carlife" 21 "Carplay" 20 "LW" 19 "MW" 18 "OIRT" 17 "AM2" 16 "AM1" 15 "AM" 14 "FM3" 13 "FM2" 12 "FM1" 11 "FM" 10 "G-Link" 9 "Not used" 8 "Not used" 7 "Phone" 6 "BT music" 5 "SD" 4 "Aux" 3 "iPod" 2 "USB" 1 "CD" 0 "OFF" ;
VAL_ 849 ACU_MediaChangeFlag 1 "Request" 0 "Not request" ;
VAL_ 849 ACU_SearchStationMode 3 "SCAN" 2 "AST" 1 "Normal" 0 "Not active" ;
VAL_ 945 ACU_ICM_SynchDriveMode 7 "Reverse" 6 "Reverse" 5 "Reverse" 4 "Reverse" 3 "SPORT" 2 "ECO" 1 "Normal" 0 "No Command" ;
VAL_ 945 ACU_ICM_SynchDispID 15 "Reverse" 14 "Reverse" 13 "Reverse" 12 "Reverse" 11 "Reverse" 10 "Reverse" 9 "NightView" 8 "Navi+Warning" 7 "Phone-Link" 6 "Phone" 5 "Media" 4 "Vehicle state" 3 "Vehicle Info" 2 "Menu" 1 "Navi" 0 "Invalid（Include power on/offanimation，）" ;
VAL_ 945 ACU_APP_PhoneReady 0 " ACU phone APP not ready" 1 " ACU phone APP ready" ;
VAL_ 945 ACU_APP_NaviReady 0 " ACU navi APP not ready" 1 " ACU navi APP ready" ;
VAL_ 945 ACU_APP_MeadiaReady 0 " ACU media APP not ready" 1 " ACU media APP ready" ;
VAL_ 945 ACU_SystemReady 0 " ACU system not ready" 1 " ACU system ready" ;
VAL_ 945 ACU_PhoneType 7 "Not used" 6 "Not used" 5 "Not used" 4 "Not used" 3 "B-Call" 2 "E-Call" 1 "BT Phone" 0 "Not active" ;
VAL_ 945 ACU_PhoneSt 7 "Not used" 6 "Not used" 5 "Miss call" 4 "Call over" 3 "On the phone" 2 "Connecting" 1 "Incoming telegram" 0 "Npt active" ;
VAL_ 921 ACU_NaviDestDistUnit 3 "Mile" 2 "Kilometer" 1 "Meter" 0 "Not used" ;
VAL_ 921 ACU_NaviSt 7 "Not used" 6 "Not used" 5 "Not used" 4 "Navigation over" 3 "Navigating" 2 "NavigationStart" 1 "Nvatigation planning" 0 "Not navigated" ;
VAL_ 830 ACU_NaviDistUnit 3 "Mile" 2 "Kilometer" 1 "Meter" 0 "Not used" ;
VAL_ 830 ACU_NaviRoadChangeFlag 1 "Request" 0 "Not request" ;
VAL_ 825 ACU_GPSSignalSt 1 "Have signal" 0 "No signal" ;
VAL_ 825 ACU_SeaLevel 1 "Above sea level" 0 "Below sea level" ;
VAL_ 131 ACU_RCWTypeReqCfg 3 "Hazard Lamp and Sound" 2 "Sound" 1 "Hazard Lamp" 0 "No command" ;
VAL_ 131 ACU_DragModeReq 2 " Drag Mode Off" 1 "Drag Mode open" 0 "no command" ;
VAL_ 131 ACU_FaceIDSwitch 3 "Not used" 2 "On" 1 "Off" 0 "No command" ;
VAL_ 131 ACU_FaceIDQuit 1 "Quit request" 0 "No command" ;
VAL_ 131 ACU_VerifyTriger 15 "Reserved" 14 "Reserved" 13 "Reserved" 12 "Reserved" 11 "Reserved" 10 "Reserved" 9 "Reserved" 8 "Verify AUID8" 7 "Verify AUID7" 6 "Verify AUID6" 5 "Verify AUID5" 4 "Verify AUID4" 3 "Verify AUID3" 2 "Verify AUID2" 1 "Verify AUID1" 0 "Default" ;
VAL_ 131 ACU_RegisterTriger 15 "Reserved" 14 "Reserved" 13 "Reserved" 12 "Reserved" 11 "Reserved" 10 "Reserved" 9 "Reserved" 8 "Register AUID8" 7 "Register AUID7" 6 "Register AUID6" 5 "Register AUID5" 4 "Register AUID4" 3 "Register AUID3" 2 "Register AUID2" 1 "Register AUID1" 0 "Default" ;
VAL_ 131 ACU_FCTA_TypeReqCfg 3 "brake and Warning" 2 "Warning" 1 "brake" 0 "No command" ;
VAL_ 131 ACU_RCTA_TypeReqCfg 3 "brake and Warning" 2 "Warning" 1 "brake" 0 "No command" ;
VAL_ 131 ACU_RAWCfg 3 "Not used" 2 "Active" 1 "Not active" 0 "No command" ;
VAL_ 131 ACU_FCTACfg 3 "Not used" 2 "Active" 1 "Not active" 0 "No command" ;
VAL_ 131 ACU_ELKCfg 3 "Not used" 2 "Active" 1 "Not active" 0 "No command" ;
VAL_ 131 ACU_WCM_SwitchStCfg 3 "Not used" 2 "Active" 1 "Not active" 0 "No command" ;
VAL_ 130 ACU_ADASWarnTypeSwitch 3 " Both" 2 " Seat vibration" 1 " Sound" 0 " No command" ;
VAL_ 130 ACU_HWA_SwitchReq 3 "Not used" 2 "On" 1 "Off" 0 "No command" ;
VAL_ 130 ACU_RAEBcfg 3 "Not used" 2 "On" 1 "Off" 0 "No command" ;
VAL_ 130 ACU_TSR_AudioWarnReq 3 "Not used" 2 "On" 1 "Off" 0 "No command" ;
VAL_ 130 ACU_DMSMode 7 "not used" 6 "not used" 5 "not used" 4 "not used" 3 "fatigue and distraction" 2 "distraction" 1 "Fatigue" 0 "No command" ;
VAL_ 130 ACU_DMSSwitch 3 "not used" 2 "off" 1 "on" 0 "No command" ;
VAL_ 130 ACU_iACC_SwitchReq 3 "Not used" 2 "On" 1 "Off" 0 "No command" ;
VAL_ 130 ACU_DOWCfg 3 "Reserved" 2 "ON Request " 1 "OFF Request" 0 "No Action " ;
VAL_ 130 ACU_RCTACfg 3 "Reserved" 2 "ON Request " 1 "OFF Request" 0 "No Action " ;
VAL_ 130 ACU_BSDCfg 3 "Reserved" 2 "ON Request " 1 "OFF Request" 0 "No Action " ;
VAL_ 130 ACU_IFC_SpeedLimtValueType 3 "Not used" 2 "Evaluated value" 1 "Sign value" 0 "No command" ;
VAL_ 130 ACU_LKS_TypeReq 3 "Steering and Warning" 2 "Warning" 1 "Steering" 0 "No command" ;
VAL_ 130 ACU_HMA_SwitchReq 3 "Not used" 2 "Active" 1 "Not active" 0 "No command" ;
VAL_ 130 ACU_TSR_SwitchReq 3 "Not used" 2 "Active" 1 "Not active" 0 "No command" ;
VAL_ 130 ACU_LKS_Sensitivity 3 "Not used" 2 "High" 1 "Adaptive" 0 "No command" ;
VAL_ 130 ACU_IFC_CruiseModeCfg 3 "Not used" 2 "TJA-ICA Mode" 1 "ACC Mode" 0 "No command" ;
VAL_ 130 ACU_SVM_RightBlindViewReq 3 "Not used" 2 "Request right blind view to turn on" 1 "Request right blind view to turn off" 0 "No command" ;
VAL_ 130 ACU_SVM_LeftBlindViewReq 3 "Not used" 2 "Request left blind view to turn on" 1 "Request left blind view to turn off" 0 "No command" ;
VAL_ 130 ACU_LDW_WarmSnsCfg 3 "Delay" 2 "Self-adaption" 1 "Early" 0 "No command" ;
VAL_ 130 ACU_LDW_LKACfg 3 "Not used" 2 "Active" 1 "Not active" 0 "No command" ;
VAL_ 84 ACU_PCS_LadarTriggerSVMset 3 "Not used" 2 "Active" 1 "Not active" 0 "No command" ;
VAL_ 84 ACU_PCS_TurnFollowSet 3 "Not used" 2 "Active" 1 "Not active" 0 "No command" ;
VAL_ 84 ACU_PCS_ParkGearExitSet 3 "Not used" 2 "Active" 1 "Not active" 0 "No command" ;
VAL_ 84 ACU_PCS_TrajectoryLineSet 3 "Not used" 2 "Active" 1 "Not active" 0 "No command" ;
VAL_ 84 ACU_PCS_CurrentSceenSt 1 "Full Sceen" 0 "Half Sceen" ;
VAL_ 84 ACU_PCS_ScreenTouchSt 3 "Slither" 2 "Release" 1 "Press" 0 "No command" ;
VAL_ 84 ACU_PCS_ER_QuitConfirm 1 "Command" 0 "No command" ;
VAL_ 84 ACU_PCS_ER_EnterCmd 1 "Command" 0 "No command" ;
VAL_ 84 ACU_ER_FuncCfg 2 "Off" 1 "On" 0 "No command" ;
VAL_ 84 ACU_PCS_AdjParkPosCmd 7 "Not used" 6 "Not used" 5 "Confirm" 4 "Move right" 3 "Move left" 2 "Move down" 1 "Move up" 0 "No command" ;
VAL_ 84 ACU_PCS_SVM_PGSReturnCmd 1 "Command" 0 "No command" ;
VAL_ 84 ACU_PCS_SVM_SoundReminderCmd 1 "Command" 0 "No command" ;
VAL_ 84 ACU_PCS_SVM_ViewModeCmd 1 "Command" 0 "No command" ;
VAL_ 84 ACU_PCS_SVM_MODCmd 1 "Command" 0 "No command" ;
VAL_ 84 ACU_PCS_SVM_PGSCmd 1 "Command" 0 "No command" ;
VAL_ 84 ACU_PCS_SVM_SingleViewCmd 15 "Not used" 14 "Not used" 13 "Not used" 12 "Not used" 11 "Not used" 10 "Not used" 9 "Overlook view" 8 "Right view" 7 "Left view" 6 "Rear of right view" 5 "Rear of left view" 4 "Front of right view" 3 "Front of left view" 2 "Rear view" 1 "Front view" 0 "No command" ;
VAL_ 84 ACU_PCS_SVM_FunctionCmd 15 "Request to cancel " 14 "Not used" 13 "Vertical parking view(RVM)" 12 "Parallel parking view(RVM)" 11 "Rear view(RVM)" 10 "Vertical parking view(SVM)" 9 "Parallel parking view(SVM)" 8 "Parking guidance view(SVM)" 7 "Right blind spot view(SVM)" 6 "Left blind spot view (SVM)" 5 "Enlarge rear view(SVM)" 4 "Surround view and Rear view(SVM)" 3 "Enlarge front view(SVM)" 2 "Surround view and Front view(SVM)" 1 "HMI in transition(SVM)" 0 "No command" ;
VAL_ 158 ACU_PAAMode 15 "Reserved" 14 "Reserved" 13 "Reserved" 12 "Reserved" 11 "Reserved" 10 "RA Off" 9 "PAA Off" 8 "APA Off" 7 "PAA" 6 "Custom Slot" 5 "RA" 4 "PAVP" 3 "HAVP" 2 "RPA" 1 "APA" 0 "No Request" ;
